VERSION ""

NS_ :

BS_:

BU_: WCM4 WCM3 WCM2 WCM VPM VLM VKM VICM VECM VDM VCU_RTOS_ETH VCU_ENTRY_ETH VCU_AGVM_ETH VCU UVM UPM TIM TEST_TOOL_1 TCP_ETH TCP TCM TCCM SRR_SRR_ETH SRR_SRR SRR_SLR_ETH SRR_SLR SRR_RR SRR_RF_ETH SRR_RF SRR_LR_CR SRR_LF_ETH SRR_LF SIB SDM SCL SBZA_R SBZA_L SBM SAM_RR SAM_RF SAM_LR SAM_LF SAM_BH SADS RadioLow_ETH RadioLow RSI_RTOS_ETH RSI RDCM PTM PLCM PFCM PDR_ETH PDR PCM PA ODS2 ODS NVM MTCM_R MTCM_L MSM_RR MSM_P MSM_LR MSM_D MSB2 MSB1 MRCM_R MRCM_L MFC LRR_RR_ETH LRR_LR_ETH LRR_CF_ETH LRR LRL_CF_ETH LIB_48V LIB1 IPC_INT IPC_GP IPC ICS_Info ICCM HVAC_FP_R HVAC_FP_F HUD_CAN HDLM FPI_RTOS_ETH FPI FOPM FCM_LC FCM EPSb EPS_1 EPSRAb EPSRAa EPS EOCM_HC_Superset EOCM_HCP2 EOCM ELM ECP_X1 ECP_S2 ECP_S ECP_MC ECP_H3 ECP_H2 ECP_H1 ECP_E ECM EBCM DMS DEFC DCM CSM_ETH CSM_AV CSM CGM_OTA_ETH CGM BSM_MH BSM_HEV BSM BCM ARS ARB APA AOS AMP ALC AHS AHL_AFL ADIMb ADIMa ACP2_MCU

BO_ 1415 PDU_2157: 8 CGM
 SG_ ACCDrSlctdSpd : 5|12@0+ (0.0625,0) [0|255.938] "km/h" CSM,CSM_AV,IPC,IPC_INT,VCU
 SG_ ACCAutoStSpStat : 7|2@0+ (1,0) [0|3] "" CSM,CSM_AV,IPC,IPC_INT,VCU
 SG_ ACCSpdLimSgnUnt : 8|1@0+ (1,0) [0|1] "" IPC,IPC_INT,VCU
 SG_ ACCDrSlctdSpdIndOn : 9|1@0+ (1,0) [0|1] "" TCP,CSM,CSM_AV,IPC,IPC_INT,VCU
 SG_ ACCSpdLimSgnVal : 23|8@0+ (1,0) [0|255] "" IPC,IPC_INT,VCU
 SG_ FrwdImpMtgnOpSlctCstCrStVal : 26|3@0+ (1,0) [0|7] "" RadioLow,TCP,CSM,CSM_AV,VCU
 SG_ FrntPCMRspTypCstCrStVal : 29|3@0+ (1,0) [0|7] "" RadioLow,CSM,CSM_AV,VCU
 SG_ ACCSysSlctdMd : 31|2@0+ (1,0) [0|2] "" TCP,IPC,IPC_INT,VCU
 SG_ FrntPCMRspTypCstAvlFlg1 : 32|1@0+ (1,0) [0|1] "" RadioLow,CSM,CSM_AV,VCU
 SG_ AutoEmrgBrkgDsbldIndOn : 33|1@0+ (1,0) [0|1] "" CSM,CSM_AV,IPC,IPC_INT,VCU
 SG_ ACCGoNtfrChmEvntSt : 34|1@0+ (1,0) [0|1] "" IPC,IPC_INT,VCU
 SG_ AnmlWrnIndReq : 36|2@0+ (1,0) [0|2] "" IPC,IPC_INT,VCU
 SG_ FrwdVehAhdIndReq : 39|3@0+ (1,0) [0|5] "" TCP,CSM,CSM_AV,IPC,IPC_INT,VCU
 SG_ FrtPedtrnClsnMtgnAudAttnReqd : 40|1@0+ (1,0) [0|1] "" RadioLow,CSM,CSM_AV,VCU
 SG_ FrntPCMRspTypCstStAvl : 41|1@0+ (1,0) [0|1] "" RadioLow,CSM,CSM_AV,VCU
 SG_ FrntPCMRspTypCstAvlFlg7 : 42|1@0+ (1,0) [0|1] "" RadioLow,CSM,CSM_AV,VCU
 SG_ FrntPCMRspTypCstAvlFlg6 : 43|1@0+ (1,0) [0|1] "" RadioLow,CSM,CSM_AV,VCU
 SG_ FrntPCMRspTypCstAvlFlg5 : 44|1@0+ (1,0) [0|1] "" RadioLow,CSM,CSM_AV,VCU
 SG_ FrntPCMRspTypCstAvlFlg4 : 45|1@0+ (1,0) [0|1] "" RadioLow,CSM,CSM_AV,VCU
 SG_ FrntPCMRspTypCstAvlFlg3 : 46|1@0+ (1,0) [0|1] "" RadioLow,CSM,CSM_AV,VCU
 SG_ FrntPCMRspTypCstAvlFlg2 : 47|1@0+ (1,0) [0|1] "" RadioLow,CSM,CSM_AV,VCU
 SG_ FrwdImpMtgnOpSlctCstAvlFlg7 : 48|1@0+ (1,0) [0|1] "" RadioLow,TCP,CSM,CSM_AV,VCU
 SG_ FrwdImpMtgnOpSlctCstAvlFlg6 : 49|1@0+ (1,0) [0|1] "" RadioLow,TCP,CSM,CSM_AV,VCU
 SG_ FrwdImpMtgnOpSlctCstAvlFlg5 : 50|1@0+ (1,0) [0|1] "" RadioLow,TCP,CSM,CSM_AV,VCU
 SG_ FrwdImpMtgnOpSlctCstAvlFlg4 : 51|1@0+ (1,0) [0|1] "" RadioLow,TCP,CSM,CSM_AV,VCU
 SG_ FrwdImpMtgnOpSlctCstAvlFlg3 : 52|1@0+ (1,0) [0|1] "" RadioLow,TCP,CSM,CSM_AV,VCU
 SG_ FrwdImpMtgnOpSlctCstAvlFlg2 : 53|1@0+ (1,0) [0|1] "" RadioLow,TCP,CSM,CSM_AV,VCU
 SG_ FrwdImpMtgnOpSlctCstAvlFlg1 : 54|1@0+ (1,0) [0|1] "" RadioLow,TCP,CSM,CSM_AV,VCU
 SG_ FrwdClsnAlrtImntAlrtAudAttnReqd : 55|1@0+ (1,0) [0|1] "" RadioLow,CSM,CSM_AV,VCU
 SG_ GoNotfrCstAvlFlg7 : 56|1@0+ (1,0) [0|1] "" RadioLow,CSM,CSM_AV,VCU
 SG_ GoNotfrCstAvlFlg6 : 57|1@0+ (1,0) [0|1] "" RadioLow,CSM,CSM_AV,VCU
 SG_ GoNotfrCstAvlFlg5 : 58|1@0+ (1,0) [0|1] "" RadioLow,CSM,CSM_AV,VCU
 SG_ GoNotfrCstAvlFlg4 : 59|1@0+ (1,0) [0|1] "" RadioLow,CSM,CSM_AV,VCU
 SG_ GoNotfrCstAvlFlg3 : 60|1@0+ (1,0) [0|1] "" RadioLow,CSM,CSM_AV,VCU
 SG_ GoNotfrCstAvlFlg2 : 61|1@0+ (1,0) [0|1] "" RadioLow,CSM,CSM_AV,VCU
 SG_ GoNotfrCstAvlFlg1 : 62|1@0+ (1,0) [0|1] "" RadioLow,CSM,CSM_AV,VCU
 SG_ FrwdImpMtgnOpSlctCstStAvl : 63|1@0+ (1,0) [0|1] "" RadioLow,TCP,CSM,CSM_AV,VCU

BO_ 73 PDU_2226: 6 CGM
 SG_ PrplSysSndEnhtAdjdEngTrqEst : 7|12@0+ (0.5,-848) [-848|1199.5] "Nm" AMP,VCU
 SG_ PrplSysSndEnhtAdjdEngTrqEst_Inv : 11|1@0+ (1,0) [0|1] "" AMP,VCU

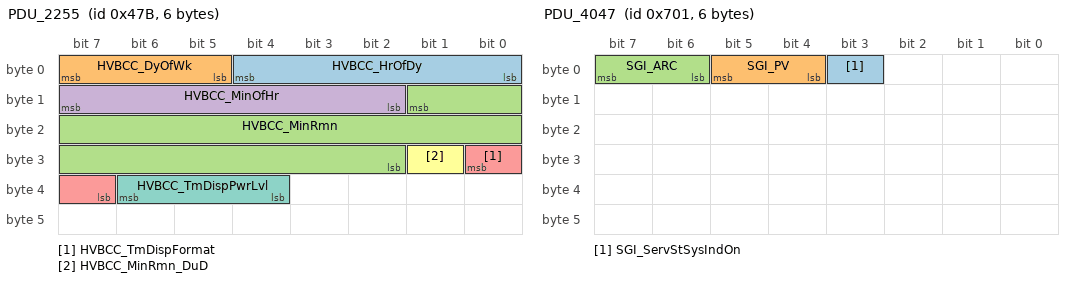
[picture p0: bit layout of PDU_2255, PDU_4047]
BO_ 1147 PDU_2255: 6 CGM
 SG_ HVBCC_HrOfDy : 4|5@0+ (1,0) [0|31] "h" TCP,CSM,CSM_AV,IPC,IPC_INT,VCU
 SG_ HVBCC_DyOfWk : 7|3@0+ (1,0) [0|7] "" TCP,CSM,CSM_AV,IPC,IPC_INT,VCU
 SG_ HVBCC_MinRmn : 9|16@0+ (1,0) [0|65535] "min" TCP,CSM,CSM_AV,IPC,IPC_INT,VCU
 SG_ HVBCC_MinOfHr : 15|6@0+ (1,0) [0|63] "min" TCP,CSM,CSM_AV,IPC,IPC_INT,VCU
 SG_ HVBCC_TmDispFormat : 24|2@0+ (1,0) [0|2] "" CSM,CSM_AV,IPC,IPC_INT,VCU
 SG_ HVBCC_MinRmn_DuD : 25|1@0+ (1,0) [0|1] "" CSM,CSM_AV,IPC,IPC_INT,VCU
 SG_ HVBCC_TmDispPwrLvl : 38|3@0+ (1,0) [0|4] "" TCP,CSM,CSM_AV,IPC,IPC_INT,VCU

BO_ 1349 PDU_2275: 8 CGM
 SG_ ACCAutoSetSpdCstCurrSetVal : 0|3@0+ (1,0) [0|2] "" VCU
 SG_ ACCAutoSetSpdCstAvlFlg7 : 1|1@0+ (1,0) [0|1] "" VCU
 SG_ ACCAutoSetSpdCstAvlFlg6 : 2|1@0+ (1,0) [0|1] "" VCU
 SG_ ACCAutoSetSpdCstAvlFlg5 : 3|1@0+ (1,0) [0|1] "" VCU
 SG_ ACCAutoSetSpdCstAvlFlg4 : 4|1@0+ (1,0) [0|1] "" VCU
 SG_ ACCAutoSetSpdCstAvlFlg3 : 5|1@0+ (1,0) [0|1] "" VCU
 SG_ ACCAutoSetSpdCstAvlFlg2 : 6|1@0+ (1,0) [0|1] "" VCU
 SG_ ACCAutoSetSpdCstAvlFlg1 : 7|1@0+ (1,0) [0|1] "" VCU
 SG_ LnKpAsstVirtCtlLngPrssDctvtnTm : 10|6@0+ (0.1,0) [0|6.3] "seconds" VCU
 SG_ LnKpAsstVirtCtlAval : 11|1@0+ (1,0) [0|1] "" VCU
 SG_ ACCAutoSetSpdUnvIndOn : 12|1@0+ (1,0) [0|1] "" IPC,IPC_INT,VCU
 SG_ ACCAutoSetSpdCstSetAval : 13|1@0+ (1,0) [0|1] "" VCU
 SG_ FCASensCstAvlFlg1 : 16|1@0+ (1,0) [0|1] "" VCU
 SG_ FCASensCstCurrSetVal : 19|3@0+ (1,0) [0|4] "" VCU
 SG_ FCASensCstSetAval : 20|1@0+ (1,0) [0|1] "" VCU
 SG_ BlndZnStrgAsstVirtCtlAval : 24|1@0+ (1,0) [0|1] "" VCU
 SG_ BlndZnStrgAsstVirtUserCtlAllwd : 25|1@0+ (1,0) [0|1] "" VCU
 SG_ FCASensCstAvlFlg7 : 26|1@0+ (1,0) [0|1] "" VCU
 SG_ FCASensCstAvlFlg6 : 27|1@0+ (1,0) [0|1] "" VCU
 SG_ FCASensCstAvlFlg5 : 28|1@0+ (1,0) [0|1] "" VCU
 SG_ FCASensCstAvlFlg4 : 29|1@0+ (1,0) [0|1] "" VCU
 SG_ FCASensCstAvlFlg3 : 30|1@0+ (1,0) [0|1] "" VCU
 SG_ FCASensCstAvlFlg2 : 31|1@0+ (1,0) [0|1] "" VCU
 SG_ TrfcJamAsstVirtCtlAllwd : 33|1@0+ (1,0) [0|1] "" VCU
 SG_ LnDtnWrnSpprssnVrtCtlCurrSltnVl : 35|2@0+ (1,0) [0|2] "" VCU
 SG_ LnDtnWrnSpprssnVirtCtlAval : 36|1@0+ (1,0) [0|1] "" VCU
 SG_ LnDtnWrnSpprssnVirtUserCtlAllwd : 37|1@0+ (1,0) [0|1] "" VCU
 SG_ BlndZnStrgAsstVrtCtlCurrSltnVl : 39|2@0+ (1,0) [0|2] "" VCU

BO_ 2010 PDU_2281: 8 CGM
 SG_ RrStrgModeVirtCtlAval : 6|1@0+ (1,0) [0|1] "" VCU
 SG_ RrStrgModeSmrtCtlIcnReqd : 7|1@0+ (1,0) [0|1] "" VCU

BO_ 1275 PDU_3043: 8 CGM
 SG_ EPBStpOnBrkToRelPrkBrkIndReq : 0|3@0+ (1,0) [0|7] "" CSM,CSM_AV,IPC,IPC_INT,VCU
 SG_ VehStbEnhcmntCustAv : 1|1@0+ (1,0) [0|1] "" TCP,IPC,IPC_INT,VCU
 SG_ VehStbEnhcmntCurStat : 2|1@0+ (1,0) [0|1] "" PDR,TCP,CSM,CSM_AV,IPC,IPC_INT,VCU
 SG_ VehStbCompMdCustAv : 3|1@0+ (1,0) [0|1] "" TCP,IPC,IPC_INT,VCU
 SG_ VehStbCompMdCurStat : 4|1@0+ (1,0) [0|1] "" TCP,IPC,IPC_INT,VCU
 SG_ TrcCntrlSysTmpDisReqIO : 5|1@0+ (1,0) [0|1] "" IPC,IPC_INT,VCU
 SG_ TCSCustAv : 6|1@0+ (1,0) [0|1] "" IPC,IPC_INT,VCU
 SG_ TCSCurStat : 7|1@0+ (1,0) [0|1] "" PDR,TCP,CSM,CSM_AV,IPC,IPC_INT,VCU
 SG_ OffRdMdActvAerodynsVisDispVal : 10|3@0+ (1,0) [0|7] "" RadioLow,CSM,CSM_AV,VCU
 SG_ ElecPrkBrkSysDisIndReq : 13|3@0+ (1,0) [0|7] "" CSM,CSM_AV,IPC,IPC_INT,VCU
 SG_ OffRdMdESCVisDispVal : 17|3@0+ (1,0) [0|7] "" RadioLow,CSM,CSM_AV,VCU
 SG_ OffRdMdDrvlnVisDispVal : 20|3@0+ (1,0) [0|7] "" RadioLow,CSM,CSM_AV,VCU
 SG_ OffRdMdBrkPedVisDispVal : 23|3@0+ (1,0) [0|7] "" RadioLow,CSM,CSM_AV,VCU
 SG_ OffRdMdSndVisDispVal : 24|3@0+ (1,0) [0|7] "" RadioLow,CSM,CSM_AV,VCU
 SG_ OffRdMdRideHghtVisDispVal : 27|3@0+ (1,0) [0|7] "" RadioLow,CSM,CSM_AV,VCU
 SG_ OffRdMdPwrtrnVisDispVal : 30|3@0+ (1,0) [0|7] "" RadioLow,CSM,CSM_AV,VCU
 SG_ OffRdMdStrgVisDispVal : 34|3@0+ (1,0) [0|7] "" RadioLow,CSM,CSM_AV,VCU
 SG_ OffRdMdSpnsnVisDispVal : 37|3@0+ (1,0) [0|7] "" RadioLow,CSM,CSM_AV,VCU
 SG_ ESCInitIO : 40|1@0+ (1,0) [0|1] "" IPC,IPC_INT,VCU
 SG_ ESCCmptMdIO : 41|1@0+ (1,0) [0|1] "" IPC,IPC_INT,VCU
 SG_ TrlrBrkgSysProfSts : 44|3@0+ (1,0) [0|5] "" CSM,CSM_AV,VCU
 SG_ PerfMdMainMenuTy : 47|3@0+ (1,0) [0|7] "" RadioLow,CSM,CSM_AV,VCU
 SG_ TrlrBrkCnctdIndOn : 48|1@0+ (1,0) [0|1] "" IPC,IPC_INT,VCU
 SG_ SrvESCMdIO : 49|1@0+ (1,0) [0|1] "" TCP,IPC,IPC_INT,VCU
 SG_ ServTracCtlIndOn : 50|1@0+ (1,0) [0|1] "" TCP,IPC,IPC_INT,VCU
 SG_ RdcBrkgToAvoidOvrhtgIndOn : 51|1@0+ (1,0) [0|1] "" IPC,IPC_INT,VCU
 SG_ HillStrtAstActIO : 52|1@0+ (1,0) [0|1] "" CSM,CSM_AV,IPC,IPC_INT,VCU
 SG_ HillRollCntrlActIO : 53|1@0+ (1,0) [0|1] "" CSM,CSM_AV,IPC,IPC_INT,VCU
 SG_ ESCPrfMdIO : 54|1@0+ (1,0) [0|1] "" IPC,IPC_INT,VCU
 SG_ ESCOffIO : 55|1@0+ (1,0) [0|1] "" CSM,CSM_AV,IPC,IPC_INT,VCU
 SG_ BrkSysDrftModeUnvWrnIndReq : 60|2@0+ (1,0) [0|2] "" IPC,IPC_INT,VCU
 SG_ BrkSysDrftModeDispSts : 62|2@0+ (1,0) [0|3] "" IPC,IPC_INT,VCU
 SG_ BrkSysDrftModeSeltnIndOn : 63|1@0+ (1,0) [0|1] "" IPC,IPC_INT,VCU

BO_ 1274 PDU_3044: 8 CGM
 SG_ BrkPadLifeFrt : 6|7@0+ (1,0) [0|127] "%" TCP,VKM,CSM,CSM_AV,IPC,IPC_INT,VCU
 SG_ BrkPadLifeFrt_Inv : 7|1@0+ (1,0) [0|1] "" TCP,VKM,CSM,CSM_AV,IPC,IPC_INT,VCU
 SG_ BrkPadLifeRr : 14|7@0+ (1,0) [0|127] "%" TCP,VKM,CSM,CSM_AV,IPC,IPC_INT,VCU
 SG_ BrkPadLifeRr_Inv : 15|1@0+ (1,0) [0|1] "" TCP,VKM,CSM,CSM_AV,IPC,IPC_INT,VCU
 SG_ TowHaulMdBrkPedVisDispVal : 17|3@0+ (1,0) [0|7] "" RadioLow,CSM,CSM_AV,VCU
 SG_ TowHaulMdActvAerodynsVisDispVal : 20|3@0+ (1,0) [0|7] "" RadioLow,CSM,CSM_AV,VCU
 SG_ BrkTempStsIndReq : 23|3@0+ (1,0) [0|4] "" IPC,IPC_INT,VCU
 SG_ TowHaulMdPwrtrnVisDispVal : 24|3@0+ (1,0) [0|7] "" RadioLow,CSM,CSM_AV,VCU
 SG_ TowHaulMdESCVisDispVal : 27|3@0+ (1,0) [0|7] "" RadioLow,CSM,CSM_AV,VCU
 SG_ TowHaulMdDrvlnVisDispVal : 30|3@0+ (1,0) [0|7] "" RadioLow,CSM,CSM_AV,VCU
 SG_ TowHaulMdSndVisDispVal : 34|3@0+ (1,0) [0|7] "" RadioLow,CSM,CSM_AV,VCU
 SG_ TowHaulMdRideHghtVisDispVal : 37|3@0+ (1,0) [0|7] "" RadioLow,CSM,CSM_AV,VCU
 SG_ AutoHldActv : 40|1@0+ (1,0) [0|1] "" IPC,IPC_INT,VCU
 SG_ ABSActvIndOn : 41|1@0+ (1,0) [0|1] "" TCP,CSM,CSM_AV,IPC,IPC_INT,VCU
 SG_ TowHaulMdStrgVisDispVal : 44|3@0+ (1,0) [0|7] "" RadioLow,CSM,CSM_AV,VCU
 SG_ TowHaulMdSpnsnVisDispVal : 47|3@0+ (1,0) [0|7] "" RadioLow,CSM,CSM_AV,VCU
 SG_ BrkPadLifeRrRstAval : 50|1@0+ (1,0) [0|1] "" IPC,IPC_INT,VCU
 SG_ BrkPadLifeFrtRstAval : 51|1@0+ (1,0) [0|1] "" IPC,IPC_INT,VCU
 SG_ AutoHldServIndOn : 52|1@0+ (1,0) [0|1] "" IPC,IPC_INT,VCU
 SG_ AutoHldDsbldStBltIndOn : 53|1@0+ (1,0) [0|1] "" IPC,IPC_INT,VCU
 SG_ AutoHldDsbldDrOpnIndOn : 54|1@0+ (1,0) [0|1] "" IPC,IPC_INT,VCU
 SG_ AutoHldAppBrkPedIndOn : 55|1@0+ (1,0) [0|1] "" IPC,IPC_INT,VCU

BO_ 1491 PDU_3045: 8 CGM
 SG_ CustMdDrvlCstmCurSetVal : 1|3@0+ (1,0) [0|7] "" RadioLow,TCP,CSM,CSM_AV,VCU
 SG_ CustMdBrkPdlCstmCurSetVal : 4|3@0+ (1,0) [0|7] "" RadioLow,CSM,CSM_AV,VCU
 SG_ CustMdActAeroCstmCurSetVal : 7|3@0+ (1,0) [0|7] "" RadioLow,CSM,CSM_AV,VCU
 SG_ CustMdRideHghtCstmCurSetVal : 8|3@0+ (1,0) [0|7] "" RadioLow,CSM,CSM_AV,VCU
 SG_ CustMdPTCstmPndSetVal : 11|3@0+ (1,0) [0|7] "" RadioLow,CSM,CSM_AV,VCU
 SG_ CustMdPTCstmCurSetVal : 14|3@0+ (1,0) [0|7] "" RadioLow,CSM,CSM_AV,VCU
 SG_ CustMdSpnCstmCurSetVal : 18|3@0+ (1,0) [0|7] "" RadioLow,TCP,CSM,CSM_AV,VCU
 SG_ CustMdSndCstmCurSetVal : 21|3@0+ (1,0) [0|7] "" RadioLow,CSM,CSM_AV,VCU
 SG_ DisPrfMdRq : 25|3@0+ (1,0) [0|7] "" IPC,IPC_INT,VCU
 SG_ CustMdTrcStbCstmCurSetVal : 28|3@0+ (1,0) [0|7] "" RadioLow,CSM,CSM_AV,VCU
 SG_ CustMdStrCstmCurSetVal : 31|3@0+ (1,0) [0|7] "" RadioLow,TCP,CSM,CSM_AV,VCU
 SG_ PrsnlMdBrkPdlCstmCurSetVal : 32|3@0+ (1,0) [0|7] "" RadioLow,CSM,CSM_AV,VCU
 SG_ PrsnlMdActAeroCstmCurSetVal : 35|3@0+ (1,0) [0|7] "" RadioLow,CSM,CSM_AV,VCU
 SG_ ExtdHillStrtAstCustCurSetVal : 38|3@0+ (1,0) [0|7] "" RadioLow,CSM,CSM_AV,VCU
 SG_ PrsnlMdRideHghtCstmCurSetVal : 42|3@0+ (1,0) [0|7] "" RadioLow,CSM,CSM_AV,VCU
 SG_ PrsnlMdDrvlCstmCurSetVal : 45|3@0+ (1,0) [0|7] "" RadioLow,TCP,CSM,CSM_AV,VCU
 SG_ CustMdStrCstmSetAv : 48|1@0+ (1,0) [0|1] "" RadioLow,TCP,CSM,CSM_AV,VCU
 SG_ CustMdSpnCstmSetAv : 49|1@0+ (1,0) [0|1] "" RadioLow,TCP,CSM,CSM_AV,VCU
 SG_ CustMdSndCstmSetAv : 50|1@0+ (1,0) [0|1] "" RadioLow,CSM,CSM_AV,VCU
 SG_ CustMdRideHghtCstmSetAv : 51|1@0+ (1,0) [0|1] "" RadioLow,CSM,CSM_AV,VCU
 SG_ CustMdPTCstmSetAv : 52|1@0+ (1,0) [0|1] "" RadioLow,CSM,CSM_AV,VCU
 SG_ CustMdDrvlCstmSetAv : 53|1@0+ (1,0) [0|1] "" RadioLow,TCP,CSM,CSM_AV,VCU
 SG_ CustMdBrkPdlCstmSetAv : 54|1@0+ (1,0) [0|1] "" RadioLow,CSM,CSM_AV,VCU
 SG_ CustMdActAeroCstmSetAv : 55|1@0+ (1,0) [0|1] "" RadioLow,CSM,CSM_AV,VCU
 SG_ PrsnlMdSpnCstmSetAv : 56|1@0+ (1,0) [0|1] "" RadioLow,TCP,CSM,CSM_AV,VCU
 SG_ PrsnlMdSndCstmSetAv : 57|1@0+ (1,0) [0|1] "" RadioLow,CSM,CSM_AV,VCU
 SG_ PrsnlMdRideHghtCstmSetAv : 58|1@0+ (1,0) [0|1] "" RadioLow,CSM,CSM_AV,VCU
 SG_ PrsnlMdDrvlCstmSetAv : 59|1@0+ (1,0) [0|1] "" RadioLow,TCP,CSM,CSM_AV,VCU
 SG_ PrsnlMdBrkPdlCstmSetAv : 60|1@0+ (1,0) [0|1] "" RadioLow,CSM,CSM_AV,VCU
 SG_ PrsnlMdActAeroCstmSetAv : 61|1@0+ (1,0) [0|1] "" RadioLow,CSM,CSM_AV,VCU
 SG_ ExtdHillStrtAstCustSetAvl : 62|1@0+ (1,0) [0|1] "" RadioLow,CSM,CSM_AV,VCU
 SG_ CustMdTrcStbCstmSetAv : 63|1@0+ (1,0) [0|1] "" RadioLow,CSM,CSM_AV,VCU

BO_ 1882 PDU_3054: 8 CGM
 SG_ CustMdBrkPdlCstmAvFlg1 : 0|1@0+ (1,0) [0|1] "" RadioLow,CSM,CSM_AV,VCU
 SG_ CustMdActAeroCstmAvFlg7 : 1|1@0+ (1,0) [0|1] "" RadioLow,CSM,CSM_AV,VCU
 SG_ CustMdActAeroCstmAvFlg6 : 2|1@0+ (1,0) [0|1] "" RadioLow,CSM,CSM_AV,VCU
 SG_ CustMdActAeroCstmAvFlg5 : 3|1@0+ (1,0) [0|1] "" RadioLow,CSM,CSM_AV,VCU
 SG_ CustMdActAeroCstmAvFlg4 : 4|1@0+ (1,0) [0|1] "" RadioLow,CSM,CSM_AV,VCU
 SG_ CustMdActAeroCstmAvFlg3 : 5|1@0+ (1,0) [0|1] "" RadioLow,CSM,CSM_AV,VCU
 SG_ CustMdActAeroCstmAvFlg2 : 6|1@0+ (1,0) [0|1] "" RadioLow,CSM,CSM_AV,VCU
 SG_ CustMdActAeroCstmAvFlg1 : 7|1@0+ (1,0) [0|1] "" RadioLow,CSM,CSM_AV,VCU
 SG_ CustMdDrvlCstmAvFlg2 : 8|1@0+ (1,0) [0|1] "" RadioLow,TCP,CSM,CSM_AV,VCU
 SG_ CustMdDrvlCstmAvFlg1 : 9|1@0+ (1,0) [0|1] "" RadioLow,TCP,CSM,CSM_AV,VCU
 SG_ CustMdBrkPdlCstmAvFlg7 : 10|1@0+ (1,0) [0|1] "" RadioLow,CSM,CSM_AV,VCU
 SG_ CustMdBrkPdlCstmAvFlg6 : 11|1@0+ (1,0) [0|1] "" RadioLow,CSM,CSM_AV,VCU
 SG_ CustMdBrkPdlCstmAvFlg5 : 12|1@0+ (1,0) [0|1] "" RadioLow,CSM,CSM_AV,VCU
 SG_ CustMdBrkPdlCstmAvFlg4 : 13|1@0+ (1,0) [0|1] "" RadioLow,CSM,CSM_AV,VCU
 SG_ CustMdBrkPdlCstmAvFlg3 : 14|1@0+ (1,0) [0|1] "" RadioLow,CSM,CSM_AV,VCU
 SG_ CustMdBrkPdlCstmAvFlg2 : 15|1@0+ (1,0) [0|1] "" RadioLow,CSM,CSM_AV,VCU
 SG_ CustMdPTCstmAvFlg3 : 16|1@0+ (1,0) [0|1] "" RadioLow,CSM,CSM_AV,VCU
 SG_ CustMdPTCstmAvFlg2 : 17|1@0+ (1,0) [0|1] "" RadioLow,CSM,CSM_AV,VCU
 SG_ CustMdPTCstmAvFlg1 : 18|1@0+ (1,0) [0|1] "" RadioLow,CSM,CSM_AV,VCU
 SG_ CustMdDrvlCstmAvFlg7 : 19|1@0+ (1,0) [0|1] "" RadioLow,TCP,CSM,CSM_AV,VCU
 SG_ CustMdDrvlCstmAvFlg6 : 20|1@0+ (1,0) [0|1] "" RadioLow,TCP,CSM,CSM_AV,VCU
 SG_ CustMdDrvlCstmAvFlg5 : 21|1@0+ (1,0) [0|1] "" RadioLow,TCP,CSM,CSM_AV,VCU
 SG_ CustMdDrvlCstmAvFlg4 : 22|1@0+ (1,0) [0|1] "" RadioLow,TCP,CSM,CSM_AV,VCU
 SG_ CustMdDrvlCstmAvFlg3 : 23|1@0+ (1,0) [0|1] "" RadioLow,TCP,CSM,CSM_AV,VCU
 SG_ CustMdRideHghtCstmAvFlg4 : 24|1@0+ (1,0) [0|1] "" RadioLow,CSM,CSM_AV,VCU
 SG_ CustMdRideHghtCstmAvFlg3 : 25|1@0+ (1,0) [0|1] "" RadioLow,CSM,CSM_AV,VCU
 SG_ CustMdRideHghtCstmAvFlg2 : 26|1@0+ (1,0) [0|1] "" RadioLow,CSM,CSM_AV,VCU
 SG_ CustMdRideHghtCstmAvFlg1 : 27|1@0+ (1,0) [0|1] "" RadioLow,CSM,CSM_AV,VCU
 SG_ CustMdPTCstmAvFlg7 : 28|1@0+ (1,0) [0|1] "" RadioLow,CSM,CSM_AV,VCU
 SG_ CustMdPTCstmAvFlg6 : 29|1@0+ (1,0) [0|1] "" RadioLow,CSM,CSM_AV,VCU
 SG_ CustMdPTCstmAvFlg5 : 30|1@0+ (1,0) [0|1] "" RadioLow,CSM,CSM_AV,VCU
 SG_ CustMdPTCstmAvFlg4 : 31|1@0+ (1,0) [0|1] "" RadioLow,CSM,CSM_AV,VCU
 SG_ CustMdSndCstmAvFlg5 : 32|1@0+ (1,0) [0|1] "" RadioLow,CSM,CSM_AV,VCU
 SG_ CustMdSndCstmAvFlg4 : 33|1@0+ (1,0) [0|1] "" RadioLow,CSM,CSM_AV,VCU
 SG_ CustMdSndCstmAvFlg3 : 34|1@0+ (1,0) [0|1] "" RadioLow,CSM,CSM_AV,VCU
 SG_ CustMdSndCstmAvFlg2 : 35|1@0+ (1,0) [0|1] "" RadioLow,CSM,CSM_AV,VCU
 SG_ CustMdSndCstmAvFlg1 : 36|1@0+ (1,0) [0|1] "" RadioLow,CSM,CSM_AV,VCU
 SG_ CustMdRideHghtCstmAvFlg7 : 37|1@0+ (1,0) [0|1] "" RadioLow,CSM,CSM_AV,VCU
 SG_ CustMdRideHghtCstmAvFlg6 : 38|1@0+ (1,0) [0|1] "" RadioLow,CSM,CSM_AV,VCU
 SG_ CustMdRideHghtCstmAvFlg5 : 39|1@0+ (1,0) [0|1] "" RadioLow,CSM,CSM_AV,VCU
 SG_ CustMdSpnCstmAvFlg6 : 40|1@0+ (1,0) [0|1] "" RadioLow,TCP,CSM,CSM_AV,VCU
 SG_ CustMdSpnCstmAvFlg5 : 41|1@0+ (1,0) [0|1] "" RadioLow,TCP,CSM,CSM_AV,VCU
 SG_ CustMdSpnCstmAvFlg4 : 42|1@0+ (1,0) [0|1] "" RadioLow,TCP,CSM,CSM_AV,VCU
 SG_ CustMdSpnCstmAvFlg3 : 43|1@0+ (1,0) [0|1] "" RadioLow,TCP,CSM,CSM_AV,VCU
 SG_ CustMdSpnCstmAvFlg2 : 44|1@0+ (1,0) [0|1] "" RadioLow,TCP,CSM,CSM_AV,VCU
 SG_ CustMdSpnCstmAvFlg1 : 45|1@0+ (1,0) [0|1] "" RadioLow,TCP,CSM,CSM_AV,VCU
 SG_ CustMdSndCstmAvFlg7 : 46|1@0+ (1,0) [0|1] "" RadioLow,CSM,CSM_AV,VCU
 SG_ CustMdSndCstmAvFlg6 : 47|1@0+ (1,0) [0|1] "" RadioLow,CSM,CSM_AV,VCU
 SG_ CustMdStrCstmAvFlg7 : 48|1@0+ (1,0) [0|1] "" RadioLow,TCP,CSM,CSM_AV,VCU
 SG_ CustMdStrCstmAvFlg6 : 49|1@0+ (1,0) [0|1] "" RadioLow,TCP,CSM,CSM_AV,VCU
 SG_ CustMdStrCstmAvFlg5 : 50|1@0+ (1,0) [0|1] "" RadioLow,TCP,CSM,CSM_AV,VCU
 SG_ CustMdStrCstmAvFlg4 : 51|1@0+ (1,0) [0|1] "" RadioLow,TCP,CSM,CSM_AV,VCU
 SG_ CustMdStrCstmAvFlg3 : 52|1@0+ (1,0) [0|1] "" RadioLow,TCP,CSM,CSM_AV,VCU
 SG_ CustMdStrCstmAvFlg2 : 53|1@0+ (1,0) [0|1] "" RadioLow,TCP,CSM,CSM_AV,VCU
 SG_ CustMdStrCstmAvFlg1 : 54|1@0+ (1,0) [0|1] "" RadioLow,TCP,CSM,CSM_AV,VCU
 SG_ CustMdSpnCstmAvFlg7 : 55|1@0+ (1,0) [0|1] "" RadioLow,TCP,CSM,CSM_AV,VCU
 SG_ EBDFld : 56|1@0+ (1,0) [0|1] "" CSM,CSM_AV,VCU
 SG_ CustMdTrcStbCstmAvFlg7 : 57|1@0+ (1,0) [0|1] "" RadioLow,CSM,CSM_AV,VCU
 SG_ CustMdTrcStbCstmAvFlg6 : 58|1@0+ (1,0) [0|1] "" RadioLow,CSM,CSM_AV,VCU
 SG_ CustMdTrcStbCstmAvFlg5 : 59|1@0+ (1,0) [0|1] "" RadioLow,CSM,CSM_AV,VCU
 SG_ CustMdTrcStbCstmAvFlg4 : 60|1@0+ (1,0) [0|1] "" RadioLow,CSM,CSM_AV,VCU
 SG_ CustMdTrcStbCstmAvFlg3 : 61|1@0+ (1,0) [0|1] "" RadioLow,CSM,CSM_AV,VCU
 SG_ CustMdTrcStbCstmAvFlg2 : 62|1@0+ (1,0) [0|1] "" RadioLow,CSM,CSM_AV,VCU
 SG_ CustMdTrcStbCstmAvFlg1 : 63|1@0+ (1,0) [0|1] "" RadioLow,CSM,CSM_AV,VCU

BO_ 1183 PDU_3055: 8 CGM
 SG_ PrsnlMdActAeroCstmAvFlg1 : 0|1@0+ (1,0) [0|1] "" RadioLow,CSM,CSM_AV,VCU
 SG_ ExtdHillStrtAstCustAvlFlg7 : 1|1@0+ (1,0) [0|1] "" RadioLow,CSM,CSM_AV,VCU
 SG_ ExtdHillStrtAstCustAvlFlg6 : 2|1@0+ (1,0) [0|1] "" RadioLow,CSM,CSM_AV,VCU
 SG_ ExtdHillStrtAstCustAvlFlg5 : 3|1@0+ (1,0) [0|1] "" RadioLow,CSM,CSM_AV,VCU
 SG_ ExtdHillStrtAstCustAvlFlg4 : 4|1@0+ (1,0) [0|1] "" RadioLow,CSM,CSM_AV,VCU
 SG_ ExtdHillStrtAstCustAvlFlg3 : 5|1@0+ (1,0) [0|1] "" RadioLow,CSM,CSM_AV,VCU
 SG_ ExtdHillStrtAstCustAvlFlg2 : 6|1@0+ (1,0) [0|1] "" RadioLow,CSM,CSM_AV,VCU
 SG_ ExtdHillStrtAstCustAvlFlg1 : 7|1@0+ (1,0) [0|1] "" RadioLow,CSM,CSM_AV,VCU
 SG_ PrsnlMdBrkPdlCstmAvFlg2 : 8|1@0+ (1,0) [0|1] "" RadioLow,CSM,CSM_AV,VCU
 SG_ PrsnlMdBrkPdlCstmAvFlg1 : 9|1@0+ (1,0) [0|1] "" RadioLow,CSM,CSM_AV,VCU
 SG_ PrsnlMdActAeroCstmAvFlg7 : 10|1@0+ (1,0) [0|1] "" RadioLow,CSM,CSM_AV,VCU
 SG_ PrsnlMdActAeroCstmAvFlg6 : 11|1@0+ (1,0) [0|1] "" RadioLow,CSM,CSM_AV,VCU
 SG_ PrsnlMdActAeroCstmAvFlg5 : 12|1@0+ (1,0) [0|1] "" RadioLow,CSM,CSM_AV,VCU
 SG_ PrsnlMdActAeroCstmAvFlg4 : 13|1@0+ (1,0) [0|1] "" RadioLow,CSM,CSM_AV,VCU
 SG_ PrsnlMdActAeroCstmAvFlg3 : 14|1@0+ (1,0) [0|1] "" RadioLow,CSM,CSM_AV,VCU
 SG_ PrsnlMdActAeroCstmAvFlg2 : 15|1@0+ (1,0) [0|1] "" RadioLow,CSM,CSM_AV,VCU
 SG_ PrsnlMdDrvlCstmAvFlg3 : 16|1@0+ (1,0) [0|1] "" RadioLow,TCP,CSM,CSM_AV,VCU
 SG_ PrsnlMdDrvlCstmAvFlg2 : 17|1@0+ (1,0) [0|1] "" RadioLow,TCP,CSM,CSM_AV,VCU
 SG_ PrsnlMdDrvlCstmAvFlg1 : 18|1@0+ (1,0) [0|1] "" RadioLow,TCP,CSM,CSM_AV,VCU
 SG_ PrsnlMdBrkPdlCstmAvFlg7 : 19|1@0+ (1,0) [0|1] "" RadioLow,CSM,CSM_AV,VCU
 SG_ PrsnlMdBrkPdlCstmAvFlg6 : 20|1@0+ (1,0) [0|1] "" RadioLow,CSM,CSM_AV,VCU
 SG_ PrsnlMdBrkPdlCstmAvFlg5 : 21|1@0+ (1,0) [0|1] "" RadioLow,CSM,CSM_AV,VCU
 SG_ PrsnlMdBrkPdlCstmAvFlg4 : 22|1@0+ (1,0) [0|1] "" RadioLow,CSM,CSM_AV,VCU
 SG_ PrsnlMdBrkPdlCstmAvFlg3 : 23|1@0+ (1,0) [0|1] "" RadioLow,CSM,CSM_AV,VCU
 SG_ PrsnlMdRideHghtCstmAvFlg4 : 24|1@0+ (1,0) [0|1] "" RadioLow,CSM,CSM_AV,VCU
 SG_ PrsnlMdRideHghtCstmAvFlg3 : 25|1@0+ (1,0) [0|1] "" RadioLow,CSM,CSM_AV,VCU
 SG_ PrsnlMdRideHghtCstmAvFlg2 : 26|1@0+ (1,0) [0|1] "" RadioLow,CSM,CSM_AV,VCU
 SG_ PrsnlMdRideHghtCstmAvFlg1 : 27|1@0+ (1,0) [0|1] "" RadioLow,CSM,CSM_AV,VCU
 SG_ PrsnlMdDrvlCstmAvFlg7 : 28|1@0+ (1,0) [0|1] "" RadioLow,TCP,CSM,CSM_AV,VCU
 SG_ PrsnlMdDrvlCstmAvFlg6 : 29|1@0+ (1,0) [0|1] "" RadioLow,TCP,CSM,CSM_AV,VCU
 SG_ PrsnlMdDrvlCstmAvFlg5 : 30|1@0+ (1,0) [0|1] "" RadioLow,TCP,CSM,CSM_AV,VCU
 SG_ PrsnlMdDrvlCstmAvFlg4 : 31|1@0+ (1,0) [0|1] "" RadioLow,TCP,CSM,CSM_AV,VCU
 SG_ PrsnlMdSndCstmAvFlg5 : 32|1@0+ (1,0) [0|1] "" RadioLow,CSM,CSM_AV,VCU
 SG_ PrsnlMdSndCstmAvFlg4 : 33|1@0+ (1,0) [0|1] "" RadioLow,CSM,CSM_AV,VCU
 SG_ PrsnlMdSndCstmAvFlg3 : 34|1@0+ (1,0) [0|1] "" RadioLow,CSM,CSM_AV,VCU
 SG_ PrsnlMdSndCstmAvFlg2 : 35|1@0+ (1,0) [0|1] "" RadioLow,CSM,CSM_AV,VCU
 SG_ PrsnlMdSndCstmAvFlg1 : 36|1@0+ (1,0) [0|1] "" RadioLow,CSM,CSM_AV,VCU
 SG_ PrsnlMdRideHghtCstmAvFlg7 : 37|1@0+ (1,0) [0|1] "" RadioLow,CSM,CSM_AV,VCU
 SG_ PrsnlMdRideHghtCstmAvFlg6 : 38|1@0+ (1,0) [0|1] "" RadioLow,CSM,CSM_AV,VCU
 SG_ PrsnlMdRideHghtCstmAvFlg5 : 39|1@0+ (1,0) [0|1] "" RadioLow,CSM,CSM_AV,VCU
 SG_ PrsnlMdSpnCstmAvFlg6 : 40|1@0+ (1,0) [0|1] "" RadioLow,TCP,CSM,CSM_AV,VCU
 SG_ PrsnlMdSpnCstmAvFlg5 : 41|1@0+ (1,0) [0|1] "" RadioLow,TCP,CSM,CSM_AV,VCU
 SG_ PrsnlMdSpnCstmAvFlg4 : 42|1@0+ (1,0) [0|1] "" RadioLow,TCP,CSM,CSM_AV,VCU
 SG_ PrsnlMdSpnCstmAvFlg3 : 43|1@0+ (1,0) [0|1] "" RadioLow,TCP,CSM,CSM_AV,VCU
 SG_ PrsnlMdSpnCstmAvFlg2 : 44|1@0+ (1,0) [0|1] "" RadioLow,TCP,CSM,CSM_AV,VCU
 SG_ PrsnlMdSpnCstmAvFlg1 : 45|1@0+ (1,0) [0|1] "" RadioLow,TCP,CSM,CSM_AV,VCU
 SG_ PrsnlMdSndCstmAvFlg7 : 46|1@0+ (1,0) [0|1] "" RadioLow,CSM,CSM_AV,VCU
 SG_ PrsnlMdSndCstmAvFlg6 : 47|1@0+ (1,0) [0|1] "" RadioLow,CSM,CSM_AV,VCU
 SG_ PrsnlMdStrCstmAvFlg7 : 48|1@0+ (1,0) [0|1] "" RadioLow,TCP,CSM,CSM_AV,VCU
 SG_ PrsnlMdStrCstmAvFlg6 : 49|1@0+ (1,0) [0|1] "" RadioLow,TCP,CSM,CSM_AV,VCU
 SG_ PrsnlMdStrCstmAvFlg5 : 50|1@0+ (1,0) [0|1] "" RadioLow,TCP,CSM,CSM_AV,VCU
 SG_ PrsnlMdStrCstmAvFlg4 : 51|1@0+ (1,0) [0|1] "" RadioLow,TCP,CSM,CSM_AV,VCU
 SG_ PrsnlMdStrCstmAvFlg3 : 52|1@0+ (1,0) [0|1] "" RadioLow,TCP,CSM,CSM_AV,VCU
 SG_ PrsnlMdStrCstmAvFlg2 : 53|1@0+ (1,0) [0|1] "" RadioLow,TCP,CSM,CSM_AV,VCU
 SG_ PrsnlMdStrCstmAvFlg1 : 54|1@0+ (1,0) [0|1] "" RadioLow,TCP,CSM,CSM_AV,VCU
 SG_ PrsnlMdSpnCstmAvFlg7 : 55|1@0+ (1,0) [0|1] "" RadioLow,TCP,CSM,CSM_AV,VCU

BO_ 1075 PDU_3089: 8 CGM
 SG_ DslExhFldTmToIndcmt : 7|12@0+ (1,0) [0|4095] "min" IPC,IPC_INT,VCU

BO_ 1932 PDU_3091: 8 CGM
 SG_ RdHgtWrn3IndReq : 7|4@0+ (1,0) [0|4] "" VCU

BO_ 1793 PDU_4047: 6 CGM
 SG_ SGI_ServStSysIndOn : 3|1@0+ (1,0) [0|1] "" TCP,IPC,IPC_INT,VCU
 SG_ SGI_PV : 5|2@0+ (1,0) [0|3] "" IPC,IPC_INT,VCU
 SG_ SGI_ARC : 7|2@0+ (1,0) [0|3] "" IPC,IPC_INT,VCU

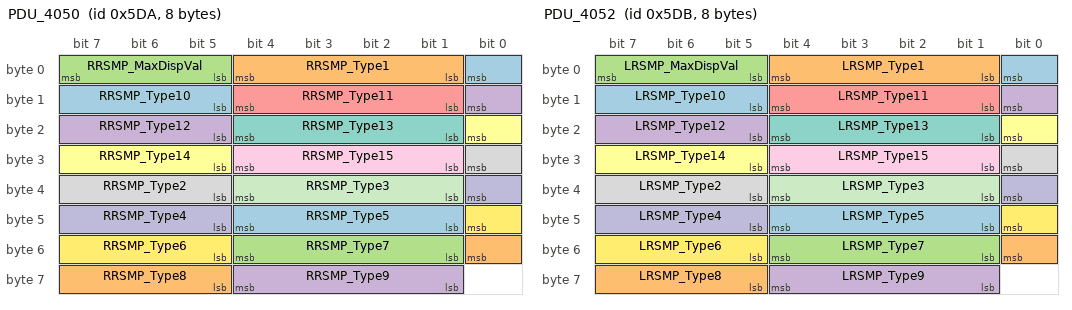
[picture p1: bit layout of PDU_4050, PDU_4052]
BO_ 1498 PDU_4050: 8 CGM
 SG_ RRSMP_Type10 : 0|4@0+ (1,0) [0|15] "" RadioLow,CSM,CSM_AV,VCU
 SG_ RRSMP_Type1 : 4|4@0+ (1,0) [0|15] "" RadioLow,CSM,CSM_AV,VCU
 SG_ RRSMP_MaxDispVal : 7|3@0+ (1,0) [0|7] "" RadioLow,CSM,CSM_AV,VCU
 SG_ RRSMP_Type12 : 8|4@0+ (1,0) [0|15] "" RadioLow,CSM,CSM_AV,VCU
 SG_ RRSMP_Type11 : 12|4@0+ (1,0) [0|15] "" RadioLow,CSM,CSM_AV,VCU
 SG_ RRSMP_Type14 : 16|4@0+ (1,0) [0|15] "" RadioLow,CSM,CSM_AV,VCU
 SG_ RRSMP_Type13 : 20|4@0+ (1,0) [0|15] "" RadioLow,CSM,CSM_AV,VCU
 SG_ RRSMP_Type2 : 24|4@0+ (1,0) [0|15] "" RadioLow,CSM,CSM_AV,VCU
 SG_ RRSMP_Type15 : 28|4@0+ (1,0) [0|15] "" RadioLow,CSM,CSM_AV,VCU
 SG_ RRSMP_Type4 : 32|4@0+ (1,0) [0|15] "" RadioLow,CSM,CSM_AV,VCU
 SG_ RRSMP_Type3 : 36|4@0+ (1,0) [0|15] "" RadioLow,CSM,CSM_AV,VCU
 SG_ RRSMP_Type6 : 40|4@0+ (1,0) [0|15] "" RadioLow,CSM,CSM_AV,VCU
 SG_ RRSMP_Type5 : 44|4@0+ (1,0) [0|15] "" RadioLow,CSM,CSM_AV,VCU
 SG_ RRSMP_Type8 : 48|4@0+ (1,0) [0|15] "" RadioLow,CSM,CSM_AV,VCU
 SG_ RRSMP_Type7 : 52|4@0+ (1,0) [0|15] "" RadioLow,CSM,CSM_AV,VCU
 SG_ RRSMP_Type9 : 60|4@0+ (1,0) [0|15] "" RadioLow,CSM,CSM_AV,VCU

BO_ 1809 PDU_4051: 8 CGM
 SG_ RRSAP_BkCshBlstrInOut : 3|4@0+ (1,0) [0|15] "" RadioLow,CSM,CSM_AV,VCU
 SG_ RRSAP_BkBlstrInOut : 7|4@0+ (1,0) [0|15] "" RadioLow,CSM,CSM_AV,VCU
 SG_ RRSAP_CshLgthAdjFdRr : 11|4@0+ (1,0) [0|15] "" RadioLow,CSM,CSM_AV,VCU
 SG_ RRSAP_CshBlstrInOut : 15|4@0+ (1,0) [0|15] "" RadioLow,CSM,CSM_AV,VCU
 SG_ RRSAP_HdrstTltFwdRr : 19|4@0+ (1,0) [0|15] "" RadioLow,CSM,CSM_AV,VCU
 SG_ RRSAP_HdrstFwdRrwd : 23|4@0+ (1,0) [0|15] "" RadioLow,CSM,CSM_AV,VCU
 SG_ RRSAP_HdrstUpDnFdRr : 27|4@0+ (1,0) [0|15] "" RadioLow,CSM,CSM_AV,VCU
 SG_ RRSAP_HdrstUpDn : 31|4@0+ (1,0) [0|15] "" RadioLow,CSM,CSM_AV,VCU
 SG_ RRSAP_LmbrFwdRr : 35|4@0+ (1,0) [0|15] "" RadioLow,CSM,CSM_AV,VCU
 SG_ RRSAP_HdrstWngsInOut : 39|4@0+ (1,0) [0|15] "" RadioLow,CSM,CSM_AV,VCU
 SG_ RRSAP_LmbrUpDwn : 43|4@0+ (1,0) [0|15] "" RadioLow,CSM,CSM_AV,VCU
 SG_ RRSAP_LmbrUpDnFdRr : 47|4@0+ (1,0) [0|15] "" RadioLow,CSM,CSM_AV,VCU
 SG_ RRSAP_UprShldrFwdRr : 51|4@0+ (1,0) [0|15] "" RadioLow,CSM,CSM_AV,VCU
 SG_ RRSAP_Massg : 55|4@0+ (1,0) [0|15] "" RadioLow,CSM,CSM_AV,VCU
 SG_ StLckoutRRCtlCurrSet : 60|2@0+ (1,0) [0|2] "" VCU
 SG_ StLckoutRRVirtCtlAval : 61|1@0+ (1,0) [0|1] "" VCU
 SG_ StMemRRVirtCtlStorAllwd : 62|1@0+ (1,0) [0|1] "" VCU
 SG_ StMemRRVirtCtlRclAllwd : 63|1@0+ (1,0) [0|1] "" VCU

BO_ 1499 PDU_4052: 8 CGM
 SG_ LRSMP_Type10 : 0|4@0+ (1,0) [0|15] "" RadioLow,CSM,CSM_AV,VCU
 SG_ LRSMP_Type1 : 4|4@0+ (1,0) [0|15] "" RadioLow,CSM,CSM_AV,VCU
 SG_ LRSMP_MaxDispVal : 7|3@0+ (1,0) [0|7] "" RadioLow,CSM,CSM_AV,VCU
 SG_ LRSMP_Type12 : 8|4@0+ (1,0) [0|15] "" RadioLow,CSM,CSM_AV,VCU
 SG_ LRSMP_Type11 : 12|4@0+ (1,0) [0|15] "" RadioLow,CSM,CSM_AV,VCU
 SG_ LRSMP_Type14 : 16|4@0+ (1,0) [0|15] "" RadioLow,CSM,CSM_AV,VCU
 SG_ LRSMP_Type13 : 20|4@0+ (1,0) [0|15] "" RadioLow,CSM,CSM_AV,VCU
 SG_ LRSMP_Type2 : 24|4@0+ (1,0) [0|15] "" RadioLow,CSM,CSM_AV,VCU
 SG_ LRSMP_Type15 : 28|4@0+ (1,0) [0|15] "" RadioLow,CSM,CSM_AV,VCU
 SG_ LRSMP_Type4 : 32|4@0+ (1,0) [0|15] "" RadioLow,CSM,CSM_AV,VCU
 SG_ LRSMP_Type3 : 36|4@0+ (1,0) [0|15] "" RadioLow,CSM,CSM_AV,VCU
 SG_ LRSMP_Type6 : 40|4@0+ (1,0) [0|15] "" RadioLow,CSM,CSM_AV,VCU
 SG_ LRSMP_Type5 : 44|4@0+ (1,0) [0|15] "" RadioLow,CSM,CSM_AV,VCU
 SG_ LRSMP_Type8 : 48|4@0+ (1,0) [0|15] "" RadioLow,CSM,CSM_AV,VCU
 SG_ LRSMP_Type7 : 52|4@0+ (1,0) [0|15] "" RadioLow,CSM,CSM_AV,VCU
 SG_ LRSMP_Type9 : 60|4@0+ (1,0) [0|15] "" RadioLow,CSM,CSM_AV,VCU

BO_ 1256 PDU_4053: 8 CGM
 SG_ LRSAP_BkCshBlstrInOut : 3|4@0+ (1,0) [0|15] "" RadioLow,CSM,CSM_AV,VCU
 SG_ LRSAP_BkBlstrInOut : 7|4@0+ (1,0) [0|15] "" RadioLow,CSM,CSM_AV,VCU
 SG_ LRSAP_CshLgthAdjFdRr : 11|4@0+ (1,0) [0|15] "" RadioLow,CSM,CSM_AV,VCU
 SG_ LRSAP_CshBlstrInOut : 15|4@0+ (1,0) [0|15] "" RadioLow,CSM,CSM_AV,VCU
 SG_ LRSAP_HdrstTltFwdRr : 19|4@0+ (1,0) [0|15] "" RadioLow,CSM,CSM_AV,VCU
 SG_ LRSAP_HdrstFwdRrwd : 23|4@0+ (1,0) [0|15] "" RadioLow,CSM,CSM_AV,VCU
 SG_ LRSAP_HdrstUpDnFdRr : 27|4@0+ (1,0) [0|15] "" RadioLow,CSM,CSM_AV,VCU
 SG_ LRSAP_HdrstUpDn : 31|4@0+ (1,0) [0|15] "" RadioLow,CSM,CSM_AV,VCU
 SG_ LRSAP_LmbrFwdRr : 35|4@0+ (1,0) [0|15] "" RadioLow,CSM,CSM_AV,VCU
 SG_ LRSAP_HdrstWngsInOut : 39|4@0+ (1,0) [0|15] "" RadioLow,CSM,CSM_AV,VCU
 SG_ LRSAP_LmbrUpDwn : 43|4@0+ (1,0) [0|15] "" RadioLow,CSM,CSM_AV,VCU
 SG_ LRSAP_LmbrUpDnFdRr : 47|4@0+ (1,0) [0|15] "" RadioLow,CSM,CSM_AV,VCU
 SG_ LRSAP_UprShldrFwdRr : 51|4@0+ (1,0) [0|15] "" RadioLow,CSM,CSM_AV,VCU
 SG_ LRSAP_Massg : 55|4@0+ (1,0) [0|15] "" RadioLow,CSM,CSM_AV,VCU
 SG_ StLckoutLRCtlCurrSet : 60|2@0+ (1,0) [0|2] "" VCU
 SG_ StLckoutLRVirtCtlAval : 61|1@0+ (1,0) [0|1] "" VCU
 SG_ StMemLRVirtCtlStorAllwd : 62|1@0+ (1,0) [0|1] "" VCU
 SG_ StMemLRVirtCtlRclAllwd : 63|1@0+ (1,0) [0|1] "" VCU

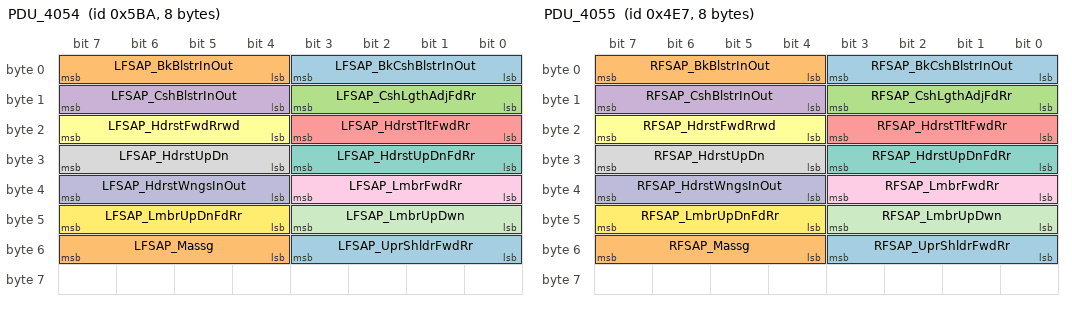
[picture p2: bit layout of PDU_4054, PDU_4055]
BO_ 1466 PDU_4054: 8 CGM
 SG_ LFSAP_BkCshBlstrInOut : 3|4@0+ (1,0) [0|15] "" RadioLow,CSM,CSM_AV,VCU
 SG_ LFSAP_BkBlstrInOut : 7|4@0+ (1,0) [0|15] "" RadioLow,CSM,CSM_AV,VCU
 SG_ LFSAP_CshLgthAdjFdRr : 11|4@0+ (1,0) [0|15] "" RadioLow,CSM,CSM_AV,VCU
 SG_ LFSAP_CshBlstrInOut : 15|4@0+ (1,0) [0|15] "" RadioLow,CSM,CSM_AV,VCU
 SG_ LFSAP_HdrstTltFwdRr : 19|4@0+ (1,0) [0|15] "" RadioLow,CSM,CSM_AV,VCU
 SG_ LFSAP_HdrstFwdRrwd : 23|4@0+ (1,0) [0|15] "" RadioLow,CSM,CSM_AV,VCU
 SG_ LFSAP_HdrstUpDnFdRr : 27|4@0+ (1,0) [0|15] "" RadioLow,CSM,CSM_AV,VCU
 SG_ LFSAP_HdrstUpDn : 31|4@0+ (1,0) [0|15] "" RadioLow,CSM,CSM_AV,VCU
 SG_ LFSAP_LmbrFwdRr : 35|4@0+ (1,0) [0|15] "" RadioLow,CSM,CSM_AV,VCU
 SG_ LFSAP_HdrstWngsInOut : 39|4@0+ (1,0) [0|15] "" RadioLow,CSM,CSM_AV,VCU
 SG_ LFSAP_LmbrUpDwn : 43|4@0+ (1,0) [0|15] "" RadioLow,CSM,CSM_AV,VCU
 SG_ LFSAP_LmbrUpDnFdRr : 47|4@0+ (1,0) [0|15] "" RadioLow,CSM,CSM_AV,VCU
 SG_ LFSAP_UprShldrFwdRr : 51|4@0+ (1,0) [0|15] "" RadioLow,CSM,CSM_AV,VCU
 SG_ LFSAP_Massg : 55|4@0+ (1,0) [0|15] "" RadioLow,CSM,CSM_AV,VCU

BO_ 1255 PDU_4055: 8 CGM
 SG_ RFSAP_BkCshBlstrInOut : 3|4@0+ (1,0) [0|15] "" RadioLow,CSM,CSM_AV,VCU
 SG_ RFSAP_BkBlstrInOut : 7|4@0+ (1,0) [0|15] "" RadioLow,CSM,CSM_AV,VCU
 SG_ RFSAP_CshLgthAdjFdRr : 11|4@0+ (1,0) [0|15] "" RadioLow,CSM,CSM_AV,VCU
 SG_ RFSAP_CshBlstrInOut : 15|4@0+ (1,0) [0|15] "" RadioLow,CSM,CSM_AV,VCU
 SG_ RFSAP_HdrstTltFwdRr : 19|4@0+ (1,0) [0|15] "" RadioLow,CSM,CSM_AV,VCU
 SG_ RFSAP_HdrstFwdRrwd : 23|4@0+ (1,0) [0|15] "" RadioLow,CSM,CSM_AV,VCU
 SG_ RFSAP_HdrstUpDnFdRr : 27|4@0+ (1,0) [0|15] "" RadioLow,CSM,CSM_AV,VCU
 SG_ RFSAP_HdrstUpDn : 31|4@0+ (1,0) [0|15] "" RadioLow,CSM,CSM_AV,VCU
 SG_ RFSAP_LmbrFwdRr : 35|4@0+ (1,0) [0|15] "" RadioLow,CSM,CSM_AV,VCU
 SG_ RFSAP_HdrstWngsInOut : 39|4@0+ (1,0) [0|15] "" RadioLow,CSM,CSM_AV,VCU
 SG_ RFSAP_LmbrUpDwn : 43|4@0+ (1,0) [0|15] "" RadioLow,CSM,CSM_AV,VCU
 SG_ RFSAP_LmbrUpDnFdRr : 47|4@0+ (1,0) [0|15] "" RadioLow,CSM,CSM_AV,VCU
 SG_ RFSAP_UprShldrFwdRr : 51|4@0+ (1,0) [0|15] "" RadioLow,CSM,CSM_AV,VCU
 SG_ RFSAP_Massg : 55|4@0+ (1,0) [0|15] "" RadioLow,CSM,CSM_AV,VCU

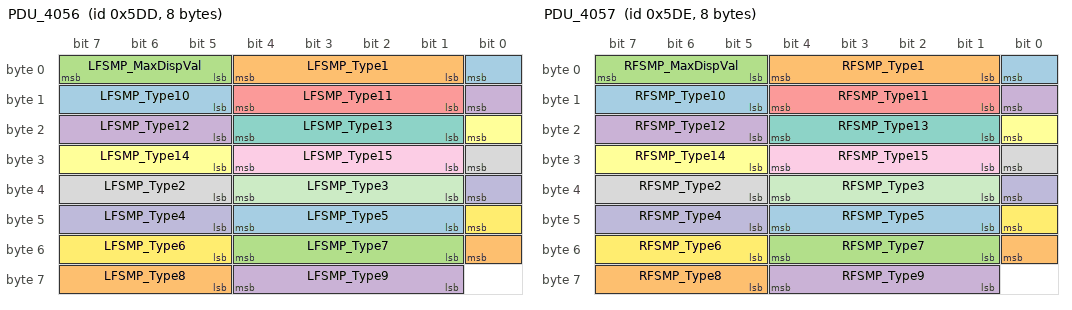
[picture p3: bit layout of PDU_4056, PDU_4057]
BO_ 1501 PDU_4056: 8 CGM
 SG_ LFSMP_Type10 : 0|4@0+ (1,0) [0|15] "" RadioLow,CSM,CSM_AV,VCU
 SG_ LFSMP_Type1 : 4|4@0+ (1,0) [0|15] "" RadioLow,CSM,CSM_AV,VCU
 SG_ LFSMP_MaxDispVal : 7|3@0+ (1,0) [0|7] "" RadioLow,CSM,CSM_AV,VCU
 SG_ LFSMP_Type12 : 8|4@0+ (1,0) [0|15] "" RadioLow,CSM,CSM_AV,VCU
 SG_ LFSMP_Type11 : 12|4@0+ (1,0) [0|15] "" RadioLow,CSM,CSM_AV,VCU
 SG_ LFSMP_Type14 : 16|4@0+ (1,0) [0|15] "" RadioLow,CSM,CSM_AV,VCU
 SG_ LFSMP_Type13 : 20|4@0+ (1,0) [0|15] "" RadioLow,CSM,CSM_AV,VCU
 SG_ LFSMP_Type2 : 24|4@0+ (1,0) [0|15] "" RadioLow,CSM,CSM_AV,VCU
 SG_ LFSMP_Type15 : 28|4@0+ (1,0) [0|15] "" RadioLow,CSM,CSM_AV,VCU
 SG_ LFSMP_Type4 : 32|4@0+ (1,0) [0|15] "" RadioLow,CSM,CSM_AV,VCU
 SG_ LFSMP_Type3 : 36|4@0+ (1,0) [0|15] "" RadioLow,CSM,CSM_AV,VCU
 SG_ LFSMP_Type6 : 40|4@0+ (1,0) [0|15] "" RadioLow,CSM,CSM_AV,VCU
 SG_ LFSMP_Type5 : 44|4@0+ (1,0) [0|15] "" RadioLow,CSM,CSM_AV,VCU
 SG_ LFSMP_Type8 : 48|4@0+ (1,0) [0|15] "" RadioLow,CSM,CSM_AV,VCU
 SG_ LFSMP_Type7 : 52|4@0+ (1,0) [0|15] "" RadioLow,CSM,CSM_AV,VCU
 SG_ LFSMP_Type9 : 60|4@0+ (1,0) [0|15] "" RadioLow,CSM,CSM_AV,VCU

BO_ 1502 PDU_4057: 8 CGM
 SG_ RFSMP_Type10 : 0|4@0+ (1,0) [0|15] "" RadioLow,CSM,CSM_AV,VCU
 SG_ RFSMP_Type1 : 4|4@0+ (1,0) [0|15] "" RadioLow,CSM,CSM_AV,VCU
 SG_ RFSMP_MaxDispVal : 7|3@0+ (1,0) [0|7] "" RadioLow,CSM,CSM_AV,VCU
 SG_ RFSMP_Type12 : 8|4@0+ (1,0) [0|15] "" RadioLow,CSM,CSM_AV,VCU
 SG_ RFSMP_Type11 : 12|4@0+ (1,0) [0|15] "" RadioLow,CSM,CSM_AV,VCU
 SG_ RFSMP_Type14 : 16|4@0+ (1,0) [0|15] "" RadioLow,CSM,CSM_AV,VCU
 SG_ RFSMP_Type13 : 20|4@0+ (1,0) [0|15] "" RadioLow,CSM,CSM_AV,VCU
 SG_ RFSMP_Type2 : 24|4@0+ (1,0) [0|15] "" RadioLow,CSM,CSM_AV,VCU
 SG_ RFSMP_Type15 : 28|4@0+ (1,0) [0|15] "" RadioLow,CSM,CSM_AV,VCU
 SG_ RFSMP_Type4 : 32|4@0+ (1,0) [0|15] "" RadioLow,CSM,CSM_AV,VCU
 SG_ RFSMP_Type3 : 36|4@0+ (1,0) [0|15] "" RadioLow,CSM,CSM_AV,VCU
 SG_ RFSMP_Type6 : 40|4@0+ (1,0) [0|15] "" RadioLow,CSM,CSM_AV,VCU
 SG_ RFSMP_Type5 : 44|4@0+ (1,0) [0|15] "" RadioLow,CSM,CSM_AV,VCU
 SG_ RFSMP_Type8 : 48|4@0+ (1,0) [0|15] "" RadioLow,CSM,CSM_AV,VCU
 SG_ RFSMP_Type7 : 52|4@0+ (1,0) [0|15] "" RadioLow,CSM,CSM_AV,VCU
 SG_ RFSMP_Type9 : 60|4@0+ (1,0) [0|15] "" RadioLow,CSM,CSM_AV,VCU

BO_ 1513 PDU_4058: 6 CGM
 SG_ RrClsrAjrStat : 6|1@0+ (1,0) [0|1] "" AMP,RadioLow,TCP,VKM,CSM,CSM_AV,IPC,IPC_INT,VCU
 SG_ RrClsrAjrStat_Inv : 7|1@0+ (1,0) [0|1] "" TCP,VKM,CSM,CSM_AV,IPC,IPC_INT,VCU

BO_ 2000 PDU_4077: 8 CGM
 SG_ StBkSdBolsLFVirtCtlAval : 0|1@0+ (1,0) [0|1] "" VCU
 SG_ StBkLumbVertLFVirtCtlAval : 1|1@0+ (1,0) [0|1] "" VCU
 SG_ StBkLumbHrztlLFVirtCtlAval : 2|1@0+ (1,0) [0|1] "" VCU
 SG_ StBkHrztlLFCtlFrmRrVirtCtlAval : 3|1@0+ (1,0) [0|1] "" VCU
 SG_ StBkHrztlLFCtlFrmFrtVirtCtlAval : 4|1@0+ (1,0) [0|1] "" VCU
 SG_ StMasgIntstyLFVirtCtlMaxLvl : 7|3@0+ (1,0) [0|7] "" VCU
 SG_ StHdrstVertLFVirtCtlAval : 8|1@0+ (1,0) [0|1] "" VCU
 SG_ StHdrstHrztlLFVirtCtlAval : 9|1@0+ (1,0) [0|1] "" VCU
 SG_ StCushSdBolsLFVirtCtlAval : 10|1@0+ (1,0) [0|1] "" VCU
 SG_ StCushRrVertLFVirtCtlAval : 11|1@0+ (1,0) [0|1] "" VCU
 SG_ StCushLgthHrztlLFVirtCtlAval : 12|1@0+ (1,0) [0|1] "" VCU
 SG_ StCushHrztlLFCtlFrmRrVirtCtlAvl : 13|1@0+ (1,0) [0|1] "" VCU
 SG_ StCushHrztlLFCtlFrmFrVirtCtlAvl : 14|1@0+ (1,0) [0|1] "" VCU
 SG_ StCushFrtVertLFVirtCtlAval : 15|1@0+ (1,0) [0|1] "" VCU
 SG_ StMasgTyp2LFVirtCtlAval : 16|1@0+ (1,0) [0|1] "" VCU
 SG_ StMasgTyp1LFVirtCtlAval : 17|1@0+ (1,0) [0|1] "" VCU
 SG_ StMasgTyp15LFVirtCtlAval : 18|1@0+ (1,0) [0|1] "" VCU
 SG_ StMasgTyp14LFVirtCtlAval : 19|1@0+ (1,0) [0|1] "" VCU
 SG_ StMasgTyp13LFVirtCtlAval : 20|1@0+ (1,0) [0|1] "" VCU
 SG_ StMasgTyp12LFVirtCtlAval : 21|1@0+ (1,0) [0|1] "" VCU
 SG_ StMasgTyp11LFVirtCtlAval : 22|1@0+ (1,0) [0|1] "" VCU
 SG_ StMasgTyp10LFVirtCtlAval : 23|1@0+ (1,0) [0|1] "" VCU
 SG_ StUpprShldrHrztlLFVirtCtlAval : 24|1@0+ (1,0) [0|1] "" VCU
 SG_ StMasgTyp9LFVirtCtlAval : 25|1@0+ (1,0) [0|1] "" VCU
 SG_ StMasgTyp8LFVirtCtlAval : 26|1@0+ (1,0) [0|1] "" VCU
 SG_ StMasgTyp7LFVirtCtlAval : 27|1@0+ (1,0) [0|1] "" VCU
 SG_ StMasgTyp6LFVirtCtlAval : 28|1@0+ (1,0) [0|1] "" VCU
 SG_ StMasgTyp5LFVirtCtlAval : 29|1@0+ (1,0) [0|1] "" VCU
 SG_ StMasgTyp4LFVirtCtlAval : 30|1@0+ (1,0) [0|1] "" VCU
 SG_ StMasgTyp3LFVirtCtlAval : 31|1@0+ (1,0) [0|1] "" VCU
 SG_ StMemLFVirtCtlNumofMemPstnsAval : 35|4@0+ (1,0) [0|8] "" VCU
 SG_ StMemLFVirtCtlNumofExtPstnsAval : 39|4@0+ (1,0) [0|8] "" VCU
 SG_ StBkHrztlLFCtlFrmFrtVirtCtlAlwd : 40|1@0+ (1,0) [0|1] "" VCU
 SG_ StMasgIntstyLFLstKnwnSet : 43|3@0+ (1,0) [0|7] "" VCU
 SG_ StMasgTypLFLstKnwnSet : 47|4@0+ (1,0) [0|15] "" VCU
 SG_ StCushLgthHrztlLFVirtCtlAllwd : 48|1@0+ (1,0) [0|1] "" VCU
 SG_ StCushHrztlLFCtlFrmRrVirCtlAlwd : 49|1@0+ (1,0) [0|1] "" VCU
 SG_ StCushHrztlLFCtlFrmFrVirCtlAlwd : 50|1@0+ (1,0) [0|1] "" VCU
 SG_ StCushFrtVertLFVirtCtlAllwd : 51|1@0+ (1,0) [0|1] "" VCU
 SG_ StBkSdBolsLFVirtCtlAllwd : 52|1@0+ (1,0) [0|1] "" VCU
 SG_ StBkLumbVertLFVirtCtlAllwd : 53|1@0+ (1,0) [0|1] "" VCU
 SG_ StBkLumbHrztlLFVirtCtlAllwd : 54|1@0+ (1,0) [0|1] "" VCU
 SG_ StBkHrztlLFCtlFrmRrVirtCtlAllwd : 55|1@0+ (1,0) [0|1] "" VCU
 SG_ StMemLFVirtCtlStorAllwd : 56|1@0+ (1,0) [0|1] "" VCU
 SG_ StMemLFVirtCtlRclAllwd : 57|1@0+ (1,0) [0|1] "" VCU
 SG_ StUpprShldrHrztlLFVirtCtlAllwd : 58|1@0+ (1,0) [0|1] "" VCU
 SG_ StMasgLFVirtCtlAllwd : 59|1@0+ (1,0) [0|1] "" VCU
 SG_ StHdrstVertLFVirtCtlAllwd : 60|1@0+ (1,0) [0|1] "" VCU
 SG_ StHdrstHrztlLFVirtCtlAllwd : 61|1@0+ (1,0) [0|1] "" VCU
 SG_ StCushSdBolsLFVirtCtlAllwd : 62|1@0+ (1,0) [0|1] "" VCU
 SG_ StCushRrVertLFVirtCtlAllwd : 63|1@0+ (1,0) [0|1] "" VCU

BO_ 1985 PDU_4084: 8 CGM
 SG_ DMBlkhdDrAutoClsTmCstSetAval : 0|1@0+ (1,0) [0|1] "" VCU
 SG_ DMBlkhdDrAutoClsTmCstAvlFlg7 : 1|1@0+ (1,0) [0|1] "" VCU
 SG_ DMBlkhdDrAutoClsTmCstAvlFlg6 : 2|1@0+ (1,0) [0|1] "" VCU
 SG_ DMBlkhdDrAutoClsTmCstAvlFlg5 : 3|1@0+ (1,0) [0|1] "" VCU
 SG_ DMBlkhdDrAutoClsTmCstAvlFlg4 : 4|1@0+ (1,0) [0|1] "" VCU
 SG_ DMBlkhdDrAutoClsTmCstAvlFlg3 : 5|1@0+ (1,0) [0|1] "" VCU
 SG_ DMBlkhdDrAutoClsTmCstAvlFlg2 : 6|1@0+ (1,0) [0|1] "" VCU
 SG_ DMBlkhdDrAutoClsTmCstAvlFlg1 : 7|1@0+ (1,0) [0|1] "" VCU
 SG_ DMBlkhdDrOpnVehOffCstSetAval : 8|1@0+ (1,0) [0|1] "" VCU
 SG_ DMBlkhdDrOpnVehOffCstAvlFlg7 : 9|1@0+ (1,0) [0|1] "" VCU
 SG_ DMBlkhdDrOpnVehOffCstAvlFlg6 : 10|1@0+ (1,0) [0|1] "" VCU
 SG_ DMBlkhdDrOpnVehOffCstAvlFlg5 : 11|1@0+ (1,0) [0|1] "" VCU
 SG_ DMBlkhdDrOpnVehOffCstAvlFlg4 : 12|1@0+ (1,0) [0|1] "" VCU
 SG_ DMBlkhdDrOpnVehOffCstAvlFlg3 : 13|1@0+ (1,0) [0|1] "" VCU
 SG_ DMBlkhdDrOpnVehOffCstAvlFlg2 : 14|1@0+ (1,0) [0|1] "" VCU
 SG_ DMBlkhdDrOpnVehOffCstAvlFlg1 : 15|1@0+ (1,0) [0|1] "" VCU
 SG_ BlkhdDrRmtActvnChmEvntStat : 16|2@0+ (1,0) [0|2] "" VCU
 SG_ BlkhdDrLoclActvnChmEvntStat : 18|2@0+ (1,0) [0|2] "" VCU
 SG_ BlkhdDrObstclChmEvntStat : 20|2@0+ (1,0) [0|2] "" VCU
 SG_ DMBlkhdDrAutoClsTmCstCurrSetVal : 23|3@0+ (1,0) [0|3] "" VCU
 SG_ BlkhdDrServIndOn : 30|1@0+ (1,0) [0|1] "" VCU

BO_ 1927 PDU_4085: 8 CGM
 SG_ DMPDAutoClsTmRFCstSetAval : 0|1@0+ (1,0) [0|1] "" VCU
 SG_ DMPDAutoClsTmRFCstAvlFlg7 : 1|1@0+ (1,0) [0|1] "" VCU
 SG_ DMPDAutoClsTmRFCstAvlFlg6 : 2|1@0+ (1,0) [0|1] "" VCU
 SG_ DMPDAutoClsTmRFCstAvlFlg5 : 3|1@0+ (1,0) [0|1] "" VCU
 SG_ DMPDAutoClsTmRFCstAvlFlg4 : 4|1@0+ (1,0) [0|1] "" VCU
 SG_ DMPDAutoClsTmRFCstAvlFlg3 : 5|1@0+ (1,0) [0|1] "" VCU
 SG_ DMPDAutoClsTmRFCstAvlFlg2 : 6|1@0+ (1,0) [0|1] "" VCU
 SG_ DMPDAutoClsTmRFCstAvlFlg1 : 7|1@0+ (1,0) [0|1] "" VCU
 SG_ DMPDClsOutofPrkRFCstSetAval : 8|1@0+ (1,0) [0|1] "" VCU
 SG_ DMPDClsOutofPrkRFCstAvlFlg7 : 9|1@0+ (1,0) [0|1] "" VCU
 SG_ DMPDClsOutofPrkRFCstAvlFlg6 : 10|1@0+ (1,0) [0|1] "" VCU
 SG_ DMPDClsOutofPrkRFCstAvlFlg5 : 11|1@0+ (1,0) [0|1] "" VCU
 SG_ DMPDClsOutofPrkRFCstAvlFlg4 : 12|1@0+ (1,0) [0|1] "" VCU
 SG_ DMPDClsOutofPrkRFCstAvlFlg3 : 13|1@0+ (1,0) [0|1] "" VCU
 SG_ DMPDClsOutofPrkRFCstAvlFlg2 : 14|1@0+ (1,0) [0|1] "" VCU
 SG_ DMPDClsOutofPrkRFCstAvlFlg1 : 15|1@0+ (1,0) [0|1] "" VCU
 SG_ DMPDDOBlkhdDrOpnRFCstSetAval : 16|1@0+ (1,0) [0|1] "" VCU
 SG_ DMPDDOBlkhdDrOpnRFCstAvlFlg7 : 17|1@0+ (1,0) [0|1] "" VCU
 SG_ DMPDDOBlkhdDrOpnRFCstAvlFlg6 : 18|1@0+ (1,0) [0|1] "" VCU
 SG_ DMPDDOBlkhdDrOpnRFCstAvlFlg5 : 19|1@0+ (1,0) [0|1] "" VCU
 SG_ DMPDDOBlkhdDrOpnRFCstAvlFlg4 : 20|1@0+ (1,0) [0|1] "" VCU
 SG_ DMPDDOBlkhdDrOpnRFCstAvlFlg3 : 21|1@0+ (1,0) [0|1] "" VCU
 SG_ DMPDDOBlkhdDrOpnRFCstAvlFlg2 : 22|1@0+ (1,0) [0|1] "" VCU
 SG_ DMPDDOBlkhdDrOpnRFCstAvlFlg1 : 23|1@0+ (1,0) [0|1] "" VCU
 SG_ SCAOOAByKeyFobRFCstSetAval : 24|1@0+ (1,0) [0|1] "" VCU
 SG_ SCAOOAByKeyFobRFCstAvlFlg7 : 25|1@0+ (1,0) [0|1] "" VCU
 SG_ SCAOOAByKeyFobRFCstAvlFlg6 : 26|1@0+ (1,0) [0|1] "" VCU
 SG_ SCAOOAByKeyFobRFCstAvlFlg5 : 27|1@0+ (1,0) [0|1] "" VCU
 SG_ SCAOOAByKeyFobRFCstAvlFlg4 : 28|1@0+ (1,0) [0|1] "" VCU
 SG_ SCAOOAByKeyFobRFCstAvlFlg3 : 29|1@0+ (1,0) [0|1] "" VCU
 SG_ SCAOOAByKeyFobRFCstAvlFlg2 : 30|1@0+ (1,0) [0|1] "" VCU
 SG_ SCAOOAByKeyFobRFCstAvlFlg1 : 31|1@0+ (1,0) [0|1] "" VCU
 SG_ SCAOOAByVirtKeyRFCstSetAval : 32|1@0+ (1,0) [0|1] "" VCU
 SG_ SCAOOAByVirtKeyRFCstAvlFlg7 : 33|1@0+ (1,0) [0|1] "" VCU
 SG_ SCAOOAByVirtKeyRFCstAvlFlg6 : 34|1@0+ (1,0) [0|1] "" VCU
 SG_ SCAOOAByVirtKeyRFCstAvlFlg5 : 35|1@0+ (1,0) [0|1] "" VCU
 SG_ SCAOOAByVirtKeyRFCstAvlFlg4 : 36|1@0+ (1,0) [0|1] "" VCU
 SG_ SCAOOAByVirtKeyRFCstAvlFlg3 : 37|1@0+ (1,0) [0|1] "" VCU
 SG_ SCAOOAByVirtKeyRFCstAvlFlg2 : 38|1@0+ (1,0) [0|1] "" VCU
 SG_ SCAOOAByVirtKeyRFCstAvlFlg1 : 39|1@0+ (1,0) [0|1] "" VCU
 SG_ SCAPDBrktoClsRFCstSetAval : 40|1@0+ (1,0) [0|1] "" VCU
 SG_ SCAPDBrktoClsRFCstAvlFlg7 : 41|1@0+ (1,0) [0|1] "" VCU
 SG_ SCAPDBrktoClsRFCstAvlFlg6 : 42|1@0+ (1,0) [0|1] "" VCU
 SG_ SCAPDBrktoClsRFCstAvlFlg5 : 43|1@0+ (1,0) [0|1] "" VCU
 SG_ SCAPDBrktoClsRFCstAvlFlg4 : 44|1@0+ (1,0) [0|1] "" VCU
 SG_ SCAPDBrktoClsRFCstAvlFlg3 : 45|1@0+ (1,0) [0|1] "" VCU
 SG_ SCAPDBrktoClsRFCstAvlFlg2 : 46|1@0+ (1,0) [0|1] "" VCU
 SG_ SCAPDBrktoClsRFCstAvlFlg1 : 47|1@0+ (1,0) [0|1] "" VCU
 SG_ SCAPDBrktoClsRFCstCurrSetVal : 48|3@0+ (1,0) [0|2] "" VCU
 SG_ DMPDClsOutofPrkRFCstCurrSetVal : 51|3@0+ (1,0) [0|2] "" VCU
 SG_ DMPDAutoClsTmRFCstCurrSetVal : 54|3@0+ (1,0) [0|3] "" VCU
 SG_ SCAPwrDrMtnRFVirtCtlAval : 55|1@0+ (1,0) [0|1] "" VCU
 SG_ PwrSdClsrRFServIndOn : 59|1@0+ (1,0) [0|1] "" VCU
 SG_ PwrSdClsrRFBlckdIndOn : 60|1@0+ (1,0) [0|1] "" VCU
 SG_ SCAPwrDrMtnRFVirtCtlAllwd : 61|1@0+ (1,0) [0|1] "" VCU

BO_ 1930 PDU_4086: 8 CGM
 SG_ StMasgTyp11RFVirtCtlAval : 0|1@0+ (1,0) [0|1] "" VCU
 SG_ StMasgTyp10RFVirtCtlAval : 1|1@0+ (1,0) [0|1] "" VCU
 SG_ StHdrstVertRFVirtCtlAval : 2|1@0+ (1,0) [0|1] "" VCU
 SG_ StHdrstHrztlRFVirtCtlAval : 3|1@0+ (1,0) [0|1] "" VCU
 SG_ StCushSdBolsRFVirtCtlAval : 4|1@0+ (1,0) [0|1] "" VCU
 SG_ StCushRrVertRFVirtCtlAval : 5|1@0+ (1,0) [0|1] "" VCU
 SG_ StCushLgthHrztlRFVirtCtlAval : 6|1@0+ (1,0) [0|1] "" VCU
 SG_ StCushHrztlRFCtlFrmRrVirtCtlAvl : 7|1@0+ (1,0) [0|1] "" VCU
 SG_ StMasgTyp4RFVirtCtlAval : 8|1@0+ (1,0) [0|1] "" VCU
 SG_ StMasgTyp3RFVirtCtlAval : 9|1@0+ (1,0) [0|1] "" VCU
 SG_ StMasgTyp2RFVirtCtlAval : 10|1@0+ (1,0) [0|1] "" VCU
 SG_ StMasgTyp1RFVirtCtlAval : 11|1@0+ (1,0) [0|1] "" VCU
 SG_ StMasgTyp15RFVirtCtlAval : 12|1@0+ (1,0) [0|1] "" VCU
 SG_ StMasgTyp14RFVirtCtlAval : 13|1@0+ (1,0) [0|1] "" VCU
 SG_ StMasgTyp13RFVirtCtlAval : 14|1@0+ (1,0) [0|1] "" VCU
 SG_ StMasgTyp12RFVirtCtlAval : 15|1@0+ (1,0) [0|1] "" VCU
 SG_ StCushLgthHrztlRFVirtCtlAllwd : 16|1@0+ (1,0) [0|1] "" VCU
 SG_ StCushHrztlRFCtlFrmRrVirCtlAlwd : 17|1@0+ (1,0) [0|1] "" VCU
 SG_ StCushHrztlRFCtlFrmFrVirCtlAlwd : 18|1@0+ (1,0) [0|1] "" VCU
 SG_ StCushFrtVertRFVirtCtlAllwd : 19|1@0+ (1,0) [0|1] "" VCU
 SG_ StBkSdBolsRFVirtCtlAllwd : 20|1@0+ (1,0) [0|1] "" VCU
 SG_ StBkLumbVertRFVirtCtlAllwd : 21|1@0+ (1,0) [0|1] "" VCU
 SG_ StBkLumbHrztlRFVirtCtlAllwd : 22|1@0+ (1,0) [0|1] "" VCU
 SG_ StBkHrztlRFCtlFrmRrVirtCtlAllwd : 23|1@0+ (1,0) [0|1] "" VCU
 SG_ StMasgTypRFLstKnwnSet : 24|4@0+ (1,0) [0|15] "" VCU
 SG_ StBkHrztlRFCtlFrmFrtVirtCtlAlwd : 25|1@0+ (1,0) [0|1] "" VCU
 SG_ StUpprShldrHrztlRFVirtCtlAllwd : 26|1@0+ (1,0) [0|1] "" VCU
 SG_ StMasgRFVirtCtlAllwd : 27|1@0+ (1,0) [0|1] "" VCU
 SG_ StHdrstVertRFVirtCtlAllwd : 28|1@0+ (1,0) [0|1] "" VCU
 SG_ StHdrstHrztlRFVirtCtlAllwd : 29|1@0+ (1,0) [0|1] "" VCU
 SG_ StCushSdBolsRFVirtCtlAllwd : 30|1@0+ (1,0) [0|1] "" VCU
 SG_ StCushRrVertRFVirtCtlAllwd : 31|1@0+ (1,0) [0|1] "" VCU
 SG_ StMemRFVirtCtlNumofExtPstnsAval : 33|4@0+ (1,0) [0|8] "" VCU
 SG_ StMasgIntstyRFLstKnwnSet : 36|3@0+ (1,0) [0|7] "" VCU
 SG_ StMasgIntstyRFVirtCtlMaxLvl : 41|3@0+ (1,0) [0|7] "" VCU
 SG_ StMemRFVirtCtlNumofMemPstnsAval : 45|4@0+ (1,0) [0|8] "" VCU
 SG_ StCushHrztlRFCtlFrmFrtVirCtlAvl : 48|1@0+ (1,0) [0|1] "" VCU
 SG_ StCushFrtVertRFVirtCtlAval : 49|1@0+ (1,0) [0|1] "" VCU
 SG_ StBkSdBolsRFVirtCtlAval : 50|1@0+ (1,0) [0|1] "" VCU
 SG_ StBkLumbVertRFVirtCtlAval : 51|1@0+ (1,0) [0|1] "" VCU
 SG_ StBkLumbHrztlRFVirtCtlAval : 52|1@0+ (1,0) [0|1] "" VCU
 SG_ StBkHrztlRFCtlFrmRrVirtCtlAval : 53|1@0+ (1,0) [0|1] "" VCU
 SG_ StBkHrztlRFCtlFrmFrtVirtCtlAval : 54|1@0+ (1,0) [0|1] "" VCU
 SG_ StMemRFVirtCtlStorAllwd : 56|1@0+ (1,0) [0|1] "" VCU
 SG_ StMemRFVirtCtlRclAllwd : 57|1@0+ (1,0) [0|1] "" VCU
 SG_ StUpprShldrHrztlRFVirtCtlAval : 58|1@0+ (1,0) [0|1] "" VCU
 SG_ StMasgTyp9RFVirtCtlAval : 59|1@0+ (1,0) [0|1] "" VCU
 SG_ StMasgTyp8RFVirtCtlAval : 60|1@0+ (1,0) [0|1] "" VCU
 SG_ StMasgTyp7RFVirtCtlAval : 61|1@0+ (1,0) [0|1] "" VCU
 SG_ StMasgTyp6RFVirtCtlAval : 62|1@0+ (1,0) [0|1] "" VCU
 SG_ StMasgTyp5RFVirtCtlAval : 63|1@0+ (1,0) [0|1] "" VCU

BA_DEF_ SG_  "SignalType" STRING ;
BA_DEF_ SG_  "SignalLongName" STRING ;
BA_DEF_ BO_  "GenMsgCycleTime" INT 0 10000;
BA_DEF_ BO_  "GenMsgSendType" ENUM "cyclicX","spontanX","cyclicIfActiveX","spontanWithDelay","cyclicAndSpontanX","cyclicAndSpontanWithDelay","spontanWithRepetition","cyclicIfActiveAndSpontanWD";
BA_DEF_DEF_  "SignalType" "";
BA_DEF_DEF_  "SignalLongName" "";
BA_DEF_DEF_  "GenMsgCycleTime" 0;
BA_DEF_DEF_  "GenMsgSendType" "cyclicX";
BA_ "GenMsgCycleTime" BO_ 1415 1000;
BA_ "GenMsgCycleTime" BO_ 73 12.5;
BA_ "GenMsgCycleTime" BO_ 1147 1000;
BA_ "GenMsgCycleTime" BO_ 1349 1000;
BA_ "GenMsgCycleTime" BO_ 2010 1000;
BA_ "GenMsgCycleTime" BO_ 1275 1000;
BA_ "GenMsgCycleTime" BO_ 1274 1000;
BA_ "GenMsgCycleTime" BO_ 1491 1000;
BA_ "GenMsgCycleTime" BO_ 1882 1000;
BA_ "GenMsgCycleTime" BO_ 1183 1000;
BA_ "GenMsgCycleTime" BO_ 1075 1000;
BA_ "GenMsgCycleTime" BO_ 1932 1000;
BA_ "GenMsgCycleTime" BO_ 1793 1000;
BA_ "GenMsgCycleTime" BO_ 1498 1000;
BA_ "GenMsgCycleTime" BO_ 1809 1000;
BA_ "GenMsgCycleTime" BO_ 1499 1000;
BA_ "GenMsgCycleTime" BO_ 1256 1000;
BA_ "GenMsgCycleTime" BO_ 1466 1000;
BA_ "GenMsgCycleTime" BO_ 1255 1000;
BA_ "GenMsgCycleTime" BO_ 1501 1000;
BA_ "GenMsgCycleTime" BO_ 1502 1000;
BA_ "GenMsgCycleTime" BO_ 1513 1000;
BA_ "GenMsgCycleTime" BO_ 2000 1000;
BA_ "GenMsgCycleTime" BO_ 1985 1000;
BA_ "GenMsgCycleTime" BO_ 1927 1000;
BA_ "GenMsgCycleTime" BO_ 1930 1000;
BA_ "SignalLongName" SG_ 1415 ACCDrSlctdSpd "Adaptive Cruise Control Information 1 : Adaptive Cruise Control Driver Selected Speed";
BA_ "SignalType" SG_ 1415 ACCAutoStSpStat "ENM";
BA_ "SignalLongName" SG_ 1415 ACCAutoStSpStat "Adaptive Cruise Control Information 1 : Adaptive Cruise Control Auto Set Speed Status";
BA_ "SignalType" SG_ 1415 ACCSpdLimSgnUnt "ENM";
BA_ "SignalLongName" SG_ 1415 ACCSpdLimSgnUnt "Adaptive Cruise Control Information 1 : Adaptive Cruise Control Speed Limit Sign Unit";
BA_ "SignalType" SG_ 1415 ACCDrSlctdSpdIndOn "ENM";
BA_ "SignalLongName" SG_ 1415 ACCDrSlctdSpdIndOn "Adaptive Cruise Control Information 1 : Adaptive Cruise Control Driver Selected Speed Indication On";
BA_ "SignalLongName" SG_ 1415 ACCSpdLimSgnVal "Adaptive Cruise Control Information 1 : Adaptive Cruise Control Speed Limit Sign Value";
BA_ "SignalType" SG_ 1415 FrwdImpMtgnOpSlctCstCrStVal "ENM";
BA_ "SignalLongName" SG_ 1415 FrwdImpMtgnOpSlctCstCrStVal "Forward Impact Mitigation Operation Select Customization Current Setting Value";
BA_ "SignalType" SG_ 1415 FrntPCMRspTypCstCrStVal "ENM";
BA_ "SignalLongName" SG_ 1415 FrntPCMRspTypCstCrStVal "Front Pedestrian Collision Mitigation Response Type Customization Current Setting Value";
BA_ "SignalType" SG_ 1415 ACCSysSlctdMd "ENM";
BA_ "SignalLongName" SG_ 1415 ACCSysSlctdMd "Adaptive Cruise Control Information 1 : Adaptive Cruise Control System Selected Mode";
BA_ "SignalType" SG_ 1415 FrntPCMRspTypCstAvlFlg1 "ENM";
BA_ "SignalLongName" SG_ 1415 FrntPCMRspTypCstAvlFlg1 "Front Pedestrian Collision Mitigation Response Type Customization Availability Flag 1";
BA_ "SignalType" SG_ 1415 AutoEmrgBrkgDsbldIndOn "ENM";
BA_ "SignalLongName" SG_ 1415 AutoEmrgBrkgDsbldIndOn "Automatic Emergency Braking Disabled Indication On";
BA_ "SignalType" SG_ 1415 ACCGoNtfrChmEvntSt "ENM";
BA_ "SignalLongName" SG_ 1415 ACCGoNtfrChmEvntSt "Adaptive Cruise Control Go Notifier Chime Event State";
BA_ "SignalType" SG_ 1415 AnmlWrnIndReq "ENM";
BA_ "SignalLongName" SG_ 1415 AnmlWrnIndReq "Animal Warning Indication Request";
BA_ "SignalType" SG_ 1415 FrwdVehAhdIndReq "ENM";
BA_ "SignalLongName" SG_ 1415 FrwdVehAhdIndReq "Forward Vehicle Ahead Indication Request";
BA_ "SignalType" SG_ 1415 FrtPedtrnClsnMtgnAudAttnReqd "ENM";
BA_ "SignalLongName" SG_ 1415 FrtPedtrnClsnMtgnAudAttnReqd "Front Pedestrian Collision Mitigation Audio Attenuation Requested";
BA_ "SignalType" SG_ 1415 FrntPCMRspTypCstStAvl "ENM";
BA_ "SignalLongName" SG_ 1415 FrntPCMRspTypCstStAvl "Front Pedestrian Collision Mitigation Response Type Customization Setting Available";
BA_ "SignalType" SG_ 1415 FrntPCMRspTypCstAvlFlg7 "ENM";
BA_ "SignalLongName" SG_ 1415 FrntPCMRspTypCstAvlFlg7 "Front Pedestrian Collision Mitigation Response Type Customization Availability Flag 7";
BA_ "SignalType" SG_ 1415 FrntPCMRspTypCstAvlFlg6 "ENM";
BA_ "SignalLongName" SG_ 1415 FrntPCMRspTypCstAvlFlg6 "Front Pedestrian Collision Mitigation Response Type Customization Availability Flag 6";
BA_ "SignalType" SG_ 1415 FrntPCMRspTypCstAvlFlg5 "ENM";
BA_ "SignalLongName" SG_ 1415 FrntPCMRspTypCstAvlFlg5 "Front Pedestrian Collision Mitigation Response Type Customization Availability Flag 5";
BA_ "SignalType" SG_ 1415 FrntPCMRspTypCstAvlFlg4 "ENM";
BA_ "SignalLongName" SG_ 1415 FrntPCMRspTypCstAvlFlg4 "Front Pedestrian Collision Mitigation Response Type Customization Availability Flag 4";
BA_ "SignalType" SG_ 1415 FrntPCMRspTypCstAvlFlg3 "ENM";
BA_ "SignalLongName" SG_ 1415 FrntPCMRspTypCstAvlFlg3 "Front Pedestrian Collision Mitigation Response Type Customization Availability Flag 3";
BA_ "SignalType" SG_ 1415 FrntPCMRspTypCstAvlFlg2 "ENM";
BA_ "SignalLongName" SG_ 1415 FrntPCMRspTypCstAvlFlg2 "Front Pedestrian Collision Mitigation Response Type Customization Availability Flag 2";
BA_ "SignalType" SG_ 1415 FrwdImpMtgnOpSlctCstAvlFlg7 "ENM";
BA_ "SignalLongName" SG_ 1415 FrwdImpMtgnOpSlctCstAvlFlg7 "Forward Impact Mitigation Operation Select Customization Availability Flag 7";
BA_ "SignalType" SG_ 1415 FrwdImpMtgnOpSlctCstAvlFlg6 "ENM";
BA_ "SignalLongName" SG_ 1415 FrwdImpMtgnOpSlctCstAvlFlg6 "Forward Impact Mitigation Operation Select Customization Availability Flag 6";
BA_ "SignalType" SG_ 1415 FrwdImpMtgnOpSlctCstAvlFlg5 "ENM";
BA_ "SignalLongName" SG_ 1415 FrwdImpMtgnOpSlctCstAvlFlg5 "Forward Impact Mitigation Operation Select Customization Availability Flag 5";
BA_ "SignalType" SG_ 1415 FrwdImpMtgnOpSlctCstAvlFlg4 "ENM";
BA_ "SignalLongName" SG_ 1415 FrwdImpMtgnOpSlctCstAvlFlg4 "Forward Impact Mitigation Operation Select Customization Availability Flag 4";
BA_ "SignalType" SG_ 1415 FrwdImpMtgnOpSlctCstAvlFlg3 "ENM";
BA_ "SignalLongName" SG_ 1415 FrwdImpMtgnOpSlctCstAvlFlg3 "Forward Impact Mitigation Operation Select Customization Availability Flag 3";
BA_ "SignalType" SG_ 1415 FrwdImpMtgnOpSlctCstAvlFlg2 "ENM";
BA_ "SignalLongName" SG_ 1415 FrwdImpMtgnOpSlctCstAvlFlg2 "Forward Impact Mitigation Operation Select Customization Availability Flag 2";
BA_ "SignalType" SG_ 1415 FrwdImpMtgnOpSlctCstAvlFlg1 "ENM";
BA_ "SignalLongName" SG_ 1415 FrwdImpMtgnOpSlctCstAvlFlg1 "Forward Impact Mitigation Operation Select Customization Availability Flag 1";
BA_ "SignalType" SG_ 1415 FrwdClsnAlrtImntAlrtAudAttnReqd "ENM";
BA_ "SignalLongName" SG_ 1415 FrwdClsnAlrtImntAlrtAudAttnReqd "Forward Collision Alert Imminent Alert Audio Attenuation Requested";
BA_ "SignalType" SG_ 1415 GoNotfrCstAvlFlg7 "ENM";
BA_ "SignalLongName" SG_ 1415 GoNotfrCstAvlFlg7 "Go Notifier Customization Availability Flag 7";
BA_ "SignalType" SG_ 1415 GoNotfrCstAvlFlg6 "ENM";
BA_ "SignalLongName" SG_ 1415 GoNotfrCstAvlFlg6 "Go Notifier Customization Availability Flag 6";
BA_ "SignalType" SG_ 1415 GoNotfrCstAvlFlg5 "ENM";
BA_ "SignalLongName" SG_ 1415 GoNotfrCstAvlFlg5 "Go Notifier Customization Availability Flag 5";
BA_ "SignalType" SG_ 1415 GoNotfrCstAvlFlg4 "ENM";
BA_ "SignalLongName" SG_ 1415 GoNotfrCstAvlFlg4 "Go Notifier Customization Availability Flag 4";
BA_ "SignalType" SG_ 1415 GoNotfrCstAvlFlg3 "ENM";
BA_ "SignalLongName" SG_ 1415 GoNotfrCstAvlFlg3 "Go Notifier Customization Availability Flag 3";
BA_ "SignalType" SG_ 1415 GoNotfrCstAvlFlg2 "ENM";
BA_ "SignalLongName" SG_ 1415 GoNotfrCstAvlFlg2 "Go Notifier Customization Availability Flag 2";
BA_ "SignalType" SG_ 1415 GoNotfrCstAvlFlg1 "ENM";
BA_ "SignalLongName" SG_ 1415 GoNotfrCstAvlFlg1 "Go Notifier Customization Availability Flag 1";
BA_ "SignalType" SG_ 1415 FrwdImpMtgnOpSlctCstStAvl "ENM";
BA_ "SignalLongName" SG_ 1415 FrwdImpMtgnOpSlctCstStAvl "Forward Impact Mitigation Operation Select Customization Setting Available";
BA_ "SignalLongName" SG_ 73 PrplSysSndEnhtAdjdEngTrqEst "Propulsion System Sound Enhancement Information : Propulsion System Sound Enhancement Adjusted Engine Torque Estimate";
BA_ "SignalType" SG_ 73 PrplSysSndEnhtAdjdEngTrqEst_Inv "ENM";
BA_ "SignalLongName" SG_ 73 PrplSysSndEnhtAdjdEngTrqEst_Inv "Propulsion System Sound Enhancement Information : Propulsion System Sound Enhancement Adjusted Engine Torque Estimate Invalid";
BA_ "SignalLongName" SG_ 1147 HVBCC_HrOfDy "High Voltage Battery Charge Complete : Hour of Day";
BA_ "SignalType" SG_ 1147 HVBCC_DyOfWk "ENM";
BA_ "SignalLongName" SG_ 1147 HVBCC_DyOfWk "High Voltage Battery Charge Complete : Day of Week";
BA_ "SignalLongName" SG_ 1147 HVBCC_MinRmn "High Voltage Battery Charge Complete : Minutes Remaining";
BA_ "SignalLongName" SG_ 1147 HVBCC_MinOfHr "High Voltage Battery Charge Complete : Minute of Hour";
BA_ "SignalType" SG_ 1147 HVBCC_TmDispFormat "ENM";
BA_ "SignalLongName" SG_ 1147 HVBCC_TmDispFormat "High Voltage Battery Charge Complete : Time Display Format";
BA_ "SignalType" SG_ 1147 HVBCC_MinRmn_DuD "ENM";
BA_ "SignalLongName" SG_ 1147 HVBCC_MinRmn_DuD "High Voltage Battery Charge Complete : Minutes Remaining Don't Use Data";
BA_ "SignalType" SG_ 1147 HVBCC_TmDispPwrLvl "ENM";
BA_ "SignalLongName" SG_ 1147 HVBCC_TmDispPwrLvl "High Voltage Battery Charge Complete : Time Display Power Level";
BA_ "SignalType" SG_ 1349 ACCAutoSetSpdCstCurrSetVal "ENM";
BA_ "SignalLongName" SG_ 1349 ACCAutoSetSpdCstCurrSetVal "Adaptive Cruise Control Auto Set Speed Customization Current Setting Value";
BA_ "SignalType" SG_ 1349 ACCAutoSetSpdCstAvlFlg7 "ENM";
BA_ "SignalLongName" SG_ 1349 ACCAutoSetSpdCstAvlFlg7 "Adaptive Cruise Control Auto Set Speed Customization Availability Flag 7";
BA_ "SignalType" SG_ 1349 ACCAutoSetSpdCstAvlFlg6 "ENM";
BA_ "SignalLongName" SG_ 1349 ACCAutoSetSpdCstAvlFlg6 "Adaptive Cruise Control Auto Set Speed Customization Availability Flag 6";
BA_ "SignalType" SG_ 1349 ACCAutoSetSpdCstAvlFlg5 "ENM";
BA_ "SignalLongName" SG_ 1349 ACCAutoSetSpdCstAvlFlg5 "Adaptive Cruise Control Auto Set Speed Customization Availability Flag 5";
BA_ "SignalType" SG_ 1349 ACCAutoSetSpdCstAvlFlg4 "ENM";
BA_ "SignalLongName" SG_ 1349 ACCAutoSetSpdCstAvlFlg4 "Adaptive Cruise Control Auto Set Speed Customization Availability Flag 4";
BA_ "SignalType" SG_ 1349 ACCAutoSetSpdCstAvlFlg3 "ENM";
BA_ "SignalLongName" SG_ 1349 ACCAutoSetSpdCstAvlFlg3 "Adaptive Cruise Control Auto Set Speed Customization Availability Flag 3";
BA_ "SignalType" SG_ 1349 ACCAutoSetSpdCstAvlFlg2 "ENM";
BA_ "SignalLongName" SG_ 1349 ACCAutoSetSpdCstAvlFlg2 "Adaptive Cruise Control Auto Set Speed Customization Availability Flag 2";
BA_ "SignalType" SG_ 1349 ACCAutoSetSpdCstAvlFlg1 "ENM";
BA_ "SignalLongName" SG_ 1349 ACCAutoSetSpdCstAvlFlg1 "Adaptive Cruise Control Auto Set Speed Customization Availability Flag 1";
BA_ "SignalLongName" SG_ 1349 LnKpAsstVirtCtlLngPrssDctvtnTm "Lane Keep Assist Virtual Control Long Press Deactivation Time";
BA_ "SignalType" SG_ 1349 LnKpAsstVirtCtlAval "ENM";
BA_ "SignalLongName" SG_ 1349 LnKpAsstVirtCtlAval "Lane Keep Assist Virtual Control Available";
BA_ "SignalType" SG_ 1349 ACCAutoSetSpdUnvIndOn "ENM";
BA_ "SignalLongName" SG_ 1349 ACCAutoSetSpdUnvIndOn "Adaptive Cruise Control Auto Set Speed Unavailable Indication On";
BA_ "SignalType" SG_ 1349 ACCAutoSetSpdCstSetAval "ENM";
BA_ "SignalLongName" SG_ 1349 ACCAutoSetSpdCstSetAval "Adaptive Cruise Control Auto Set Speed Customization Setting Available";
BA_ "SignalType" SG_ 1349 FCASensCstAvlFlg1 "ENM";
BA_ "SignalLongName" SG_ 1349 FCASensCstAvlFlg1 "Forward Collision Alert Sensitivity Customization Availability Flag 1";
BA_ "SignalType" SG_ 1349 FCASensCstCurrSetVal "ENM";
BA_ "SignalLongName" SG_ 1349 FCASensCstCurrSetVal "Forward Collision Alert Sensitivity Customization Current Setting Value";
BA_ "SignalType" SG_ 1349 FCASensCstSetAval "ENM";
BA_ "SignalLongName" SG_ 1349 FCASensCstSetAval "Forward Collision Alert Sensitivity Customization Setting Available";
BA_ "SignalType" SG_ 1349 BlndZnStrgAsstVirtCtlAval "ENM";
BA_ "SignalLongName" SG_ 1349 BlndZnStrgAsstVirtCtlAval "Blind Zone Steering Assist Information : Blind Zone Steering Assist Virtual Control Available";
BA_ "SignalType" SG_ 1349 BlndZnStrgAsstVirtUserCtlAllwd "ENM";
BA_ "SignalLongName" SG_ 1349 BlndZnStrgAsstVirtUserCtlAllwd "Blind Zone Steering Assist Information : Blind Zone Steering Assist Virtual User Control Allowed";
BA_ "SignalType" SG_ 1349 FCASensCstAvlFlg7 "ENM";
BA_ "SignalLongName" SG_ 1349 FCASensCstAvlFlg7 "Forward Collision Alert Sensitivity Customization Availability Flag 7";
BA_ "SignalType" SG_ 1349 FCASensCstAvlFlg6 "ENM";
BA_ "SignalLongName" SG_ 1349 FCASensCstAvlFlg6 "Forward Collision Alert Sensitivity Customization Availability Flag 6";
BA_ "SignalType" SG_ 1349 FCASensCstAvlFlg5 "ENM";
BA_ "SignalLongName" SG_ 1349 FCASensCstAvlFlg5 "Forward Collision Alert Sensitivity Customization Availability Flag 5";
BA_ "SignalType" SG_ 1349 FCASensCstAvlFlg4 "ENM";
BA_ "SignalLongName" SG_ 1349 FCASensCstAvlFlg4 "Forward Collision Alert Sensitivity Customization Availability Flag 4";
BA_ "SignalType" SG_ 1349 FCASensCstAvlFlg3 "ENM";
BA_ "SignalLongName" SG_ 1349 FCASensCstAvlFlg3 "Forward Collision Alert Sensitivity Customization Availability Flag 3";
BA_ "SignalType" SG_ 1349 FCASensCstAvlFlg2 "ENM";
BA_ "SignalLongName" SG_ 1349 FCASensCstAvlFlg2 "Forward Collision Alert Sensitivity Customization Availability Flag 2";
BA_ "SignalType" SG_ 1349 TrfcJamAsstVirtCtlAllwd "ENM";
BA_ "SignalLongName" SG_ 1349 TrfcJamAsstVirtCtlAllwd "Traffic Jam Assist Virtual Control Allowed";
BA_ "SignalType" SG_ 1349 LnDtnWrnSpprssnVrtCtlCurrSltnVl "ENM";
BA_ "SignalLongName" SG_ 1349 LnDtnWrnSpprssnVrtCtlCurrSltnVl "Lane Detection Warning Suppression Information : Lane Detection Warning Suppression Virtual Control Current Selection Value";
BA_ "SignalType" SG_ 1349 LnDtnWrnSpprssnVirtCtlAval "ENM";
BA_ "SignalLongName" SG_ 1349 LnDtnWrnSpprssnVirtCtlAval "Lane Detection Warning Suppression Information : Lane Detection Warning Suppression Virtual Control Available";
BA_ "SignalType" SG_ 1349 LnDtnWrnSpprssnVirtUserCtlAllwd "ENM";
BA_ "SignalLongName" SG_ 1349 LnDtnWrnSpprssnVirtUserCtlAllwd "Lane Detection Warning Suppression Information : Lane Detection Warning Suppression Virtual User Control Allowed";
BA_ "SignalType" SG_ 1349 BlndZnStrgAsstVrtCtlCurrSltnVl "ENM";
BA_ "SignalLongName" SG_ 1349 BlndZnStrgAsstVrtCtlCurrSltnVl "Blind Zone Steering Assist Information : Blind Zone Steering Assist Virtual Control Current Selection Value";
BA_ "SignalType" SG_ 2010 RrStrgModeVirtCtlAval "ENM";
BA_ "SignalLongName" SG_ 2010 RrStrgModeVirtCtlAval "Rear Steering Mode Virtual Control Available";
BA_ "SignalType" SG_ 2010 RrStrgModeSmrtCtlIcnReqd "ENM";
BA_ "SignalLongName" SG_ 2010 RrStrgModeSmrtCtlIcnReqd "Rear Steering Mode Smart Control Icon Requested";
BA_ "SignalType" SG_ 1275 EPBStpOnBrkToRelPrkBrkIndReq "ENM";
BA_ "SignalLongName" SG_ 1275 EPBStpOnBrkToRelPrkBrkIndReq "Electric Park Brake Step On Brake To Release Park Brake Indication Request";
BA_ "SignalType" SG_ 1275 VehStbEnhcmntCustAv "ENM";
BA_ "SignalLongName" SG_ 1275 VehStbEnhcmntCustAv "Vehicle Stability And Traction Control Information : Vehicle Stability Enhancement Customization Available";
BA_ "SignalType" SG_ 1275 VehStbEnhcmntCurStat "ENM";
BA_ "SignalLongName" SG_ 1275 VehStbEnhcmntCurStat "Vehicle Stability And Traction Control Information : Vehicle Stability Enhancement Current State";
BA_ "SignalType" SG_ 1275 VehStbCompMdCustAv "ENM";
BA_ "SignalLongName" SG_ 1275 VehStbCompMdCustAv "Vehicle Stability And Traction Control Information : Vehicle Stability Competitive Mode Customization Available";
BA_ "SignalType" SG_ 1275 VehStbCompMdCurStat "ENM";
BA_ "SignalLongName" SG_ 1275 VehStbCompMdCurStat "Vehicle Stability And Traction Control Information : Vehicle Stability Competitive Mode Current State";
BA_ "SignalType" SG_ 1275 TrcCntrlSysTmpDisReqIO "ENM";
BA_ "SignalLongName" SG_ 1275 TrcCntrlSysTmpDisReqIO "Vehicle Stability And Traction Control Information : Traction Control System Temporary Disable Request Indication On";
BA_ "SignalType" SG_ 1275 TCSCustAv "ENM";
BA_ "SignalLongName" SG_ 1275 TCSCustAv "Vehicle Stability And Traction Control Information : Traction Control System Customization Available";
BA_ "SignalType" SG_ 1275 TCSCurStat "ENM";
BA_ "SignalLongName" SG_ 1275 TCSCurStat "Vehicle Stability And Traction Control Information : Traction Control System Current State";
BA_ "SignalType" SG_ 1275 OffRdMdActvAerodynsVisDispVal "ENM";
BA_ "SignalLongName" SG_ 1275 OffRdMdActvAerodynsVisDispVal "Off Road Mode Active Aerodynamics Visualization Display Value";
BA_ "SignalType" SG_ 1275 ElecPrkBrkSysDisIndReq "ENM";
BA_ "SignalLongName" SG_ 1275 ElecPrkBrkSysDisIndReq "Electric Park Brake System Display Indication Request";
BA_ "SignalType" SG_ 1275 OffRdMdESCVisDispVal "ENM";
BA_ "SignalLongName" SG_ 1275 OffRdMdESCVisDispVal "Off Road Mode ESC Visualization Display Value";
BA_ "SignalType" SG_ 1275 OffRdMdDrvlnVisDispVal "ENM";
BA_ "SignalLongName" SG_ 1275 OffRdMdDrvlnVisDispVal "Off Road Mode Driveline Visualization Display Value";
BA_ "SignalType" SG_ 1275 OffRdMdBrkPedVisDispVal "ENM";
BA_ "SignalLongName" SG_ 1275 OffRdMdBrkPedVisDispVal "Off Road Mode Brake Pedal Visualization Display Value";
BA_ "SignalType" SG_ 1275 OffRdMdSndVisDispVal "ENM";
BA_ "SignalLongName" SG_ 1275 OffRdMdSndVisDispVal "Off Road Mode Sound Visualization Display Value";
BA_ "SignalType" SG_ 1275 OffRdMdRideHghtVisDispVal "ENM";
BA_ "SignalLongName" SG_ 1275 OffRdMdRideHghtVisDispVal "Off Road Mode Ride Height Visualization Display Value";
BA_ "SignalType" SG_ 1275 OffRdMdPwrtrnVisDispVal "ENM";
BA_ "SignalLongName" SG_ 1275 OffRdMdPwrtrnVisDispVal "Off Road Mode Powertrain Visualization Display Value";
BA_ "SignalType" SG_ 1275 OffRdMdStrgVisDispVal "ENM";
BA_ "SignalLongName" SG_ 1275 OffRdMdStrgVisDispVal "Off Road Mode Steering Visualization Display Value";
BA_ "SignalType" SG_ 1275 OffRdMdSpnsnVisDispVal "ENM";
BA_ "SignalLongName" SG_ 1275 OffRdMdSpnsnVisDispVal "Off Road Mode Suspension Visualization Display Value";
BA_ "SignalType" SG_ 1275 ESCInitIO "ENM";
BA_ "SignalLongName" SG_ 1275 ESCInitIO "Electronic Stability Control Initializing Indication On";
BA_ "SignalType" SG_ 1275 ESCCmptMdIO "ENM";
BA_ "SignalLongName" SG_ 1275 ESCCmptMdIO "ElectronicStabilityControlCompetitiveModeIndicationOn";
BA_ "SignalType" SG_ 1275 TrlrBrkgSysProfSts "ENM";
BA_ "SignalLongName" SG_ 1275 TrlrBrkgSysProfSts "Trailer Braking System Profile Status";
BA_ "SignalType" SG_ 1275 PerfMdMainMenuTy "ENM";
BA_ "SignalLongName" SG_ 1275 PerfMdMainMenuTy "Performance Mode Main Menu Type";
BA_ "SignalType" SG_ 1275 TrlrBrkCnctdIndOn "ENM";
BA_ "SignalLongName" SG_ 1275 TrlrBrkCnctdIndOn "Trailer Brakes Connected Indication On";
BA_ "SignalType" SG_ 1275 SrvESCMdIO "ENM";
BA_ "SignalLongName" SG_ 1275 SrvESCMdIO "Service Electronic Stability Control Indication On";
BA_ "SignalType" SG_ 1275 ServTracCtlIndOn "ENM";
BA_ "SignalLongName" SG_ 1275 ServTracCtlIndOn "Service Traction Control Indication On";
BA_ "SignalType" SG_ 1275 RdcBrkgToAvoidOvrhtgIndOn "ENM";
BA_ "SignalLongName" SG_ 1275 RdcBrkgToAvoidOvrhtgIndOn "Reduce Braking To Avoid Overheating Indication On";
BA_ "SignalType" SG_ 1275 HillStrtAstActIO "ENM";
BA_ "SignalLongName" SG_ 1275 HillStrtAstActIO "Hill Start Assist Active Indication On";
BA_ "SignalType" SG_ 1275 HillRollCntrlActIO "ENM";
BA_ "SignalLongName" SG_ 1275 HillRollCntrlActIO "Hill Rollback Control Active Indication On";
BA_ "SignalType" SG_ 1275 ESCPrfMdIO "ENM";
BA_ "SignalLongName" SG_ 1275 ESCPrfMdIO "Electronic Stability Control Performance Mode Indication On";
BA_ "SignalType" SG_ 1275 ESCOffIO "ENM";
BA_ "SignalLongName" SG_ 1275 ESCOffIO "Electronic Stability Control Off Indication On";
BA_ "SignalType" SG_ 1275 BrkSysDrftModeUnvWrnIndReq "ENM";
BA_ "SignalLongName" SG_ 1275 BrkSysDrftModeUnvWrnIndReq "Brake System Drift Mode Information : Brake System Drift Mode Unavailable Warning Indication Request";
BA_ "SignalType" SG_ 1275 BrkSysDrftModeDispSts "ENM";
BA_ "SignalLongName" SG_ 1275 BrkSysDrftModeDispSts "Brake System Drift Mode Information : Brake System Drift Mode Display Status";
BA_ "SignalType" SG_ 1275 BrkSysDrftModeSeltnIndOn "ENM";
BA_ "SignalLongName" SG_ 1275 BrkSysDrftModeSeltnIndOn "Brake System Drift Mode Information : Brake System Drift Mode Selection Indication On";
BA_ "SignalLongName" SG_ 1274 BrkPadLifeFrt "Brake Pad Life Front";
BA_ "SignalType" SG_ 1274 BrkPadLifeFrt_Inv "ENM";
BA_ "SignalLongName" SG_ 1274 BrkPadLifeFrt_Inv "Brake Pad Life Front Invalid";
BA_ "SignalLongName" SG_ 1274 BrkPadLifeRr "Brake Pad Life Rear";
BA_ "SignalType" SG_ 1274 BrkPadLifeRr_Inv "ENM";
BA_ "SignalLongName" SG_ 1274 BrkPadLifeRr_Inv "Brake Pad Life Rear Invalid";
BA_ "SignalType" SG_ 1274 TowHaulMdBrkPedVisDispVal "ENM";
BA_ "SignalLongName" SG_ 1274 TowHaulMdBrkPedVisDispVal "Tow Haul Mode Brake Pedal Visualization Display Value";
BA_ "SignalType" SG_ 1274 TowHaulMdActvAerodynsVisDispVal "ENM";
BA_ "SignalLongName" SG_ 1274 TowHaulMdActvAerodynsVisDispVal "Tow Haul Mode Active Aerodynamics Visualization Display Value";
BA_ "SignalType" SG_ 1274 BrkTempStsIndReq "ENM";
BA_ "SignalLongName" SG_ 1274 BrkTempStsIndReq "Brakes Temperature Status Indication Request";
BA_ "SignalType" SG_ 1274 TowHaulMdPwrtrnVisDispVal "ENM";
BA_ "SignalLongName" SG_ 1274 TowHaulMdPwrtrnVisDispVal "Tow Haul Mode Powertrain Visualization Display Value";
BA_ "SignalType" SG_ 1274 TowHaulMdESCVisDispVal "ENM";
BA_ "SignalLongName" SG_ 1274 TowHaulMdESCVisDispVal "Tow Haul Mode ESC Visualization Display Value";
BA_ "SignalType" SG_ 1274 TowHaulMdDrvlnVisDispVal "ENM";
BA_ "SignalLongName" SG_ 1274 TowHaulMdDrvlnVisDispVal "Tow Haul Mode Driveline Visualization Display Value";
BA_ "SignalType" SG_ 1274 TowHaulMdSndVisDispVal "ENM";
BA_ "SignalLongName" SG_ 1274 TowHaulMdSndVisDispVal "Tow Haul Mode Sound Visualization Display Value";
BA_ "SignalType" SG_ 1274 TowHaulMdRideHghtVisDispVal "ENM";
BA_ "SignalLongName" SG_ 1274 TowHaulMdRideHghtVisDispVal "Tow Haul Mode Ride Height Visualization Display Value";
BA_ "SignalType" SG_ 1274 AutoHldActv "ENM";
BA_ "SignalLongName" SG_ 1274 AutoHldActv "Auto Hold Active";
BA_ "SignalType" SG_ 1274 ABSActvIndOn "ENM";
BA_ "SignalLongName" SG_ 1274 ABSActvIndOn "Antilock Braking System Active Indication On";
BA_ "SignalType" SG_ 1274 TowHaulMdStrgVisDispVal "ENM";
BA_ "SignalLongName" SG_ 1274 TowHaulMdStrgVisDispVal "Tow Haul Mode Steering Visualization Display Value";
BA_ "SignalType" SG_ 1274 TowHaulMdSpnsnVisDispVal "ENM";
BA_ "SignalLongName" SG_ 1274 TowHaulMdSpnsnVisDispVal "Tow Haul Mode Suspension Visualization Display Value";
BA_ "SignalType" SG_ 1274 BrkPadLifeRrRstAval "ENM";
BA_ "SignalLongName" SG_ 1274 BrkPadLifeRrRstAval "Brake Pad Life Rear Reset Available";
BA_ "SignalType" SG_ 1274 BrkPadLifeFrtRstAval "ENM";
BA_ "SignalLongName" SG_ 1274 BrkPadLifeFrtRstAval "Brake Pad Life Front Reset Available";
BA_ "SignalType" SG_ 1274 AutoHldServIndOn "ENM";
BA_ "SignalLongName" SG_ 1274 AutoHldServIndOn "Auto Hold Service Indication On";
BA_ "SignalType" SG_ 1274 AutoHldDsbldStBltIndOn "ENM";
BA_ "SignalLongName" SG_ 1274 AutoHldDsbldStBltIndOn "Auto Hold Disabled Seatbelt Indication On";
BA_ "SignalType" SG_ 1274 AutoHldDsbldDrOpnIndOn "ENM";
BA_ "SignalLongName" SG_ 1274 AutoHldDsbldDrOpnIndOn "Auto Hold Disabled Door Open Indication On";
BA_ "SignalType" SG_ 1274 AutoHldAppBrkPedIndOn "ENM";
BA_ "SignalLongName" SG_ 1274 AutoHldAppBrkPedIndOn "Auto Hold Apply Brake Pedal Indication On";
BA_ "SignalType" SG_ 1491 CustMdDrvlCstmCurSetVal "ENM";
BA_ "SignalLongName" SG_ 1491 CustMdDrvlCstmCurSetVal "Custom Mode Driveline Customization Current Setting Value";
BA_ "SignalType" SG_ 1491 CustMdBrkPdlCstmCurSetVal "ENM";
BA_ "SignalLongName" SG_ 1491 CustMdBrkPdlCstmCurSetVal "Custom Mode Brake Pedal Customization Current Setting Value";
BA_ "SignalType" SG_ 1491 CustMdActAeroCstmCurSetVal "ENM";
BA_ "SignalLongName" SG_ 1491 CustMdActAeroCstmCurSetVal "Custom Mode Active Aero Customization Current Setting Value";
BA_ "SignalType" SG_ 1491 CustMdRideHghtCstmCurSetVal "ENM";
BA_ "SignalLongName" SG_ 1491 CustMdRideHghtCstmCurSetVal "Custom Mode Ride Height Customization Current Setting Value";
BA_ "SignalType" SG_ 1491 CustMdPTCstmPndSetVal "ENM";
BA_ "SignalLongName" SG_ 1491 CustMdPTCstmPndSetVal "Custom Mode Powertrain Customization Pending Setting Value";
BA_ "SignalType" SG_ 1491 CustMdPTCstmCurSetVal "ENM";
BA_ "SignalLongName" SG_ 1491 CustMdPTCstmCurSetVal "Custom Mode Powertrain Customization Current Setting Value";
BA_ "SignalType" SG_ 1491 CustMdSpnCstmCurSetVal "ENM";
BA_ "SignalLongName" SG_ 1491 CustMdSpnCstmCurSetVal "Custom Mode Suspension Customization Current Setting Value";
BA_ "SignalType" SG_ 1491 CustMdSndCstmCurSetVal "ENM";
BA_ "SignalLongName" SG_ 1491 CustMdSndCstmCurSetVal "Custom Mode Sound Customization Current Setting Value";
BA_ "SignalType" SG_ 1491 DisPrfMdRq "ENM";
BA_ "SignalLongName" SG_ 1491 DisPrfMdRq "Display Performance Mode Request";
BA_ "SignalType" SG_ 1491 CustMdTrcStbCstmCurSetVal "ENM";
BA_ "SignalLongName" SG_ 1491 CustMdTrcStbCstmCurSetVal "Custom Mode Traction Stability Customization Current Setting Value";
BA_ "SignalType" SG_ 1491 CustMdStrCstmCurSetVal "ENM";
BA_ "SignalLongName" SG_ 1491 CustMdStrCstmCurSetVal "Custom Mode Steering Customization Current Setting Value";
BA_ "SignalType" SG_ 1491 PrsnlMdBrkPdlCstmCurSetVal "ENM";
BA_ "SignalLongName" SG_ 1491 PrsnlMdBrkPdlCstmCurSetVal "Personal Mode Brake Pedal Customization Current Setting Value";
BA_ "SignalType" SG_ 1491 PrsnlMdActAeroCstmCurSetVal "ENM";
BA_ "SignalLongName" SG_ 1491 PrsnlMdActAeroCstmCurSetVal "Personal Mode Active Aero Customization Current Setting Value";
BA_ "SignalType" SG_ 1491 ExtdHillStrtAstCustCurSetVal "ENM";
BA_ "SignalLongName" SG_ 1491 ExtdHillStrtAstCustCurSetVal "Extended Hill Start Assist Customization Current Setting Value";
BA_ "SignalType" SG_ 1491 PrsnlMdRideHghtCstmCurSetVal "ENM";
BA_ "SignalLongName" SG_ 1491 PrsnlMdRideHghtCstmCurSetVal "Personal Mode Ride Height Customization Current Setting Value";
BA_ "SignalType" SG_ 1491 PrsnlMdDrvlCstmCurSetVal "ENM";
BA_ "SignalLongName" SG_ 1491 PrsnlMdDrvlCstmCurSetVal "Personal Mode Driveline Customization Current Setting Value";
BA_ "SignalType" SG_ 1491 CustMdStrCstmSetAv "ENM";
BA_ "SignalLongName" SG_ 1491 CustMdStrCstmSetAv "Custom Mode Steering Customization Setting Available";
BA_ "SignalType" SG_ 1491 CustMdSpnCstmSetAv "ENM";
BA_ "SignalLongName" SG_ 1491 CustMdSpnCstmSetAv "Custom Mode Suspension Customization Setting Available";
BA_ "SignalType" SG_ 1491 CustMdSndCstmSetAv "ENM";
BA_ "SignalLongName" SG_ 1491 CustMdSndCstmSetAv "Custom Mode Sound Customization Setting Available";
BA_ "SignalType" SG_ 1491 CustMdRideHghtCstmSetAv "ENM";
BA_ "SignalLongName" SG_ 1491 CustMdRideHghtCstmSetAv "Custom Mode Ride Height Customization Setting Available";
BA_ "SignalType" SG_ 1491 CustMdPTCstmSetAv "ENM";
BA_ "SignalLongName" SG_ 1491 CustMdPTCstmSetAv "Custom Mode Powertrain Customization Setting Available";
BA_ "SignalType" SG_ 1491 CustMdDrvlCstmSetAv "ENM";
BA_ "SignalLongName" SG_ 1491 CustMdDrvlCstmSetAv "Custom Mode Driveline Customization Setting Available";
BA_ "SignalType" SG_ 1491 CustMdBrkPdlCstmSetAv "ENM";
BA_ "SignalLongName" SG_ 1491 CustMdBrkPdlCstmSetAv "Custom Mode Brake Pedal Customization Setting Available";
BA_ "SignalType" SG_ 1491 CustMdActAeroCstmSetAv "ENM";
BA_ "SignalLongName" SG_ 1491 CustMdActAeroCstmSetAv "Custom Mode Active Aero Customization Setting Available";
BA_ "SignalType" SG_ 1491 PrsnlMdSpnCstmSetAv "ENM";
BA_ "SignalLongName" SG_ 1491 PrsnlMdSpnCstmSetAv "Personal Mode Suspension Customization Setting Available";
BA_ "SignalType" SG_ 1491 PrsnlMdSndCstmSetAv "ENM";
BA_ "SignalLongName" SG_ 1491 PrsnlMdSndCstmSetAv "Personal Mode Sound Customization Setting Available";
BA_ "SignalType" SG_ 1491 PrsnlMdRideHghtCstmSetAv "ENM";
BA_ "SignalLongName" SG_ 1491 PrsnlMdRideHghtCstmSetAv "Personal Mode Ride Height Customization Setting Available";
BA_ "SignalType" SG_ 1491 PrsnlMdDrvlCstmSetAv "ENM";
BA_ "SignalLongName" SG_ 1491 PrsnlMdDrvlCstmSetAv "Personal Mode Driveline Customization Setting Available";
BA_ "SignalType" SG_ 1491 PrsnlMdBrkPdlCstmSetAv "ENM";
BA_ "SignalLongName" SG_ 1491 PrsnlMdBrkPdlCstmSetAv "Personal Mode Brake Pedal Customization Setting Available";
BA_ "SignalType" SG_ 1491 PrsnlMdActAeroCstmSetAv "ENM";
BA_ "SignalLongName" SG_ 1491 PrsnlMdActAeroCstmSetAv "Personal Mode Active Aero Customization Setting Available";
BA_ "SignalType" SG_ 1491 ExtdHillStrtAstCustSetAvl "ENM";
BA_ "SignalLongName" SG_ 1491 ExtdHillStrtAstCustSetAvl "Extended Hill Start Assist Customization Setting Available";
BA_ "SignalType" SG_ 1491 CustMdTrcStbCstmSetAv "ENM";
BA_ "SignalLongName" SG_ 1491 CustMdTrcStbCstmSetAv "Custom Mode Traction Stability Customization Setting Available";
BA_ "SignalType" SG_ 1882 CustMdBrkPdlCstmAvFlg1 "ENM";
BA_ "SignalLongName" SG_ 1882 CustMdBrkPdlCstmAvFlg1 "Custom Mode Brake Pedal Customization Availability Flag 1";
BA_ "SignalType" SG_ 1882 CustMdActAeroCstmAvFlg7 "ENM";
BA_ "SignalLongName" SG_ 1882 CustMdActAeroCstmAvFlg7 "Custom Mode Active Aero Customization Availability Flag 7";
BA_ "SignalType" SG_ 1882 CustMdActAeroCstmAvFlg6 "ENM";
BA_ "SignalLongName" SG_ 1882 CustMdActAeroCstmAvFlg6 "Custom Mode Active Aero Customization Availability Flag 6";
BA_ "SignalType" SG_ 1882 CustMdActAeroCstmAvFlg5 "ENM";
BA_ "SignalLongName" SG_ 1882 CustMdActAeroCstmAvFlg5 "Custom Mode Active Aero Customization Availability Flag 5";
BA_ "SignalType" SG_ 1882 CustMdActAeroCstmAvFlg4 "ENM";
BA_ "SignalLongName" SG_ 1882 CustMdActAeroCstmAvFlg4 "Custom Mode Active Aero Customization Availability Flag 4";
BA_ "SignalType" SG_ 1882 CustMdActAeroCstmAvFlg3 "ENM";
BA_ "SignalLongName" SG_ 1882 CustMdActAeroCstmAvFlg3 "Custom Mode Active Aero Customization Availability Flag 3";
BA_ "SignalType" SG_ 1882 CustMdActAeroCstmAvFlg2 "ENM";
BA_ "SignalLongName" SG_ 1882 CustMdActAeroCstmAvFlg2 "Custom Mode Active Aero Customization Availability Flag 2";
BA_ "SignalType" SG_ 1882 CustMdActAeroCstmAvFlg1 "ENM";
BA_ "SignalLongName" SG_ 1882 CustMdActAeroCstmAvFlg1 "Custom Mode Active Aero Customization Availability Flag 1";
BA_ "SignalType" SG_ 1882 CustMdDrvlCstmAvFlg2 "ENM";
BA_ "SignalLongName" SG_ 1882 CustMdDrvlCstmAvFlg2 "Custom Mode Driveline Customization Availability Flag 2";
BA_ "SignalType" SG_ 1882 CustMdDrvlCstmAvFlg1 "ENM";
BA_ "SignalLongName" SG_ 1882 CustMdDrvlCstmAvFlg1 "Custom Mode Driveline Customization Availability Flag 1";
BA_ "SignalType" SG_ 1882 CustMdBrkPdlCstmAvFlg7 "ENM";
BA_ "SignalLongName" SG_ 1882 CustMdBrkPdlCstmAvFlg7 "Custom Mode Brake Pedal Customization Availability Flag 7";
BA_ "SignalType" SG_ 1882 CustMdBrkPdlCstmAvFlg6 "ENM";
BA_ "SignalLongName" SG_ 1882 CustMdBrkPdlCstmAvFlg6 "Custom Mode Brake Pedal Customization Availability Flag 6";
BA_ "SignalType" SG_ 1882 CustMdBrkPdlCstmAvFlg5 "ENM";
BA_ "SignalLongName" SG_ 1882 CustMdBrkPdlCstmAvFlg5 "Custom Mode Brake Pedal Customization Availability Flag 5";
BA_ "SignalType" SG_ 1882 CustMdBrkPdlCstmAvFlg4 "ENM";
BA_ "SignalLongName" SG_ 1882 CustMdBrkPdlCstmAvFlg4 "Custom Mode Brake Pedal Customization Availability Flag 4";
BA_ "SignalType" SG_ 1882 CustMdBrkPdlCstmAvFlg3 "ENM";
BA_ "SignalLongName" SG_ 1882 CustMdBrkPdlCstmAvFlg3 "Custom Mode Brake Pedal Customization Availability Flag 3";
BA_ "SignalType" SG_ 1882 CustMdBrkPdlCstmAvFlg2 "ENM";
BA_ "SignalLongName" SG_ 1882 CustMdBrkPdlCstmAvFlg2 "Custom Mode Brake Pedal Customization Availability Flag 2";
BA_ "SignalType" SG_ 1882 CustMdPTCstmAvFlg3 "ENM";
BA_ "SignalLongName" SG_ 1882 CustMdPTCstmAvFlg3 "Custom Mode Powertrain Customization Availability Flag 3";
BA_ "SignalType" SG_ 1882 CustMdPTCstmAvFlg2 "ENM";
BA_ "SignalLongName" SG_ 1882 CustMdPTCstmAvFlg2 "Custom Mode Powertrain Customization Availability Flag 2";
BA_ "SignalType" SG_ 1882 CustMdPTCstmAvFlg1 "ENM";
BA_ "SignalLongName" SG_ 1882 CustMdPTCstmAvFlg1 "Custom Mode Powertrain Customization Availability Flag 1";
BA_ "SignalType" SG_ 1882 CustMdDrvlCstmAvFlg7 "ENM";
BA_ "SignalLongName" SG_ 1882 CustMdDrvlCstmAvFlg7 "Custom Mode Driveline Customization Availability Flag 7";
BA_ "SignalType" SG_ 1882 CustMdDrvlCstmAvFlg6 "ENM";
BA_ "SignalLongName" SG_ 1882 CustMdDrvlCstmAvFlg6 "Custom Mode Driveline Customization Availability Flag 6";
BA_ "SignalType" SG_ 1882 CustMdDrvlCstmAvFlg5 "ENM";
BA_ "SignalLongName" SG_ 1882 CustMdDrvlCstmAvFlg5 "Custom Mode Driveline Customization Availability Flag 5";
BA_ "SignalType" SG_ 1882 CustMdDrvlCstmAvFlg4 "ENM";
BA_ "SignalLongName" SG_ 1882 CustMdDrvlCstmAvFlg4 "Custom Mode Driveline Customization Availability Flag 4";
BA_ "SignalType" SG_ 1882 CustMdDrvlCstmAvFlg3 "ENM";
BA_ "SignalLongName" SG_ 1882 CustMdDrvlCstmAvFlg3 "Custom Mode Driveline Customization Availability Flag 3";
BA_ "SignalType" SG_ 1882 CustMdRideHghtCstmAvFlg4 "ENM";
BA_ "SignalLongName" SG_ 1882 CustMdRideHghtCstmAvFlg4 "Custom Mode Ride Height Customization Availability Flag 4";
BA_ "SignalType" SG_ 1882 CustMdRideHghtCstmAvFlg3 "ENM";
BA_ "SignalLongName" SG_ 1882 CustMdRideHghtCstmAvFlg3 "Custom Mode Ride Height Customization Availability Flag 3";
BA_ "SignalType" SG_ 1882 CustMdRideHghtCstmAvFlg2 "ENM";
BA_ "SignalLongName" SG_ 1882 CustMdRideHghtCstmAvFlg2 "Custom Mode Ride Height Customization Availability Flag 2";
BA_ "SignalType" SG_ 1882 CustMdRideHghtCstmAvFlg1 "ENM";
BA_ "SignalLongName" SG_ 1882 CustMdRideHghtCstmAvFlg1 "Custom Mode Ride Height Customization Availability Flag 1";
BA_ "SignalType" SG_ 1882 CustMdPTCstmAvFlg7 "ENM";
BA_ "SignalLongName" SG_ 1882 CustMdPTCstmAvFlg7 "Custom Mode Powertrain Customization Availability Flag 7";
BA_ "SignalType" SG_ 1882 CustMdPTCstmAvFlg6 "ENM";
BA_ "SignalLongName" SG_ 1882 CustMdPTCstmAvFlg6 "Custom Mode Powertrain Customization Availability Flag 6";
BA_ "SignalType" SG_ 1882 CustMdPTCstmAvFlg5 "ENM";
BA_ "SignalLongName" SG_ 1882 CustMdPTCstmAvFlg5 "Custom Mode Powertrain Customization Availability Flag 5";
BA_ "SignalType" SG_ 1882 CustMdPTCstmAvFlg4 "ENM";
BA_ "SignalLongName" SG_ 1882 CustMdPTCstmAvFlg4 "Custom Mode Powertrain Customization Availability Flag 4";
BA_ "SignalType" SG_ 1882 CustMdSndCstmAvFlg5 "ENM";
BA_ "SignalLongName" SG_ 1882 CustMdSndCstmAvFlg5 "Custom Mode Sound Customization Availability Flag 5";
BA_ "SignalType" SG_ 1882 CustMdSndCstmAvFlg4 "ENM";
BA_ "SignalLongName" SG_ 1882 CustMdSndCstmAvFlg4 "Custom Mode Sound Customization Availability Flag 4";
BA_ "SignalType" SG_ 1882 CustMdSndCstmAvFlg3 "ENM";
BA_ "SignalLongName" SG_ 1882 CustMdSndCstmAvFlg3 "Custom Mode Sound Customization Availability Flag 3";
BA_ "SignalType" SG_ 1882 CustMdSndCstmAvFlg2 "ENM";
BA_ "SignalLongName" SG_ 1882 CustMdSndCstmAvFlg2 "Custom Mode Sound Customization Availability Flag 2";
BA_ "SignalType" SG_ 1882 CustMdSndCstmAvFlg1 "ENM";
BA_ "SignalLongName" SG_ 1882 CustMdSndCstmAvFlg1 "Custom Mode Sound Customization Availability Flag 1";
BA_ "SignalType" SG_ 1882 CustMdRideHghtCstmAvFlg7 "ENM";
BA_ "SignalLongName" SG_ 1882 CustMdRideHghtCstmAvFlg7 "Custom Mode Ride Height Customization Availability Flag 7";
BA_ "SignalType" SG_ 1882 CustMdRideHghtCstmAvFlg6 "ENM";
BA_ "SignalLongName" SG_ 1882 CustMdRideHghtCstmAvFlg6 "Custom Mode Ride Height Customization Availability Flag 6";
BA_ "SignalType" SG_ 1882 CustMdRideHghtCstmAvFlg5 "ENM";
BA_ "SignalLongName" SG_ 1882 CustMdRideHghtCstmAvFlg5 "Custom Mode Ride Height Customization Availability Flag 5";
BA_ "SignalType" SG_ 1882 CustMdSpnCstmAvFlg6 "ENM";
BA_ "SignalLongName" SG_ 1882 CustMdSpnCstmAvFlg6 "Custom Mode Suspension Customization Availability Flag 6";
BA_ "SignalType" SG_ 1882 CustMdSpnCstmAvFlg5 "ENM";
BA_ "SignalLongName" SG_ 1882 CustMdSpnCstmAvFlg5 "Custom Mode Suspension Customization Availability Flag 5";
BA_ "SignalType" SG_ 1882 CustMdSpnCstmAvFlg4 "ENM";
BA_ "SignalLongName" SG_ 1882 CustMdSpnCstmAvFlg4 "Custom Mode Suspension Customization Availability Flag 4";
BA_ "SignalType" SG_ 1882 CustMdSpnCstmAvFlg3 "ENM";
BA_ "SignalLongName" SG_ 1882 CustMdSpnCstmAvFlg3 "Custom Mode Suspension Customization Availability Flag 3";
BA_ "SignalType" SG_ 1882 CustMdSpnCstmAvFlg2 "ENM";
BA_ "SignalLongName" SG_ 1882 CustMdSpnCstmAvFlg2 "Custom Mode Suspension Customization Availability Flag 2";
BA_ "SignalType" SG_ 1882 CustMdSpnCstmAvFlg1 "ENM";
BA_ "SignalLongName" SG_ 1882 CustMdSpnCstmAvFlg1 "Custom Mode Suspension Customization Availability Flag 1";
BA_ "SignalType" SG_ 1882 CustMdSndCstmAvFlg7 "ENM";
BA_ "SignalLongName" SG_ 1882 CustMdSndCstmAvFlg7 "Custom Mode Sound Customization Availability Flag 7";
BA_ "SignalType" SG_ 1882 CustMdSndCstmAvFlg6 "ENM";
BA_ "SignalLongName" SG_ 1882 CustMdSndCstmAvFlg6 "Custom Mode Sound Customization Availability Flag 6";
BA_ "SignalType" SG_ 1882 CustMdStrCstmAvFlg7 "ENM";
BA_ "SignalLongName" SG_ 1882 CustMdStrCstmAvFlg7 "Custom Mode Steering Customization Availability Flag 7";
BA_ "SignalType" SG_ 1882 CustMdStrCstmAvFlg6 "ENM";
BA_ "SignalLongName" SG_ 1882 CustMdStrCstmAvFlg6 "Custom Mode Steering Customization Availability Flag 6";
BA_ "SignalType" SG_ 1882 CustMdStrCstmAvFlg5 "ENM";
BA_ "SignalLongName" SG_ 1882 CustMdStrCstmAvFlg5 "Custom Mode Steering Customization Availability Flag 5";
BA_ "SignalType" SG_ 1882 CustMdStrCstmAvFlg4 "ENM";
BA_ "SignalLongName" SG_ 1882 CustMdStrCstmAvFlg4 "Custom Mode Steering Customization Availability Flag 4";
BA_ "SignalType" SG_ 1882 CustMdStrCstmAvFlg3 "ENM";
BA_ "SignalLongName" SG_ 1882 CustMdStrCstmAvFlg3 "Custom Mode Steering Customization Availability Flag 3";
BA_ "SignalType" SG_ 1882 CustMdStrCstmAvFlg2 "ENM";
BA_ "SignalLongName" SG_ 1882 CustMdStrCstmAvFlg2 "Custom Mode Steering Customization Availability Flag 2";
BA_ "SignalType" SG_ 1882 CustMdStrCstmAvFlg1 "ENM";
BA_ "SignalLongName" SG_ 1882 CustMdStrCstmAvFlg1 "Custom Mode Steering Customization Availability Flag 1";
BA_ "SignalType" SG_ 1882 CustMdSpnCstmAvFlg7 "ENM";
BA_ "SignalLongName" SG_ 1882 CustMdSpnCstmAvFlg7 "Custom Mode Suspension Customization Availability Flag 7";
BA_ "SignalType" SG_ 1882 EBDFld "ENM";
BA_ "SignalLongName" SG_ 1882 EBDFld "Electronic Brake Distribution Failed";
BA_ "SignalType" SG_ 1882 CustMdTrcStbCstmAvFlg7 "ENM";
BA_ "SignalLongName" SG_ 1882 CustMdTrcStbCstmAvFlg7 "Custom Mode Traction Stability Customization Availability Flag 7";
BA_ "SignalType" SG_ 1882 CustMdTrcStbCstmAvFlg6 "ENM";
BA_ "SignalLongName" SG_ 1882 CustMdTrcStbCstmAvFlg6 "Custom Mode Traction Stability Customization Availability Flag 6";
BA_ "SignalType" SG_ 1882 CustMdTrcStbCstmAvFlg5 "ENM";
BA_ "SignalLongName" SG_ 1882 CustMdTrcStbCstmAvFlg5 "Custom Mode Traction Stability Customization Availability Flag 5";
BA_ "SignalType" SG_ 1882 CustMdTrcStbCstmAvFlg4 "ENM";
BA_ "SignalLongName" SG_ 1882 CustMdTrcStbCstmAvFlg4 "Custom Mode Traction Stability Customization Availability Flag 4";
BA_ "SignalType" SG_ 1882 CustMdTrcStbCstmAvFlg3 "ENM";
BA_ "SignalLongName" SG_ 1882 CustMdTrcStbCstmAvFlg3 "Custom Mode Traction Stability Customization Availability Flag 3";
BA_ "SignalType" SG_ 1882 CustMdTrcStbCstmAvFlg2 "ENM";
BA_ "SignalLongName" SG_ 1882 CustMdTrcStbCstmAvFlg2 "Custom Mode Traction Stability Customization Availability Flag 2";
BA_ "SignalType" SG_ 1882 CustMdTrcStbCstmAvFlg1 "ENM";
BA_ "SignalLongName" SG_ 1882 CustMdTrcStbCstmAvFlg1 "Custom Mode Traction Stability Customization Availability Flag 1";
BA_ "SignalType" SG_ 1183 PrsnlMdActAeroCstmAvFlg1 "ENM";
BA_ "SignalLongName" SG_ 1183 PrsnlMdActAeroCstmAvFlg1 "Personal Mode Active Aero Customization Availability Flag 1";
BA_ "SignalType" SG_ 1183 ExtdHillStrtAstCustAvlFlg7 "ENM";
BA_ "SignalLongName" SG_ 1183 ExtdHillStrtAstCustAvlFlg7 "Extended Hill Start Assist Customization Availability Flag 7";
BA_ "SignalType" SG_ 1183 ExtdHillStrtAstCustAvlFlg6 "ENM";
BA_ "SignalLongName" SG_ 1183 ExtdHillStrtAstCustAvlFlg6 "Extended Hill Start Assist Customization Availability Flag 6";
BA_ "SignalType" SG_ 1183 ExtdHillStrtAstCustAvlFlg5 "ENM";
BA_ "SignalLongName" SG_ 1183 ExtdHillStrtAstCustAvlFlg5 "Extended Hill Start Assist Customization Availability Flag 5";
BA_ "SignalType" SG_ 1183 ExtdHillStrtAstCustAvlFlg4 "ENM";
BA_ "SignalLongName" SG_ 1183 ExtdHillStrtAstCustAvlFlg4 "Extended Hill Start Assist Customization Availability Flag 4";
BA_ "SignalType" SG_ 1183 ExtdHillStrtAstCustAvlFlg3 "ENM";
BA_ "SignalLongName" SG_ 1183 ExtdHillStrtAstCustAvlFlg3 "Extended Hill Start Assist Customization Availability Flag 3";
BA_ "SignalType" SG_ 1183 ExtdHillStrtAstCustAvlFlg2 "ENM";
BA_ "SignalLongName" SG_ 1183 ExtdHillStrtAstCustAvlFlg2 "Extended Hill Start Assist Customization Availability Flag 2";
BA_ "SignalType" SG_ 1183 ExtdHillStrtAstCustAvlFlg1 "ENM";
BA_ "SignalLongName" SG_ 1183 ExtdHillStrtAstCustAvlFlg1 "Extended Hill Start Assist Customization Availability Flag 1";
BA_ "SignalType" SG_ 1183 PrsnlMdBrkPdlCstmAvFlg2 "ENM";
BA_ "SignalLongName" SG_ 1183 PrsnlMdBrkPdlCstmAvFlg2 "Personal Mode Brake Pedal Customization Availability Flag 2";
BA_ "SignalType" SG_ 1183 PrsnlMdBrkPdlCstmAvFlg1 "ENM";
BA_ "SignalLongName" SG_ 1183 PrsnlMdBrkPdlCstmAvFlg1 "Personal Mode Brake Pedal Customization Availability Flag 1";
BA_ "SignalType" SG_ 1183 PrsnlMdActAeroCstmAvFlg7 "ENM";
BA_ "SignalLongName" SG_ 1183 PrsnlMdActAeroCstmAvFlg7 "Personal Mode Active Aero Customization Availability Flag 7";
BA_ "SignalType" SG_ 1183 PrsnlMdActAeroCstmAvFlg6 "ENM";
BA_ "SignalLongName" SG_ 1183 PrsnlMdActAeroCstmAvFlg6 "Personal Mode Active Aero Customization Availability Flag 6";
BA_ "SignalType" SG_ 1183 PrsnlMdActAeroCstmAvFlg5 "ENM";
BA_ "SignalLongName" SG_ 1183 PrsnlMdActAeroCstmAvFlg5 "Personal Mode Active Aero Customization Availability Flag 5";
BA_ "SignalType" SG_ 1183 PrsnlMdActAeroCstmAvFlg4 "ENM";
BA_ "SignalLongName" SG_ 1183 PrsnlMdActAeroCstmAvFlg4 "Personal Mode Active Aero Customization Availability Flag 4";
BA_ "SignalType" SG_ 1183 PrsnlMdActAeroCstmAvFlg3 "ENM";
BA_ "SignalLongName" SG_ 1183 PrsnlMdActAeroCstmAvFlg3 "Personal Mode Active Aero Customization Availability Flag 3";
BA_ "SignalType" SG_ 1183 PrsnlMdActAeroCstmAvFlg2 "ENM";
BA_ "SignalLongName" SG_ 1183 PrsnlMdActAeroCstmAvFlg2 "Personal Mode Active Aero Customization Availability Flag 2";
BA_ "SignalType" SG_ 1183 PrsnlMdDrvlCstmAvFlg3 "ENM";
BA_ "SignalLongName" SG_ 1183 PrsnlMdDrvlCstmAvFlg3 "Personal Mode Driveline Customization Availability Flag 3";
BA_ "SignalType" SG_ 1183 PrsnlMdDrvlCstmAvFlg2 "ENM";
BA_ "SignalLongName" SG_ 1183 PrsnlMdDrvlCstmAvFlg2 "Personal Mode Driveline Customization Availability Flag 2";
BA_ "SignalType" SG_ 1183 PrsnlMdDrvlCstmAvFlg1 "ENM";
BA_ "SignalLongName" SG_ 1183 PrsnlMdDrvlCstmAvFlg1 "Personal Mode Driveline Customization Availability Flag 1";
BA_ "SignalType" SG_ 1183 PrsnlMdBrkPdlCstmAvFlg7 "ENM";
BA_ "SignalLongName" SG_ 1183 PrsnlMdBrkPdlCstmAvFlg7 "Personal Mode Brake Pedal Customization Availability Flag 7";
BA_ "SignalType" SG_ 1183 PrsnlMdBrkPdlCstmAvFlg6 "ENM";
BA_ "SignalLongName" SG_ 1183 PrsnlMdBrkPdlCstmAvFlg6 "Personal Mode Brake Pedal Customization Availability Flag 6";
BA_ "SignalType" SG_ 1183 PrsnlMdBrkPdlCstmAvFlg5 "ENM";
BA_ "SignalLongName" SG_ 1183 PrsnlMdBrkPdlCstmAvFlg5 "Personal Mode Brake Pedal Customization Availability Flag 5";
BA_ "SignalType" SG_ 1183 PrsnlMdBrkPdlCstmAvFlg4 "ENM";
BA_ "SignalLongName" SG_ 1183 PrsnlMdBrkPdlCstmAvFlg4 "Personal Mode Brake Pedal Customization Availability Flag 4";
BA_ "SignalType" SG_ 1183 PrsnlMdBrkPdlCstmAvFlg3 "ENM";
BA_ "SignalLongName" SG_ 1183 PrsnlMdBrkPdlCstmAvFlg3 "Personal Mode Brake Pedal Customization Availability Flag 3";
BA_ "SignalType" SG_ 1183 PrsnlMdRideHghtCstmAvFlg4 "ENM";
BA_ "SignalLongName" SG_ 1183 PrsnlMdRideHghtCstmAvFlg4 "Personal Mode Ride Height Customization Availability Flag 4";
BA_ "SignalType" SG_ 1183 PrsnlMdRideHghtCstmAvFlg3 "ENM";
BA_ "SignalLongName" SG_ 1183 PrsnlMdRideHghtCstmAvFlg3 "Personal Mode Ride Height Customization Availability Flag 3";
BA_ "SignalType" SG_ 1183 PrsnlMdRideHghtCstmAvFlg2 "ENM";
BA_ "SignalLongName" SG_ 1183 PrsnlMdRideHghtCstmAvFlg2 "Personal Mode Ride Height Customization Availability Flag 2";
BA_ "SignalType" SG_ 1183 PrsnlMdRideHghtCstmAvFlg1 "ENM";
BA_ "SignalLongName" SG_ 1183 PrsnlMdRideHghtCstmAvFlg1 "Personal Mode Ride Height Customization Availability Flag 1";
BA_ "SignalType" SG_ 1183 PrsnlMdDrvlCstmAvFlg7 "ENM";
BA_ "SignalLongName" SG_ 1183 PrsnlMdDrvlCstmAvFlg7 "Personal Mode Driveline Customization Availability Flag 7";
BA_ "SignalType" SG_ 1183 PrsnlMdDrvlCstmAvFlg6 "ENM";
BA_ "SignalLongName" SG_ 1183 PrsnlMdDrvlCstmAvFlg6 "Personal Mode Driveline Customization Availability Flag 6";
BA_ "SignalType" SG_ 1183 PrsnlMdDrvlCstmAvFlg5 "ENM";
BA_ "SignalLongName" SG_ 1183 PrsnlMdDrvlCstmAvFlg5 "Personal Mode Driveline Customization Availability Flag 5";
BA_ "SignalType" SG_ 1183 PrsnlMdDrvlCstmAvFlg4 "ENM";
BA_ "SignalLongName" SG_ 1183 PrsnlMdDrvlCstmAvFlg4 "Personal Mode Driveline Customization Availability Flag 4";
BA_ "SignalType" SG_ 1183 PrsnlMdSndCstmAvFlg5 "ENM";
BA_ "SignalLongName" SG_ 1183 PrsnlMdSndCstmAvFlg5 "Personal Mode Sound Customization Availability Flag 5";
BA_ "SignalType" SG_ 1183 PrsnlMdSndCstmAvFlg4 "ENM";
BA_ "SignalLongName" SG_ 1183 PrsnlMdSndCstmAvFlg4 "Personal Mode Sound Customization Availability Flag 4";
BA_ "SignalType" SG_ 1183 PrsnlMdSndCstmAvFlg3 "ENM";
BA_ "SignalLongName" SG_ 1183 PrsnlMdSndCstmAvFlg3 "Personal Mode Sound Customization Availability Flag 3";
BA_ "SignalType" SG_ 1183 PrsnlMdSndCstmAvFlg2 "ENM";
BA_ "SignalLongName" SG_ 1183 PrsnlMdSndCstmAvFlg2 "Personal Mode Sound Customization Availability Flag 2";
BA_ "SignalType" SG_ 1183 PrsnlMdSndCstmAvFlg1 "ENM";
BA_ "SignalLongName" SG_ 1183 PrsnlMdSndCstmAvFlg1 "Personal Mode Sound Customization Availability Flag 1";
BA_ "SignalType" SG_ 1183 PrsnlMdRideHghtCstmAvFlg7 "ENM";
BA_ "SignalLongName" SG_ 1183 PrsnlMdRideHghtCstmAvFlg7 "Personal Mode Ride Height Customization Availability Flag 7";
BA_ "SignalType" SG_ 1183 PrsnlMdRideHghtCstmAvFlg6 "ENM";
BA_ "SignalLongName" SG_ 1183 PrsnlMdRideHghtCstmAvFlg6 "Personal Mode Ride Height Customization Availability Flag 6";
BA_ "SignalType" SG_ 1183 PrsnlMdRideHghtCstmAvFlg5 "ENM";
BA_ "SignalLongName" SG_ 1183 PrsnlMdRideHghtCstmAvFlg5 "Personal Mode Ride Height Customization Availability Flag 5";
BA_ "SignalType" SG_ 1183 PrsnlMdSpnCstmAvFlg6 "ENM";
BA_ "SignalLongName" SG_ 1183 PrsnlMdSpnCstmAvFlg6 "Personal Mode Suspension Customization Availability Flag 6";
BA_ "SignalType" SG_ 1183 PrsnlMdSpnCstmAvFlg5 "ENM";
BA_ "SignalLongName" SG_ 1183 PrsnlMdSpnCstmAvFlg5 "Personal Mode Suspension Customization Availability Flag 5";
BA_ "SignalType" SG_ 1183 PrsnlMdSpnCstmAvFlg4 "ENM";
BA_ "SignalLongName" SG_ 1183 PrsnlMdSpnCstmAvFlg4 "Personal Mode Suspension Customization Availability Flag 4";
BA_ "SignalType" SG_ 1183 PrsnlMdSpnCstmAvFlg3 "ENM";
BA_ "SignalLongName" SG_ 1183 PrsnlMdSpnCstmAvFlg3 "Personal Mode Suspension Customization Availability Flag 3";
BA_ "SignalType" SG_ 1183 PrsnlMdSpnCstmAvFlg2 "ENM";
BA_ "SignalLongName" SG_ 1183 PrsnlMdSpnCstmAvFlg2 "Personal Mode Suspension Customization Availability Flag 2";
BA_ "SignalType" SG_ 1183 PrsnlMdSpnCstmAvFlg1 "ENM";
BA_ "SignalLongName" SG_ 1183 PrsnlMdSpnCstmAvFlg1 "Personal Mode Suspension Customization Availability Flag 1";
BA_ "SignalType" SG_ 1183 PrsnlMdSndCstmAvFlg7 "ENM";
BA_ "SignalLongName" SG_ 1183 PrsnlMdSndCstmAvFlg7 "Personal Mode Sound Customization Availability Flag 7";
BA_ "SignalType" SG_ 1183 PrsnlMdSndCstmAvFlg6 "ENM";
BA_ "SignalLongName" SG_ 1183 PrsnlMdSndCstmAvFlg6 "Personal Mode Sound Customization Availability Flag 6";
BA_ "SignalType" SG_ 1183 PrsnlMdStrCstmAvFlg7 "ENM";
BA_ "SignalLongName" SG_ 1183 PrsnlMdStrCstmAvFlg7 "Personal Mode Steering Customization Availability Flag 7";
BA_ "SignalType" SG_ 1183 PrsnlMdStrCstmAvFlg6 "ENM";
BA_ "SignalLongName" SG_ 1183 PrsnlMdStrCstmAvFlg6 "Personal Mode Steering Customization Availability Flag 6";
BA_ "SignalType" SG_ 1183 PrsnlMdStrCstmAvFlg5 "ENM";
BA_ "SignalLongName" SG_ 1183 PrsnlMdStrCstmAvFlg5 "Personal Mode Steering Customization Availability Flag 5";
BA_ "SignalType" SG_ 1183 PrsnlMdStrCstmAvFlg4 "ENM";
BA_ "SignalLongName" SG_ 1183 PrsnlMdStrCstmAvFlg4 "Personal Mode Steering Customization Availability Flag 4";
BA_ "SignalType" SG_ 1183 PrsnlMdStrCstmAvFlg3 "ENM";
BA_ "SignalLongName" SG_ 1183 PrsnlMdStrCstmAvFlg3 "Personal Mode Steering Customization Availability Flag 3";
BA_ "SignalType" SG_ 1183 PrsnlMdStrCstmAvFlg2 "ENM";
BA_ "SignalLongName" SG_ 1183 PrsnlMdStrCstmAvFlg2 "Personal Mode Steering Customization Availability Flag 2";
BA_ "SignalType" SG_ 1183 PrsnlMdStrCstmAvFlg1 "ENM";
BA_ "SignalLongName" SG_ 1183 PrsnlMdStrCstmAvFlg1 "Personal Mode Steering Customization Availability Flag 1";
BA_ "SignalType" SG_ 1183 PrsnlMdSpnCstmAvFlg7 "ENM";
BA_ "SignalLongName" SG_ 1183 PrsnlMdSpnCstmAvFlg7 "Personal Mode Suspension Customization Availability Flag 7";
BA_ "SignalLongName" SG_ 1075 DslExhFldTmToIndcmt "Diesel Exhaust Fluid Time To Inducement";
BA_ "SignalType" SG_ 1932 RdHgtWrn3IndReq "ENM";
BA_ "SignalLongName" SG_ 1932 RdHgtWrn3IndReq "Ride Height Warning 3 Indication Request";
BA_ "SignalType" SG_ 1793 SGI_ServStSysIndOn "ENM";
BA_ "SignalLongName" SG_ 1793 SGI_ServStSysIndOn "Seat General Information : Service Seat System Indication On";
BA_ "SignalLongName" SG_ 1793 SGI_PV "Seat General Information : Protection Value";
BA_ "SignalLongName" SG_ 1793 SGI_ARC "Seat General Information : Alive Rolling Count";
BA_ "SignalLongName" SG_ 1498 RRSMP_Type10 "Right Rear Seat Massage Priority : Type 10";
BA_ "SignalLongName" SG_ 1498 RRSMP_Type1 "Right Rear Seat Massage Priority : Type 1";
BA_ "SignalLongName" SG_ 1498 RRSMP_MaxDispVal "Right Rear Seat Massage Priority : Maximum Display Value";
BA_ "SignalLongName" SG_ 1498 RRSMP_Type12 "Right Rear Seat Massage Priority : Type 12";
BA_ "SignalLongName" SG_ 1498 RRSMP_Type11 "Right Rear Seat Massage Priority : Type 11";
BA_ "SignalLongName" SG_ 1498 RRSMP_Type14 "Right Rear Seat Massage Priority : Type 14";
BA_ "SignalLongName" SG_ 1498 RRSMP_Type13 "Right Rear Seat Massage Priority : Type 13";
BA_ "SignalLongName" SG_ 1498 RRSMP_Type2 "Right Rear Seat Massage Priority : Type 2";
BA_ "SignalLongName" SG_ 1498 RRSMP_Type15 "Right Rear Seat Massage Priority : Type 15";
BA_ "SignalLongName" SG_ 1498 RRSMP_Type4 "Right Rear Seat Massage Priority : Type 4";
BA_ "SignalLongName" SG_ 1498 RRSMP_Type3 "Right Rear Seat Massage Priority : Type 3";
BA_ "SignalLongName" SG_ 1498 RRSMP_Type6 "Right Rear Seat Massage Priority : Type 6";
BA_ "SignalLongName" SG_ 1498 RRSMP_Type5 "Right Rear Seat Massage Priority : Type 5";
BA_ "SignalLongName" SG_ 1498 RRSMP_Type8 "Right Rear Seat Massage Priority : Type 8";
BA_ "SignalLongName" SG_ 1498 RRSMP_Type7 "Right Rear Seat Massage Priority : Type 7";
BA_ "SignalLongName" SG_ 1498 RRSMP_Type9 "Right Rear Seat Massage Priority : Type 9";
BA_ "SignalLongName" SG_ 1809 RRSAP_BkCshBlstrInOut "Right Rear Seat Actuator Priority : Back and Cushion Bolster In/Out";
BA_ "SignalLongName" SG_ 1809 RRSAP_BkBlstrInOut "Right Rear Seat Actuator Priority : Back Bolster In/Out";
BA_ "SignalLongName" SG_ 1809 RRSAP_CshLgthAdjFdRr "Right Rear Seat Actuator Priority : Cushion Length Adjustment Forward/Rearward";
BA_ "SignalLongName" SG_ 1809 RRSAP_CshBlstrInOut "Right Rear Seat Actuator Priority : Cushion Bolster In/Out";
BA_ "SignalLongName" SG_ 1809 RRSAP_HdrstTltFwdRr "Right Rear Seat Actuator Priority : Headrest Tilt Forward/Rearward";
BA_ "SignalLongName" SG_ 1809 RRSAP_HdrstFwdRrwd "Right Rear Seat Actuator Priority : Headrest Forward/Rearward";
BA_ "SignalLongName" SG_ 1809 RRSAP_HdrstUpDnFdRr "Right Rear Seat Actuator Priority : Headrest Up/Down and Forward/Rearward";
BA_ "SignalLongName" SG_ 1809 RRSAP_HdrstUpDn "Right Rear Seat Actuator Priority : Headrest Up/Down";
BA_ "SignalLongName" SG_ 1809 RRSAP_LmbrFwdRr "Right Rear Seat Actuator Priority : Lumbar Forward/Rearward";
BA_ "SignalLongName" SG_ 1809 RRSAP_HdrstWngsInOut "Right Rear Seat Actuator Priority : Headrest Wings Inward/Outward";
BA_ "SignalLongName" SG_ 1809 RRSAP_LmbrUpDwn "Right Rear Seat Actuator Priority : Lumbar Up/Down";
BA_ "SignalLongName" SG_ 1809 RRSAP_LmbrUpDnFdRr "Right Rear Seat Actuator Priority : Lumbar Up/Down and Forward/Rearward";
BA_ "SignalLongName" SG_ 1809 RRSAP_UprShldrFwdRr "Right Rear Seat Actuator Priority : Upper Shoulder Forward/Rearward";
BA_ "SignalLongName" SG_ 1809 RRSAP_Massg "Right Rear Seat Actuator Priority : Massage";
BA_ "SignalType" SG_ 1809 StLckoutRRCtlCurrSet "ENM";
BA_ "SignalLongName" SG_ 1809 StLckoutRRCtlCurrSet "Seat Lockout Right Rear\??Control Current Setting";
BA_ "SignalType" SG_ 1809 StLckoutRRVirtCtlAval "ENM";
BA_ "SignalLongName" SG_ 1809 StLckoutRRVirtCtlAval "Seat Lockout Right Rear Virtual Control Available";
BA_ "SignalType" SG_ 1809 StMemRRVirtCtlStorAllwd "ENM";
BA_ "SignalLongName" SG_ 1809 StMemRRVirtCtlStorAllwd "Seat Memory Right Rear Virtual Control Store Allowed";
BA_ "SignalType" SG_ 1809 StMemRRVirtCtlRclAllwd "ENM";
BA_ "SignalLongName" SG_ 1809 StMemRRVirtCtlRclAllwd "Seat Memory Right Rear Virtual Control Recall Allowed";
BA_ "SignalLongName" SG_ 1499 LRSMP_Type10 "Left Rear Seat Massage Priority : Type 10";
BA_ "SignalLongName" SG_ 1499 LRSMP_Type1 "Left Rear Seat Massage Priority : Type 1";
BA_ "SignalLongName" SG_ 1499 LRSMP_MaxDispVal "Left Rear Seat Massage Priority : Maximum Display Value";
BA_ "SignalLongName" SG_ 1499 LRSMP_Type12 "Left Rear Seat Massage Priority : Type 12";
BA_ "SignalLongName" SG_ 1499 LRSMP_Type11 "Left Rear Seat Massage Priority : Type 11";
BA_ "SignalLongName" SG_ 1499 LRSMP_Type14 "Left Rear Seat Massage Priority : Type 14";
BA_ "SignalLongName" SG_ 1499 LRSMP_Type13 "Left Rear Seat Massage Priority : Type 13";
BA_ "SignalLongName" SG_ 1499 LRSMP_Type2 "Left Rear Seat Massage Priority : Type 2";
BA_ "SignalLongName" SG_ 1499 LRSMP_Type15 "Left Rear Seat Massage Priority : Type 15";
BA_ "SignalLongName" SG_ 1499 LRSMP_Type4 "Left Rear Seat Massage Priority : Type 4";
BA_ "SignalLongName" SG_ 1499 LRSMP_Type3 "Left Rear Seat Massage Priority : Type 3";
BA_ "SignalLongName" SG_ 1499 LRSMP_Type6 "Left Rear Seat Massage Priority : Type 6";
BA_ "SignalLongName" SG_ 1499 LRSMP_Type5 "Left Rear Seat Massage Priority : Type 5";
BA_ "SignalLongName" SG_ 1499 LRSMP_Type8 "Left Rear Seat Massage Priority : Type 8";
BA_ "SignalLongName" SG_ 1499 LRSMP_Type7 "Left Rear Seat Massage Priority : Type 7";
BA_ "SignalLongName" SG_ 1499 LRSMP_Type9 "Left Rear Seat Massage Priority : Type 9";
BA_ "SignalLongName" SG_ 1256 LRSAP_BkCshBlstrInOut "Left Rear Seat Actuator Priority : Back and Cushion Bolster In/Out";
BA_ "SignalLongName" SG_ 1256 LRSAP_BkBlstrInOut "Left Rear Seat Actuator Priority : Back Bolster In/Out";
BA_ "SignalLongName" SG_ 1256 LRSAP_CshLgthAdjFdRr "Left Rear Seat Actuator Priority : Cushion Length Adjustment Forward/Rearward";
BA_ "SignalLongName" SG_ 1256 LRSAP_CshBlstrInOut "Left Rear Seat Actuator Priority : Cushion Bolster In/Out";
BA_ "SignalLongName" SG_ 1256 LRSAP_HdrstTltFwdRr "Left Rear Seat Actuator Priority : Headrest Tilt Forward/Rearward";
BA_ "SignalLongName" SG_ 1256 LRSAP_HdrstFwdRrwd "Left Rear Seat Actuator Priority : Headrest Forward/Rearward";
BA_ "SignalLongName" SG_ 1256 LRSAP_HdrstUpDnFdRr "Left Rear Seat Actuator Priority : Headrest Up/Down and Forward/Rearward";
BA_ "SignalLongName" SG_ 1256 LRSAP_HdrstUpDn "Left Rear Seat Actuator Priority : Headrest Up/Down";
BA_ "SignalLongName" SG_ 1256 LRSAP_LmbrFwdRr "Left Rear Seat Actuator Priority : Lumbar Forward/Rearward";
BA_ "SignalLongName" SG_ 1256 LRSAP_HdrstWngsInOut "Left Rear Seat Actuator Priority : Headrest Wings Inward/Outward";
BA_ "SignalLongName" SG_ 1256 LRSAP_LmbrUpDwn "Left Rear Seat Actuator Priority : Lumbar Up/Down";
BA_ "SignalLongName" SG_ 1256 LRSAP_LmbrUpDnFdRr "Left Rear Seat Actuator Priority : Lumbar Up/Down and Forward/Rearward";
BA_ "SignalLongName" SG_ 1256 LRSAP_UprShldrFwdRr "Left Rear Seat Actuator Priority : Upper Shoulder Forward/Rearward";
BA_ "SignalLongName" SG_ 1256 LRSAP_Massg "Left Rear Seat Actuator Priority : Massage";
BA_ "SignalType" SG_ 1256 StLckoutLRCtlCurrSet "ENM";
BA_ "SignalLongName" SG_ 1256 StLckoutLRCtlCurrSet "Seat Lockout Left Rear\??Control Current Setting";
BA_ "SignalType" SG_ 1256 StLckoutLRVirtCtlAval "ENM";
BA_ "SignalLongName" SG_ 1256 StLckoutLRVirtCtlAval "Seat Lockout Left Rear Virtual Control Available";
BA_ "SignalType" SG_ 1256 StMemLRVirtCtlStorAllwd "ENM";
BA_ "SignalLongName" SG_ 1256 StMemLRVirtCtlStorAllwd "Seat Memory Left Rear Virtual Control Store Allowed";
BA_ "SignalType" SG_ 1256 StMemLRVirtCtlRclAllwd "ENM";
BA_ "SignalLongName" SG_ 1256 StMemLRVirtCtlRclAllwd "Seat Memory Left Rear Virtual Control Recall Allowed";
BA_ "SignalLongName" SG_ 1466 LFSAP_BkCshBlstrInOut "Left Front Seat Actuator Priority : Back and Cushion Bolster In/Out";
BA_ "SignalLongName" SG_ 1466 LFSAP_BkBlstrInOut "Left Front Seat Actuator Priority : Back Bolster In/Out";
BA_ "SignalLongName" SG_ 1466 LFSAP_CshLgthAdjFdRr "Left Front Seat Actuator Priority : Cushion Length Adjustment Forward/Rearward";
BA_ "SignalLongName" SG_ 1466 LFSAP_CshBlstrInOut "Left Front Seat Actuator Priority : Cushion Bolster In/Out";
BA_ "SignalLongName" SG_ 1466 LFSAP_HdrstTltFwdRr "Left Front Seat Actuator Priority : Headrest Tilt Forward/Rearward";
BA_ "SignalLongName" SG_ 1466 LFSAP_HdrstFwdRrwd "Left Front Seat Actuator Priority : Headrest Forward/Rearward";
BA_ "SignalLongName" SG_ 1466 LFSAP_HdrstUpDnFdRr "Left Front Seat Actuator Priority : Headrest Up/Down and Forward/Rearward";
BA_ "SignalLongName" SG_ 1466 LFSAP_HdrstUpDn "Left Front Seat Actuator Priority : Headrest Up/Down";
BA_ "SignalLongName" SG_ 1466 LFSAP_LmbrFwdRr "Left Front Seat Actuator Priority : Lumbar Forward/Rearward";
BA_ "SignalLongName" SG_ 1466 LFSAP_HdrstWngsInOut "Left Front Seat Actuator Priority : Headrest Wings Inward/Outward";
BA_ "SignalLongName" SG_ 1466 LFSAP_LmbrUpDwn "Left Front Seat Actuator Priority : Lumbar Up/Down";
BA_ "SignalLongName" SG_ 1466 LFSAP_LmbrUpDnFdRr "Left Front Seat Actuator Priority : Lumbar Up/Down and Forward/Rearward";
BA_ "SignalLongName" SG_ 1466 LFSAP_UprShldrFwdRr "Left Front Seat Actuator Priority : Upper Shoulder Forward/Rearward";
BA_ "SignalLongName" SG_ 1466 LFSAP_Massg "Left Front Seat Actuator Priority : Massage";
BA_ "SignalLongName" SG_ 1255 RFSAP_BkCshBlstrInOut "Right Front Seat Actuator Priority : Back and Cushion Bolster In/Out";
BA_ "SignalLongName" SG_ 1255 RFSAP_BkBlstrInOut "Right Front Seat Actuator Priority : Back Bolster In/Out";
BA_ "SignalLongName" SG_ 1255 RFSAP_CshLgthAdjFdRr "Right Front Seat Actuator Priority : Cushion Length Adjustment Forward/Rearward";
BA_ "SignalLongName" SG_ 1255 RFSAP_CshBlstrInOut "Right Front Seat Actuator Priority : Cushion Bolster In/Out";
BA_ "SignalLongName" SG_ 1255 RFSAP_HdrstTltFwdRr "Right Front Seat Actuator Priority : Headrest Tilt Forward/Rearward";
BA_ "SignalLongName" SG_ 1255 RFSAP_HdrstFwdRrwd "Right Front Seat Actuator Priority : Headrest Forward/Rearward";
BA_ "SignalLongName" SG_ 1255 RFSAP_HdrstUpDnFdRr "Right Front Seat Actuator Priority : Headrest Up/Down and Forward/Rearward";
BA_ "SignalLongName" SG_ 1255 RFSAP_HdrstUpDn "Right Front Seat Actuator Priority : Headrest Up/Down";
BA_ "SignalLongName" SG_ 1255 RFSAP_LmbrFwdRr "Right Front Seat Actuator Priority : Lumbar Forward/Rearward";
BA_ "SignalLongName" SG_ 1255 RFSAP_HdrstWngsInOut "Right Front Seat Actuator Priority : Headrest Wings Inward/Outward";
BA_ "SignalLongName" SG_ 1255 RFSAP_LmbrUpDwn "Right Front Seat Actuator Priority : Lumbar Up/Down";
BA_ "SignalLongName" SG_ 1255 RFSAP_LmbrUpDnFdRr "Right Front Seat Actuator Priority : Lumbar Up/Down and Forward/Rearward";
BA_ "SignalLongName" SG_ 1255 RFSAP_UprShldrFwdRr "Right Front Seat Actuator Priority : Upper Shoulder Forward/Rearward";
BA_ "SignalLongName" SG_ 1255 RFSAP_Massg "Right Front Seat Actuator Priority : Massage";
BA_ "SignalLongName" SG_ 1501 LFSMP_Type10 "Left Front Seat Massage Priority : Type 10";
BA_ "SignalLongName" SG_ 1501 LFSMP_Type1 "Left Front Seat Massage Priority : Type 1";
BA_ "SignalLongName" SG_ 1501 LFSMP_MaxDispVal "Left Front Seat Massage Priority : Maximum Display Value";
BA_ "SignalLongName" SG_ 1501 LFSMP_Type12 "Left Front Seat Massage Priority : Type 12";
BA_ "SignalLongName" SG_ 1501 LFSMP_Type11 "Left Front Seat Massage Priority : Type 11";
BA_ "SignalLongName" SG_ 1501 LFSMP_Type14 "Left Front Seat Massage Priority : Type 14";
BA_ "SignalLongName" SG_ 1501 LFSMP_Type13 "Left Front Seat Massage Priority : Type 13";
BA_ "SignalLongName" SG_ 1501 LFSMP_Type2 "Left Front Seat Massage Priority : Type 2";
BA_ "SignalLongName" SG_ 1501 LFSMP_Type15 "Left Front Seat Massage Priority : Type 15";
BA_ "SignalLongName" SG_ 1501 LFSMP_Type4 "Left Front Seat Massage Priority : Type 4";
BA_ "SignalLongName" SG_ 1501 LFSMP_Type3 "Left Front Seat Massage Priority : Type 3";
BA_ "SignalLongName" SG_ 1501 LFSMP_Type6 "Left Front Seat Massage Priority : Type 6";
BA_ "SignalLongName" SG_ 1501 LFSMP_Type5 "Left Front Seat Massage Priority : Type 5";
BA_ "SignalLongName" SG_ 1501 LFSMP_Type8 "Left Front Seat Massage Priority : Type 8";
BA_ "SignalLongName" SG_ 1501 LFSMP_Type7 "Left Front Seat Massage Priority : Type 7";
BA_ "SignalLongName" SG_ 1501 LFSMP_Type9 "Left Front Seat Massage Priority : Type 9";
BA_ "SignalLongName" SG_ 1502 RFSMP_Type10 "Right Front Seat Massage Priority : Type 10";
BA_ "SignalLongName" SG_ 1502 RFSMP_Type1 "Right Front Seat Massage Priority : Type 1";
BA_ "SignalLongName" SG_ 1502 RFSMP_MaxDispVal "Right Front Seat Massage Priority : Maximum Display Value";
BA_ "SignalLongName" SG_ 1502 RFSMP_Type12 "Right Front Seat Massage Priority : Type 12";
BA_ "SignalLongName" SG_ 1502 RFSMP_Type11 "Right Front Seat Massage Priority : Type 11";
BA_ "SignalLongName" SG_ 1502 RFSMP_Type14 "Right Front Seat Massage Priority : Type 14";
BA_ "SignalLongName" SG_ 1502 RFSMP_Type13 "Right Front Seat Massage Priority : Type 13";
BA_ "SignalLongName" SG_ 1502 RFSMP_Type2 "Right Front Seat Massage Priority : Type 2";
BA_ "SignalLongName" SG_ 1502 RFSMP_Type15 "Right Front Seat Massage Priority : Type 15";
BA_ "SignalLongName" SG_ 1502 RFSMP_Type4 "Right Front Seat Massage Priority : Type 4";
BA_ "SignalLongName" SG_ 1502 RFSMP_Type3 "Right Front Seat Massage Priority : Type 3";
BA_ "SignalLongName" SG_ 1502 RFSMP_Type6 "Right Front Seat Massage Priority : Type 6";
BA_ "SignalLongName" SG_ 1502 RFSMP_Type5 "Right Front Seat Massage Priority : Type 5";
BA_ "SignalLongName" SG_ 1502 RFSMP_Type8 "Right Front Seat Massage Priority : Type 8";
BA_ "SignalLongName" SG_ 1502 RFSMP_Type7 "Right Front Seat Massage Priority : Type 7";
BA_ "SignalLongName" SG_ 1502 RFSMP_Type9 "Right Front Seat Massage Priority : Type 9";
BA_ "SignalType" SG_ 1513 RrClsrAjrStat "ENM";
BA_ "SignalLongName" SG_ 1513 RrClsrAjrStat "Rear Closure Ajar Status";
BA_ "SignalType" SG_ 1513 RrClsrAjrStat_Inv "ENM";
BA_ "SignalLongName" SG_ 1513 RrClsrAjrStat_Inv "Rear Closure Ajar Status Invalid";
BA_ "SignalType" SG_ 2000 StBkSdBolsLFVirtCtlAval "ENM";
BA_ "SignalLongName" SG_ 2000 StBkSdBolsLFVirtCtlAval "Seat Left Front Virtual Control Available Information : Seat Back Side Bolster Left Front Virtual Control Available";
BA_ "SignalType" SG_ 2000 StBkLumbVertLFVirtCtlAval "ENM";
BA_ "SignalLongName" SG_ 2000 StBkLumbVertLFVirtCtlAval "Seat Left Front Virtual Control Available Information : Seat Back Lumbar Vertical Left Front Virtual Control Available";
BA_ "SignalType" SG_ 2000 StBkLumbHrztlLFVirtCtlAval "ENM";
BA_ "SignalLongName" SG_ 2000 StBkLumbHrztlLFVirtCtlAval "Seat Left Front Virtual Control Available Information : Seat Back Lumbar Horizontal Left Front Virtual Control Available";
BA_ "SignalType" SG_ 2000 StBkHrztlLFCtlFrmRrVirtCtlAval "ENM";
BA_ "SignalLongName" SG_ 2000 StBkHrztlLFCtlFrmRrVirtCtlAval "Seat Left Front Virtual Control Available Information : Seat Back Horizontal Left Front Control From Rear Virtual Control Available";
BA_ "SignalType" SG_ 2000 StBkHrztlLFCtlFrmFrtVirtCtlAval "ENM";
BA_ "SignalLongName" SG_ 2000 StBkHrztlLFCtlFrmFrtVirtCtlAval "Seat Left Front Virtual Control Available Information : Seat Back Horizontal Left Front Control From Front Virtual Control Available";
BA_ "SignalLongName" SG_ 2000 StMasgIntstyLFVirtCtlMaxLvl "Seat Left Front Virtual Control Available Information : Seat Massage Intensity Left Front Virtual Control Maximum Level";
BA_ "SignalType" SG_ 2000 StHdrstVertLFVirtCtlAval "ENM";
BA_ "SignalLongName" SG_ 2000 StHdrstVertLFVirtCtlAval "Seat Left Front Virtual Control Available Information : Seat Headrest Vertical Left Front Virtual Control Available";
BA_ "SignalType" SG_ 2000 StHdrstHrztlLFVirtCtlAval "ENM";
BA_ "SignalLongName" SG_ 2000 StHdrstHrztlLFVirtCtlAval "Seat Left Front Virtual Control Available Information : Seat Headrest Horizontal Left Front Virtual Control Available";
BA_ "SignalType" SG_ 2000 StCushSdBolsLFVirtCtlAval "ENM";
BA_ "SignalLongName" SG_ 2000 StCushSdBolsLFVirtCtlAval "Seat Left Front Virtual Control Available Information : Seat Cushion Side Bolster Left Front Virtual Control Available";
BA_ "SignalType" SG_ 2000 StCushRrVertLFVirtCtlAval "ENM";
BA_ "SignalLongName" SG_ 2000 StCushRrVertLFVirtCtlAval "Seat Left Front Virtual Control Available Information : Seat Cushion Rear Vertical Left Front Virtual Control Available";
BA_ "SignalType" SG_ 2000 StCushLgthHrztlLFVirtCtlAval "ENM";
BA_ "SignalLongName" SG_ 2000 StCushLgthHrztlLFVirtCtlAval "Seat Left Front Virtual Control Available Information : Seat Cushion Length Horizontal Left Front Virtual Control Available";
BA_ "SignalType" SG_ 2000 StCushHrztlLFCtlFrmRrVirtCtlAvl "ENM";
BA_ "SignalLongName" SG_ 2000 StCushHrztlLFCtlFrmRrVirtCtlAvl "Seat Left Front Virtual Control Available Information : Seat Cushion Horizontal Left Front Control From Rear Virtual Control Available";
BA_ "SignalType" SG_ 2000 StCushHrztlLFCtlFrmFrVirtCtlAvl "ENM";
BA_ "SignalLongName" SG_ 2000 StCushHrztlLFCtlFrmFrVirtCtlAvl "Seat Left Front Virtual Control Available Information : Seat Cushion Horizontal Left Front Control From Front Virtual Control Available";
BA_ "SignalType" SG_ 2000 StCushFrtVertLFVirtCtlAval "ENM";
BA_ "SignalLongName" SG_ 2000 StCushFrtVertLFVirtCtlAval "Seat Left Front Virtual Control Available Information : Seat Cushion Front Vertical Left Front Virtual Control Available";
BA_ "SignalType" SG_ 2000 StMasgTyp2LFVirtCtlAval "ENM";
BA_ "SignalLongName" SG_ 2000 StMasgTyp2LFVirtCtlAval "Seat Left Front Virtual Control Available Information : Seat Massage Type 2 Left Front Virtual Control Available";
BA_ "SignalType" SG_ 2000 StMasgTyp1LFVirtCtlAval "ENM";
BA_ "SignalLongName" SG_ 2000 StMasgTyp1LFVirtCtlAval "Seat Left Front Virtual Control Available Information : Seat Massage Type 1 Left Front Virtual Control Available";
BA_ "SignalType" SG_ 2000 StMasgTyp15LFVirtCtlAval "ENM";
BA_ "SignalLongName" SG_ 2000 StMasgTyp15LFVirtCtlAval "Seat Left Front Virtual Control Available Information : Seat Massage Type 15 Left Front Virtual Control Available";
BA_ "SignalType" SG_ 2000 StMasgTyp14LFVirtCtlAval "ENM";
BA_ "SignalLongName" SG_ 2000 StMasgTyp14LFVirtCtlAval "Seat Left Front Virtual Control Available Information : Seat Massage Type 14 Left Front Virtual Control Available";
BA_ "SignalType" SG_ 2000 StMasgTyp13LFVirtCtlAval "ENM";
BA_ "SignalLongName" SG_ 2000 StMasgTyp13LFVirtCtlAval "Seat Left Front Virtual Control Available Information : Seat Massage Type 13 Left Front Virtual Control Available";
BA_ "SignalType" SG_ 2000 StMasgTyp12LFVirtCtlAval "ENM";
BA_ "SignalLongName" SG_ 2000 StMasgTyp12LFVirtCtlAval "Seat Left Front Virtual Control Available Information : Seat Massage Type 12 Left Front Virtual Control Available";
BA_ "SignalType" SG_ 2000 StMasgTyp11LFVirtCtlAval "ENM";
BA_ "SignalLongName" SG_ 2000 StMasgTyp11LFVirtCtlAval "Seat Left Front Virtual Control Available Information : Seat Massage Type 11 Left Front Virtual Control Available";
BA_ "SignalType" SG_ 2000 StMasgTyp10LFVirtCtlAval "ENM";
BA_ "SignalLongName" SG_ 2000 StMasgTyp10LFVirtCtlAval "Seat Left Front Virtual Control Available Information : Seat Massage Type 10 Left Front Virtual Control Available";
BA_ "SignalType" SG_ 2000 StUpprShldrHrztlLFVirtCtlAval "ENM";
BA_ "SignalLongName" SG_ 2000 StUpprShldrHrztlLFVirtCtlAval "Seat Left Front Virtual Control Available Information : Seat Upper Shoulder Horizontal Left Front Virtual Control Available";
BA_ "SignalType" SG_ 2000 StMasgTyp9LFVirtCtlAval "ENM";
BA_ "SignalLongName" SG_ 2000 StMasgTyp9LFVirtCtlAval "Seat Left Front Virtual Control Available Information : Seat Massage Type 9 Left Front Virtual Control Available";
BA_ "SignalType" SG_ 2000 StMasgTyp8LFVirtCtlAval "ENM";
BA_ "SignalLongName" SG_ 2000 StMasgTyp8LFVirtCtlAval "Seat Left Front Virtual Control Available Information : Seat Massage Type 8 Left Front Virtual Control Available";
BA_ "SignalType" SG_ 2000 StMasgTyp7LFVirtCtlAval "ENM";
BA_ "SignalLongName" SG_ 2000 StMasgTyp7LFVirtCtlAval "Seat Left Front Virtual Control Available Information : Seat Massage Type 7 Left Front Virtual Control Available";
BA_ "SignalType" SG_ 2000 StMasgTyp6LFVirtCtlAval "ENM";
BA_ "SignalLongName" SG_ 2000 StMasgTyp6LFVirtCtlAval "Seat Left Front Virtual Control Available Information : Seat Massage Type 6 Left Front Virtual Control Available";
BA_ "SignalType" SG_ 2000 StMasgTyp5LFVirtCtlAval "ENM";
BA_ "SignalLongName" SG_ 2000 StMasgTyp5LFVirtCtlAval "Seat Left Front Virtual Control Available Information : Seat Massage Type 5 Left Front Virtual Control Available";
BA_ "SignalType" SG_ 2000 StMasgTyp4LFVirtCtlAval "ENM";
BA_ "SignalLongName" SG_ 2000 StMasgTyp4LFVirtCtlAval "Seat Left Front Virtual Control Available Information : Seat Massage Type 4 Left Front Virtual Control Available";
BA_ "SignalType" SG_ 2000 StMasgTyp3LFVirtCtlAval "ENM";
BA_ "SignalLongName" SG_ 2000 StMasgTyp3LFVirtCtlAval "Seat Left Front Virtual Control Available Information : Seat Massage Type 3 Left Front Virtual Control Available";
BA_ "SignalType" SG_ 2000 StMemLFVirtCtlNumofMemPstnsAval "ENM";
BA_ "SignalLongName" SG_ 2000 StMemLFVirtCtlNumofMemPstnsAval "Seat Memory Left Front Virtual Control Number of Memory Positions Available";
BA_ "SignalType" SG_ 2000 StMemLFVirtCtlNumofExtPstnsAval "ENM";
BA_ "SignalLongName" SG_ 2000 StMemLFVirtCtlNumofExtPstnsAval "Seat Memory Left Front Virtual Control Number of Exit Positions Available";
BA_ "SignalType" SG_ 2000 StBkHrztlLFCtlFrmFrtVirtCtlAlwd "ENM";
BA_ "SignalLongName" SG_ 2000 StBkHrztlLFCtlFrmFrtVirtCtlAlwd "Seat Left Front Virtual Control Allowed Information : Seat Back Horizontal Left Front Control From Front Virtual Control Allowed";
BA_ "SignalType" SG_ 2000 StMasgIntstyLFLstKnwnSet "ENM";
BA_ "SignalLongName" SG_ 2000 StMasgIntstyLFLstKnwnSet "Seat Left Front Massage Setting Information : Seat Massage Intensity Left Front Last Known Setting";
BA_ "SignalType" SG_ 2000 StMasgTypLFLstKnwnSet "ENM";
BA_ "SignalLongName" SG_ 2000 StMasgTypLFLstKnwnSet "Seat Left Front Massage Setting Information : Seat Massage Type Left Front Last Known Setting";
BA_ "SignalType" SG_ 2000 StCushLgthHrztlLFVirtCtlAllwd "ENM";
BA_ "SignalLongName" SG_ 2000 StCushLgthHrztlLFVirtCtlAllwd "Seat Left Front Virtual Control Allowed Information : Seat Cushion Length Horizontal Left Front Virtual Control Allowed";
BA_ "SignalType" SG_ 2000 StCushHrztlLFCtlFrmRrVirCtlAlwd "ENM";
BA_ "SignalLongName" SG_ 2000 StCushHrztlLFCtlFrmRrVirCtlAlwd "Seat Left Front Virtual Control Allowed Information : Seat Cushion Horizontal Left Front Control From Rear Virtual Control Allowed";
BA_ "SignalType" SG_ 2000 StCushHrztlLFCtlFrmFrVirCtlAlwd "ENM";
BA_ "SignalLongName" SG_ 2000 StCushHrztlLFCtlFrmFrVirCtlAlwd "Seat Left Front Virtual Control Allowed Information : Seat Cushion Horizontal Left Front Control From Front Virtual Control Allowed";
BA_ "SignalType" SG_ 2000 StCushFrtVertLFVirtCtlAllwd "ENM";
BA_ "SignalLongName" SG_ 2000 StCushFrtVertLFVirtCtlAllwd "Seat Left Front Virtual Control Allowed Information : Seat Cushion Front Vertical Left Front Virtual Control Allowed";
BA_ "SignalType" SG_ 2000 StBkSdBolsLFVirtCtlAllwd "ENM";
BA_ "SignalLongName" SG_ 2000 StBkSdBolsLFVirtCtlAllwd "Seat Left Front Virtual Control Allowed Information : Seat Back Side Bolster Left Front Virtual Control Allowed";
BA_ "SignalType" SG_ 2000 StBkLumbVertLFVirtCtlAllwd "ENM";
BA_ "SignalLongName" SG_ 2000 StBkLumbVertLFVirtCtlAllwd "Seat Left Front Virtual Control Allowed Information : Seat Back Lumbar Vertical Left Front Virtual Control Allowed";
BA_ "SignalType" SG_ 2000 StBkLumbHrztlLFVirtCtlAllwd "ENM";
BA_ "SignalLongName" SG_ 2000 StBkLumbHrztlLFVirtCtlAllwd "Seat Left Front Virtual Control Allowed Information : Seat Back Lumbar Horizontal Left Front Virtual Control Allowed";
BA_ "SignalType" SG_ 2000 StBkHrztlLFCtlFrmRrVirtCtlAllwd "ENM";
BA_ "SignalLongName" SG_ 2000 StBkHrztlLFCtlFrmRrVirtCtlAllwd "Seat Left Front Virtual Control Allowed Information : Seat Back Horizontal Left Front Control From Rear Virtual Control Allowed";
BA_ "SignalType" SG_ 2000 StMemLFVirtCtlStorAllwd "ENM";
BA_ "SignalLongName" SG_ 2000 StMemLFVirtCtlStorAllwd "Seat Memory Left Front Virtual Control Store Allowed";
BA_ "SignalType" SG_ 2000 StMemLFVirtCtlRclAllwd "ENM";
BA_ "SignalLongName" SG_ 2000 StMemLFVirtCtlRclAllwd "Seat Memory Left Front Virtual Control Recall Allowed";
BA_ "SignalType" SG_ 2000 StUpprShldrHrztlLFVirtCtlAllwd "ENM";
BA_ "SignalLongName" SG_ 2000 StUpprShldrHrztlLFVirtCtlAllwd "Seat Left Front Virtual Control Allowed Information : Seat Upper Shoulder Horizontal Left Front Virtual Control Allowed";
BA_ "SignalType" SG_ 2000 StMasgLFVirtCtlAllwd "ENM";
BA_ "SignalLongName" SG_ 2000 StMasgLFVirtCtlAllwd "Seat Left Front Virtual Control Allowed Information : Seat Massage Left Front Virtual Control Allowed";
BA_ "SignalType" SG_ 2000 StHdrstVertLFVirtCtlAllwd "ENM";
BA_ "SignalLongName" SG_ 2000 StHdrstVertLFVirtCtlAllwd "Seat Left Front Virtual Control Allowed Information : Seat Headrest Vertical Left Front Virtual Control Allowed";
BA_ "SignalType" SG_ 2000 StHdrstHrztlLFVirtCtlAllwd "ENM";
BA_ "SignalLongName" SG_ 2000 StHdrstHrztlLFVirtCtlAllwd "Seat Left Front Virtual Control Allowed Information : Seat Headrest Horizontal Left Front Virtual Control Allowed";
BA_ "SignalType" SG_ 2000 StCushSdBolsLFVirtCtlAllwd "ENM";
BA_ "SignalLongName" SG_ 2000 StCushSdBolsLFVirtCtlAllwd "Seat Left Front Virtual Control Allowed Information : Seat Cushion Side Bolster Left Front Virtual Control Allowed";
BA_ "SignalType" SG_ 2000 StCushRrVertLFVirtCtlAllwd "ENM";
BA_ "SignalLongName" SG_ 2000 StCushRrVertLFVirtCtlAllwd "Seat Left Front Virtual Control Allowed Information : Seat Cushion Rear Vertical Left Front Virtual Control Allowed";
BA_ "SignalType" SG_ 1985 DMBlkhdDrAutoClsTmCstSetAval "ENM";
BA_ "SignalLongName" SG_ 1985 DMBlkhdDrAutoClsTmCstSetAval "Delivery Mode Bulkhead Door Auto Close Time Customization Setting Available";
BA_ "SignalType" SG_ 1985 DMBlkhdDrAutoClsTmCstAvlFlg7 "ENM";
BA_ "SignalLongName" SG_ 1985 DMBlkhdDrAutoClsTmCstAvlFlg7 "Delivery Mode Bulkhead Door Auto Close Time Customization Availability Flag 7";
BA_ "SignalType" SG_ 1985 DMBlkhdDrAutoClsTmCstAvlFlg6 "ENM";
BA_ "SignalLongName" SG_ 1985 DMBlkhdDrAutoClsTmCstAvlFlg6 "Delivery Mode Bulkhead Door Auto Close Time Customization Availability Flag 6";
BA_ "SignalType" SG_ 1985 DMBlkhdDrAutoClsTmCstAvlFlg5 "ENM";
BA_ "SignalLongName" SG_ 1985 DMBlkhdDrAutoClsTmCstAvlFlg5 "Delivery Mode Bulkhead Door Auto Close Time Customization Availability Flag 5";
BA_ "SignalType" SG_ 1985 DMBlkhdDrAutoClsTmCstAvlFlg4 "ENM";
BA_ "SignalLongName" SG_ 1985 DMBlkhdDrAutoClsTmCstAvlFlg4 "Delivery Mode Bulkhead Door Auto Close Time Customization Availability Flag 4";
BA_ "SignalType" SG_ 1985 DMBlkhdDrAutoClsTmCstAvlFlg3 "ENM";
BA_ "SignalLongName" SG_ 1985 DMBlkhdDrAutoClsTmCstAvlFlg3 "Delivery Mode Bulkhead Door Auto Close Time Customization Availability Flag 3";
BA_ "SignalType" SG_ 1985 DMBlkhdDrAutoClsTmCstAvlFlg2 "ENM";
BA_ "SignalLongName" SG_ 1985 DMBlkhdDrAutoClsTmCstAvlFlg2 "Delivery Mode Bulkhead Door Auto Close Time Customization Availability Flag 2";
BA_ "SignalType" SG_ 1985 DMBlkhdDrAutoClsTmCstAvlFlg1 "ENM";
BA_ "SignalLongName" SG_ 1985 DMBlkhdDrAutoClsTmCstAvlFlg1 "Delivery Mode Bulkhead Door Auto Close Time Customization Availability Flag 1";
BA_ "SignalType" SG_ 1985 DMBlkhdDrOpnVehOffCstSetAval "ENM";
BA_ "SignalLongName" SG_ 1985 DMBlkhdDrOpnVehOffCstSetAval "Delivery Mode Bulkhead Door Open on Vehicle Off Customization Setting Available";
BA_ "SignalType" SG_ 1985 DMBlkhdDrOpnVehOffCstAvlFlg7 "ENM";
BA_ "SignalLongName" SG_ 1985 DMBlkhdDrOpnVehOffCstAvlFlg7 "Delivery Mode Bulkhead Door Open on Vehicle Off Customization Availability Flag 7";
BA_ "SignalType" SG_ 1985 DMBlkhdDrOpnVehOffCstAvlFlg6 "ENM";
BA_ "SignalLongName" SG_ 1985 DMBlkhdDrOpnVehOffCstAvlFlg6 "Delivery Mode Bulkhead Door Open on Vehicle Off Customization Availability Flag 6";
BA_ "SignalType" SG_ 1985 DMBlkhdDrOpnVehOffCstAvlFlg5 "ENM";
BA_ "SignalLongName" SG_ 1985 DMBlkhdDrOpnVehOffCstAvlFlg5 "Delivery Mode Bulkhead Door Open on Vehicle Off Customization Availability Flag 5";
BA_ "SignalType" SG_ 1985 DMBlkhdDrOpnVehOffCstAvlFlg4 "ENM";
BA_ "SignalLongName" SG_ 1985 DMBlkhdDrOpnVehOffCstAvlFlg4 "Delivery Mode Bulkhead Door Open on Vehicle Off Customization Availability Flag 4";
BA_ "SignalType" SG_ 1985 DMBlkhdDrOpnVehOffCstAvlFlg3 "ENM";
BA_ "SignalLongName" SG_ 1985 DMBlkhdDrOpnVehOffCstAvlFlg3 "Delivery Mode Bulkhead Door Open on Vehicle Off Customization Availability Flag 3";
BA_ "SignalType" SG_ 1985 DMBlkhdDrOpnVehOffCstAvlFlg2 "ENM";
BA_ "SignalLongName" SG_ 1985 DMBlkhdDrOpnVehOffCstAvlFlg2 "Delivery Mode Bulkhead Door Open on Vehicle Off Customization Availability Flag 2";
BA_ "SignalType" SG_ 1985 DMBlkhdDrOpnVehOffCstAvlFlg1 "ENM";
BA_ "SignalLongName" SG_ 1985 DMBlkhdDrOpnVehOffCstAvlFlg1 "Delivery Mode Bulkhead Door Open on Vehicle Off Customization Availability Flag 1";
BA_ "SignalType" SG_ 1985 BlkhdDrRmtActvnChmEvntStat "ENM";
BA_ "SignalLongName" SG_ 1985 BlkhdDrRmtActvnChmEvntStat "Bulkhead Door Remote Activation Chime Event State";
BA_ "SignalType" SG_ 1985 BlkhdDrLoclActvnChmEvntStat "ENM";
BA_ "SignalLongName" SG_ 1985 BlkhdDrLoclActvnChmEvntStat "Bulkhead Door Local Activation Chime Event State";
BA_ "SignalType" SG_ 1985 BlkhdDrObstclChmEvntStat "ENM";
BA_ "SignalLongName" SG_ 1985 BlkhdDrObstclChmEvntStat "Bulkhead Door Obstacle Chime Event State";
BA_ "SignalType" SG_ 1985 DMBlkhdDrAutoClsTmCstCurrSetVal "ENM";
BA_ "SignalLongName" SG_ 1985 DMBlkhdDrAutoClsTmCstCurrSetVal "Delivery Mode Bulkhead Door Auto Close Time Customization Current Setting Value";
BA_ "SignalType" SG_ 1985 BlkhdDrServIndOn "ENM";
BA_ "SignalLongName" SG_ 1985 BlkhdDrServIndOn "Bulkhead Door Service Indication On";
BA_ "SignalType" SG_ 1927 DMPDAutoClsTmRFCstSetAval "ENM";
BA_ "SignalLongName" SG_ 1927 DMPDAutoClsTmRFCstSetAval "Delivery Mode Power Door Auto Close Time Right Front Customization Setting Available";
BA_ "SignalType" SG_ 1927 DMPDAutoClsTmRFCstAvlFlg7 "ENM";
BA_ "SignalLongName" SG_ 1927 DMPDAutoClsTmRFCstAvlFlg7 "Delivery Mode Power Door Auto Close Time Right Front Customization Availability Flag 7";
BA_ "SignalType" SG_ 1927 DMPDAutoClsTmRFCstAvlFlg6 "ENM";
BA_ "SignalLongName" SG_ 1927 DMPDAutoClsTmRFCstAvlFlg6 "Delivery Mode Power Door Auto Close Time Right Front Customization Availability Flag 6";
BA_ "SignalType" SG_ 1927 DMPDAutoClsTmRFCstAvlFlg5 "ENM";
BA_ "SignalLongName" SG_ 1927 DMPDAutoClsTmRFCstAvlFlg5 "Delivery Mode Power Door Auto Close Time Right Front Customization Availability Flag 5";
BA_ "SignalType" SG_ 1927 DMPDAutoClsTmRFCstAvlFlg4 "ENM";
BA_ "SignalLongName" SG_ 1927 DMPDAutoClsTmRFCstAvlFlg4 "Delivery Mode Power Door Auto Close Time Right Front Customization Availability Flag 4";
BA_ "SignalType" SG_ 1927 DMPDAutoClsTmRFCstAvlFlg3 "ENM";
BA_ "SignalLongName" SG_ 1927 DMPDAutoClsTmRFCstAvlFlg3 "Delivery Mode Power Door Auto Close Time Right Front Customization Availability Flag 3";
BA_ "SignalType" SG_ 1927 DMPDAutoClsTmRFCstAvlFlg2 "ENM";
BA_ "SignalLongName" SG_ 1927 DMPDAutoClsTmRFCstAvlFlg2 "Delivery Mode Power Door Auto Close Time Right Front Customization Availability Flag 2";
BA_ "SignalType" SG_ 1927 DMPDAutoClsTmRFCstAvlFlg1 "ENM";
BA_ "SignalLongName" SG_ 1927 DMPDAutoClsTmRFCstAvlFlg1 "Delivery Mode Power Door Auto Close Time Right Front Customization Availability Flag 1";
BA_ "SignalType" SG_ 1927 DMPDClsOutofPrkRFCstSetAval "ENM";
BA_ "SignalLongName" SG_ 1927 DMPDClsOutofPrkRFCstSetAval "Delivery Mode Power Door Close Out of Park Right Front Customization Setting Available";
BA_ "SignalType" SG_ 1927 DMPDClsOutofPrkRFCstAvlFlg7 "ENM";
BA_ "SignalLongName" SG_ 1927 DMPDClsOutofPrkRFCstAvlFlg7 "Delivery Mode Power Door Close Out of Park Right Front Customization Availability Flag 7";
BA_ "SignalType" SG_ 1927 DMPDClsOutofPrkRFCstAvlFlg6 "ENM";
BA_ "SignalLongName" SG_ 1927 DMPDClsOutofPrkRFCstAvlFlg6 "Delivery Mode Power Door Close Out of Park Right Front Customization Availability Flag 6";
BA_ "SignalType" SG_ 1927 DMPDClsOutofPrkRFCstAvlFlg5 "ENM";
BA_ "SignalLongName" SG_ 1927 DMPDClsOutofPrkRFCstAvlFlg5 "Delivery Mode Power Door Close Out of Park Right Front Customization Availability Flag 5";
BA_ "SignalType" SG_ 1927 DMPDClsOutofPrkRFCstAvlFlg4 "ENM";
BA_ "SignalLongName" SG_ 1927 DMPDClsOutofPrkRFCstAvlFlg4 "Delivery Mode Power Door Close Out of Park Right Front Customization Availability Flag 4";
BA_ "SignalType" SG_ 1927 DMPDClsOutofPrkRFCstAvlFlg3 "ENM";
BA_ "SignalLongName" SG_ 1927 DMPDClsOutofPrkRFCstAvlFlg3 "Delivery Mode Power Door Close Out of Park Right Front Customization Availability Flag 3";
BA_ "SignalType" SG_ 1927 DMPDClsOutofPrkRFCstAvlFlg2 "ENM";
BA_ "SignalLongName" SG_ 1927 DMPDClsOutofPrkRFCstAvlFlg2 "Delivery Mode Power Door Close Out of Park Right Front Customization Availability Flag 2";
BA_ "SignalType" SG_ 1927 DMPDClsOutofPrkRFCstAvlFlg1 "ENM";
BA_ "SignalLongName" SG_ 1927 DMPDClsOutofPrkRFCstAvlFlg1 "Delivery Mode Power Door Close Out of Park Right Front Customization Availability Flag 1";
BA_ "SignalType" SG_ 1927 DMPDDOBlkhdDrOpnRFCstSetAval "ENM";
BA_ "SignalLongName" SG_ 1927 DMPDDOBlkhdDrOpnRFCstSetAval "Delivery Mode Power Door Delayed Open after Bulkhead Door Open Right Front Customization Setting Available";
BA_ "SignalType" SG_ 1927 DMPDDOBlkhdDrOpnRFCstAvlFlg7 "ENM";
BA_ "SignalLongName" SG_ 1927 DMPDDOBlkhdDrOpnRFCstAvlFlg7 "Delivery Mode Power Door Delayed Open after Bulkhead Door Open Right Front Customization Availability Flag 7";
BA_ "SignalType" SG_ 1927 DMPDDOBlkhdDrOpnRFCstAvlFlg6 "ENM";
BA_ "SignalLongName" SG_ 1927 DMPDDOBlkhdDrOpnRFCstAvlFlg6 "Delivery Mode Power Door Delayed Open after Bulkhead Door Open Right Front Customization Availability Flag 6";
BA_ "SignalType" SG_ 1927 DMPDDOBlkhdDrOpnRFCstAvlFlg5 "ENM";
BA_ "SignalLongName" SG_ 1927 DMPDDOBlkhdDrOpnRFCstAvlFlg5 "Delivery Mode Power Door Delayed Open after Bulkhead Door Open Right Front Customization Availability Flag 5";
BA_ "SignalType" SG_ 1927 DMPDDOBlkhdDrOpnRFCstAvlFlg4 "ENM";
BA_ "SignalLongName" SG_ 1927 DMPDDOBlkhdDrOpnRFCstAvlFlg4 "Delivery Mode Power Door Delayed Open after Bulkhead Door Open Right Front Customization Availability Flag 4";
BA_ "SignalType" SG_ 1927 DMPDDOBlkhdDrOpnRFCstAvlFlg3 "ENM";
BA_ "SignalLongName" SG_ 1927 DMPDDOBlkhdDrOpnRFCstAvlFlg3 "Delivery Mode Power Door Delayed Open after Bulkhead Door Open Right Front Customization Availability Flag 3";
BA_ "SignalType" SG_ 1927 DMPDDOBlkhdDrOpnRFCstAvlFlg2 "ENM";
BA_ "SignalLongName" SG_ 1927 DMPDDOBlkhdDrOpnRFCstAvlFlg2 "Delivery Mode Power Door Delayed Open after Bulkhead Door Open Right Front Customization Availability Flag 2";
BA_ "SignalType" SG_ 1927 DMPDDOBlkhdDrOpnRFCstAvlFlg1 "ENM";
BA_ "SignalLongName" SG_ 1927 DMPDDOBlkhdDrOpnRFCstAvlFlg1 "Delivery Mode Power Door Delayed Open after Bulkhead Door Open Right Front Customization Availability Flag 1";
BA_ "SignalType" SG_ 1927 SCAOOAByKeyFobRFCstSetAval "ENM";
BA_ "SignalLongName" SG_ 1927 SCAOOAByKeyFobRFCstSetAval "Side Closure Access Open On Approach By Key Fob Right Front Customization Setting Available";
BA_ "SignalType" SG_ 1927 SCAOOAByKeyFobRFCstAvlFlg7 "ENM";
BA_ "SignalLongName" SG_ 1927 SCAOOAByKeyFobRFCstAvlFlg7 "Side Closure Access Open On Approach By Key Fob Right Front Customization Availability Flag 7";
BA_ "SignalType" SG_ 1927 SCAOOAByKeyFobRFCstAvlFlg6 "ENM";
BA_ "SignalLongName" SG_ 1927 SCAOOAByKeyFobRFCstAvlFlg6 "Side Closure Access Open On Approach By Key Fob Right Front Customization Availability Flag 6";
BA_ "SignalType" SG_ 1927 SCAOOAByKeyFobRFCstAvlFlg5 "ENM";
BA_ "SignalLongName" SG_ 1927 SCAOOAByKeyFobRFCstAvlFlg5 "Side Closure Access Open On Approach By Key Fob Right Front Customization Availability Flag 5";
BA_ "SignalType" SG_ 1927 SCAOOAByKeyFobRFCstAvlFlg4 "ENM";
BA_ "SignalLongName" SG_ 1927 SCAOOAByKeyFobRFCstAvlFlg4 "Side Closure Access Open On Approach By Key Fob Right Front Customization Availability Flag 4";
BA_ "SignalType" SG_ 1927 SCAOOAByKeyFobRFCstAvlFlg3 "ENM";
BA_ "SignalLongName" SG_ 1927 SCAOOAByKeyFobRFCstAvlFlg3 "Side Closure Access Open On Approach By Key Fob Right Front Customization Availability Flag 3";
BA_ "SignalType" SG_ 1927 SCAOOAByKeyFobRFCstAvlFlg2 "ENM";
BA_ "SignalLongName" SG_ 1927 SCAOOAByKeyFobRFCstAvlFlg2 "Side Closure Access Open On Approach By Key Fob Right Front Customization Availability Flag 2";
BA_ "SignalType" SG_ 1927 SCAOOAByKeyFobRFCstAvlFlg1 "ENM";
BA_ "SignalLongName" SG_ 1927 SCAOOAByKeyFobRFCstAvlFlg1 "Side Closure Access Open On Approach By Key Fob Right Front Customization Availability Flag 1";
BA_ "SignalType" SG_ 1927 SCAOOAByVirtKeyRFCstSetAval "ENM";
BA_ "SignalLongName" SG_ 1927 SCAOOAByVirtKeyRFCstSetAval "Side Closure Access Open On Approach By Virtual Key Right Front Customization Setting Available";
BA_ "SignalType" SG_ 1927 SCAOOAByVirtKeyRFCstAvlFlg7 "ENM";
BA_ "SignalLongName" SG_ 1927 SCAOOAByVirtKeyRFCstAvlFlg7 "Side Closure Access Open On Approach By Virtual Key Right Front Customization Availability Flag 7";
BA_ "SignalType" SG_ 1927 SCAOOAByVirtKeyRFCstAvlFlg6 "ENM";
BA_ "SignalLongName" SG_ 1927 SCAOOAByVirtKeyRFCstAvlFlg6 "Side Closure Access Open On Approach By Virtual Key Right Front Customization Availability Flag 6";
BA_ "SignalType" SG_ 1927 SCAOOAByVirtKeyRFCstAvlFlg5 "ENM";
BA_ "SignalLongName" SG_ 1927 SCAOOAByVirtKeyRFCstAvlFlg5 "Side Closure Access Open On Approach By Virtual Key Right Front Customization Availability Flag 5";
BA_ "SignalType" SG_ 1927 SCAOOAByVirtKeyRFCstAvlFlg4 "ENM";
BA_ "SignalLongName" SG_ 1927 SCAOOAByVirtKeyRFCstAvlFlg4 "Side Closure Access Open On Approach By Virtual Key Right Front Customization Availability Flag 4";
BA_ "SignalType" SG_ 1927 SCAOOAByVirtKeyRFCstAvlFlg3 "ENM";
BA_ "SignalLongName" SG_ 1927 SCAOOAByVirtKeyRFCstAvlFlg3 "Side Closure Access Open On Approach By Virtual Key Right Front Customization Availability Flag 3";
BA_ "SignalType" SG_ 1927 SCAOOAByVirtKeyRFCstAvlFlg2 "ENM";
BA_ "SignalLongName" SG_ 1927 SCAOOAByVirtKeyRFCstAvlFlg2 "Side Closure Access Open On Approach By Virtual Key Right Front Customization Availability Flag 2";
BA_ "SignalType" SG_ 1927 SCAOOAByVirtKeyRFCstAvlFlg1 "ENM";
BA_ "SignalLongName" SG_ 1927 SCAOOAByVirtKeyRFCstAvlFlg1 "Side Closure Access Open On Approach By Virtual Key Right Front Customization Availability Flag 1";
BA_ "SignalType" SG_ 1927 SCAPDBrktoClsRFCstSetAval "ENM";
BA_ "SignalLongName" SG_ 1927 SCAPDBrktoClsRFCstSetAval "Side Closure Access Power Door Brake to Close Right Front Customization Setting Available";
BA_ "SignalType" SG_ 1927 SCAPDBrktoClsRFCstAvlFlg7 "ENM";
BA_ "SignalLongName" SG_ 1927 SCAPDBrktoClsRFCstAvlFlg7 "Side Closure Access Power Door Brake to Close Right Front Customization Availability Flag 7";
BA_ "SignalType" SG_ 1927 SCAPDBrktoClsRFCstAvlFlg6 "ENM";
BA_ "SignalLongName" SG_ 1927 SCAPDBrktoClsRFCstAvlFlg6 "Side Closure Access Power Door Brake to Close Right Front Customization Availability Flag 6";
BA_ "SignalType" SG_ 1927 SCAPDBrktoClsRFCstAvlFlg5 "ENM";
BA_ "SignalLongName" SG_ 1927 SCAPDBrktoClsRFCstAvlFlg5 "Side Closure Access Power Door Brake to Close Right Front Customization Availability Flag 5";
BA_ "SignalType" SG_ 1927 SCAPDBrktoClsRFCstAvlFlg4 "ENM";
BA_ "SignalLongName" SG_ 1927 SCAPDBrktoClsRFCstAvlFlg4 "Side Closure Access Power Door Brake to Close Right Front Customization Availability Flag 4";
BA_ "SignalType" SG_ 1927 SCAPDBrktoClsRFCstAvlFlg3 "ENM";
BA_ "SignalLongName" SG_ 1927 SCAPDBrktoClsRFCstAvlFlg3 "Side Closure Access Power Door Brake to Close Right Front Customization Availability Flag 3";
BA_ "SignalType" SG_ 1927 SCAPDBrktoClsRFCstAvlFlg2 "ENM";
BA_ "SignalLongName" SG_ 1927 SCAPDBrktoClsRFCstAvlFlg2 "Side Closure Access Power Door Brake to Close Right Front Customization Availability Flag 2";
BA_ "SignalType" SG_ 1927 SCAPDBrktoClsRFCstAvlFlg1 "ENM";
BA_ "SignalLongName" SG_ 1927 SCAPDBrktoClsRFCstAvlFlg1 "Side Closure Access Power Door Brake to Close Right Front Customization Availability Flag 1";
BA_ "SignalType" SG_ 1927 SCAPDBrktoClsRFCstCurrSetVal "ENM";
BA_ "SignalLongName" SG_ 1927 SCAPDBrktoClsRFCstCurrSetVal "Side Closure Access Power Door Brake to Close Right Front Customization Current Setting Value";
BA_ "SignalType" SG_ 1927 DMPDClsOutofPrkRFCstCurrSetVal "ENM";
BA_ "SignalLongName" SG_ 1927 DMPDClsOutofPrkRFCstCurrSetVal "Delivery Mode Power Door Close Out of Park Right Front Customization Current Setting Value";
BA_ "SignalType" SG_ 1927 DMPDAutoClsTmRFCstCurrSetVal "ENM";
BA_ "SignalLongName" SG_ 1927 DMPDAutoClsTmRFCstCurrSetVal "Delivery Mode Power Door Auto Close Time Right Front Customization Current Setting Value";
BA_ "SignalType" SG_ 1927 SCAPwrDrMtnRFVirtCtlAval "ENM";
BA_ "SignalLongName" SG_ 1927 SCAPwrDrMtnRFVirtCtlAval "Side Closure Access Power Door Motion Right Front Virtual Control Available";
BA_ "SignalType" SG_ 1927 PwrSdClsrRFServIndOn "ENM";
BA_ "SignalLongName" SG_ 1927 PwrSdClsrRFServIndOn "Power Side Closure Right Front Service Indication On";
BA_ "SignalType" SG_ 1927 PwrSdClsrRFBlckdIndOn "ENM";
BA_ "SignalLongName" SG_ 1927 PwrSdClsrRFBlckdIndOn "Power Side Closure Right Front Blocked Indication On";
BA_ "SignalType" SG_ 1927 SCAPwrDrMtnRFVirtCtlAllwd "ENM";
BA_ "SignalLongName" SG_ 1927 SCAPwrDrMtnRFVirtCtlAllwd "Side Closure Access Power Door Motion Right Front Virtual Control Allowed";
BA_ "SignalType" SG_ 1930 StMasgTyp11RFVirtCtlAval "ENM";
BA_ "SignalLongName" SG_ 1930 StMasgTyp11RFVirtCtlAval "Seat Right Front Virtual Control Available Information : Seat Massage Type 11 Right Front Virtual Control Available";
BA_ "SignalType" SG_ 1930 StMasgTyp10RFVirtCtlAval "ENM";
BA_ "SignalLongName" SG_ 1930 StMasgTyp10RFVirtCtlAval "Seat Right Front Virtual Control Available Information : Seat Massage Type 10 Right Front Virtual Control Available";
BA_ "SignalType" SG_ 1930 StHdrstVertRFVirtCtlAval "ENM";
BA_ "SignalLongName" SG_ 1930 StHdrstVertRFVirtCtlAval "Seat Right Front Virtual Control Available Information : Seat Headrest Vertical Right Front Virtual Control Available";
BA_ "SignalType" SG_ 1930 StHdrstHrztlRFVirtCtlAval "ENM";
BA_ "SignalLongName" SG_ 1930 StHdrstHrztlRFVirtCtlAval "Seat Right Front Virtual Control Available Information : Seat Headrest Horizontal Right Front Virtual Control Available";
BA_ "SignalType" SG_ 1930 StCushSdBolsRFVirtCtlAval "ENM";
BA_ "SignalLongName" SG_ 1930 StCushSdBolsRFVirtCtlAval "Seat Right Front Virtual Control Available Information : Seat Cushion Side Bolster Right Front Virtual Control Available";
BA_ "SignalType" SG_ 1930 StCushRrVertRFVirtCtlAval "ENM";
BA_ "SignalLongName" SG_ 1930 StCushRrVertRFVirtCtlAval "Seat Right Front Virtual Control Available Information : Seat Cushion Rear Vertical Right Front Virtual Control Available";
BA_ "SignalType" SG_ 1930 StCushLgthHrztlRFVirtCtlAval "ENM";
BA_ "SignalLongName" SG_ 1930 StCushLgthHrztlRFVirtCtlAval "Seat Right Front Virtual Control Available Information : Seat Cushion Length Horizontal Right Front Virtual Control Available";
BA_ "SignalType" SG_ 1930 StCushHrztlRFCtlFrmRrVirtCtlAvl "ENM";
BA_ "SignalLongName" SG_ 1930 StCushHrztlRFCtlFrmRrVirtCtlAvl "Seat Right Front Virtual Control Available Information : Seat Cushion Horizontal Right Front Control From Rear Virtual Control Available";
BA_ "SignalType" SG_ 1930 StMasgTyp4RFVirtCtlAval "ENM";
BA_ "SignalLongName" SG_ 1930 StMasgTyp4RFVirtCtlAval "Seat Right Front Virtual Control Available Information : Seat Massage Type 4 Right Front Virtual Control Available";
BA_ "SignalType" SG_ 1930 StMasgTyp3RFVirtCtlAval "ENM";
BA_ "SignalLongName" SG_ 1930 StMasgTyp3RFVirtCtlAval "Seat Right Front Virtual Control Available Information : Seat Massage Type 3 Right Front Virtual Control Available";
BA_ "SignalType" SG_ 1930 StMasgTyp2RFVirtCtlAval "ENM";
BA_ "SignalLongName" SG_ 1930 StMasgTyp2RFVirtCtlAval "Seat Right Front Virtual Control Available Information : Seat Massage Type 2 Right Front Virtual Control Available";
BA_ "SignalType" SG_ 1930 StMasgTyp1RFVirtCtlAval "ENM";
BA_ "SignalLongName" SG_ 1930 StMasgTyp1RFVirtCtlAval "Seat Right Front Virtual Control Available Information : Seat Massage Type 1 Right Front Virtual Control Available";
BA_ "SignalType" SG_ 1930 StMasgTyp15RFVirtCtlAval "ENM";
BA_ "SignalLongName" SG_ 1930 StMasgTyp15RFVirtCtlAval "Seat Right Front Virtual Control Available Information : Seat Massage Type 15 Right Front Virtual Control Available";
BA_ "SignalType" SG_ 1930 StMasgTyp14RFVirtCtlAval "ENM";
BA_ "SignalLongName" SG_ 1930 StMasgTyp14RFVirtCtlAval "Seat Right Front Virtual Control Available Information : Seat Massage Type 14 Right Front Virtual Control Available";
BA_ "SignalType" SG_ 1930 StMasgTyp13RFVirtCtlAval "ENM";
BA_ "SignalLongName" SG_ 1930 StMasgTyp13RFVirtCtlAval "Seat Right Front Virtual Control Available Information : Seat Massage Type 13 Right Front Virtual Control Available";
BA_ "SignalType" SG_ 1930 StMasgTyp12RFVirtCtlAval "ENM";
BA_ "SignalLongName" SG_ 1930 StMasgTyp12RFVirtCtlAval "Seat Right Front Virtual Control Available Information : Seat Massage Type 12 Right Front Virtual Control Available";
BA_ "SignalType" SG_ 1930 StCushLgthHrztlRFVirtCtlAllwd "ENM";
BA_ "SignalLongName" SG_ 1930 StCushLgthHrztlRFVirtCtlAllwd "Seat Right Front Virtual Control Allowed Information : Seat Cushion Length Horizontal Right Front Virtual Control Allowed";
BA_ "SignalType" SG_ 1930 StCushHrztlRFCtlFrmRrVirCtlAlwd "ENM";
BA_ "SignalLongName" SG_ 1930 StCushHrztlRFCtlFrmRrVirCtlAlwd "Seat Right Front Virtual Control Allowed Information : Seat Cushion Horizontal Right Front Control From Rear Virtual Control Allowed";
BA_ "SignalType" SG_ 1930 StCushHrztlRFCtlFrmFrVirCtlAlwd "ENM";
BA_ "SignalLongName" SG_ 1930 StCushHrztlRFCtlFrmFrVirCtlAlwd "Seat Right Front Virtual Control Allowed Information : Seat Cushion Horizontal Right Front Control From Front Virtual Control Allowed";
BA_ "SignalType" SG_ 1930 StCushFrtVertRFVirtCtlAllwd "ENM";
BA_ "SignalLongName" SG_ 1930 StCushFrtVertRFVirtCtlAllwd "Seat Right Front Virtual Control Allowed Information : Seat Cushion Front Vertical Right Front Virtual Control Allowed";
BA_ "SignalType" SG_ 1930 StBkSdBolsRFVirtCtlAllwd "ENM";
BA_ "SignalLongName" SG_ 1930 StBkSdBolsRFVirtCtlAllwd "Seat Right Front Virtual Control Allowed Information : Seat Back Side Bolster Right Front Virtual Control Allowed";
BA_ "SignalType" SG_ 1930 StBkLumbVertRFVirtCtlAllwd "ENM";
BA_ "SignalLongName" SG_ 1930 StBkLumbVertRFVirtCtlAllwd "Seat Right Front Virtual Control Allowed Information : Seat Back Lumbar Vertical Right Front Virtual Control Allowed";
BA_ "SignalType" SG_ 1930 StBkLumbHrztlRFVirtCtlAllwd "ENM";
BA_ "SignalLongName" SG_ 1930 StBkLumbHrztlRFVirtCtlAllwd "Seat Right Front Virtual Control Allowed Information : Seat Back Lumbar Horizontal Right Front Virtual Control Allowed";
BA_ "SignalType" SG_ 1930 StBkHrztlRFCtlFrmRrVirtCtlAllwd "ENM";
BA_ "SignalLongName" SG_ 1930 StBkHrztlRFCtlFrmRrVirtCtlAllwd "Seat Right Front Virtual Control Allowed Information : Seat Back Horizontal Right Front Control From Rear Virtual Control Allowed";
BA_ "SignalType" SG_ 1930 StMasgTypRFLstKnwnSet "ENM";
BA_ "SignalLongName" SG_ 1930 StMasgTypRFLstKnwnSet "Seat Right Front Massage Setting Information : Seat Massage Type Right Front Last Known Setting";
BA_ "SignalType" SG_ 1930 StBkHrztlRFCtlFrmFrtVirtCtlAlwd "ENM";
BA_ "SignalLongName" SG_ 1930 StBkHrztlRFCtlFrmFrtVirtCtlAlwd "Seat Right Front Virtual Control Allowed Information : Seat Back Horizontal Right Front Control From Front Virtual Control Allowed";
BA_ "SignalType" SG_ 1930 StUpprShldrHrztlRFVirtCtlAllwd "ENM";
BA_ "SignalLongName" SG_ 1930 StUpprShldrHrztlRFVirtCtlAllwd "Seat Right Front Virtual Control Allowed Information : Seat Upper Shoulder Horizontal Right Front Virtual Control Allowed";
BA_ "SignalType" SG_ 1930 StMasgRFVirtCtlAllwd "ENM";
BA_ "SignalLongName" SG_ 1930 StMasgRFVirtCtlAllwd "Seat Right Front Virtual Control Allowed Information : Seat Massage Right Front Virtual Control Allowed";
BA_ "SignalType" SG_ 1930 StHdrstVertRFVirtCtlAllwd "ENM";
BA_ "SignalLongName" SG_ 1930 StHdrstVertRFVirtCtlAllwd "Seat Right Front Virtual Control Allowed Information : Seat Headrest Vertical Right Front Virtual Control Allowed";
BA_ "SignalType" SG_ 1930 StHdrstHrztlRFVirtCtlAllwd "ENM";
BA_ "SignalLongName" SG_ 1930 StHdrstHrztlRFVirtCtlAllwd "Seat Right Front Virtual Control Allowed Information : Seat Headrest Horizontal Right Front Virtual Control Allowed";
BA_ "SignalType" SG_ 1930 StCushSdBolsRFVirtCtlAllwd "ENM";
BA_ "SignalLongName" SG_ 1930 StCushSdBolsRFVirtCtlAllwd "Seat Right Front Virtual Control Allowed Information : Seat Cushion Side Bolster Right Front Virtual Control Allowed";
BA_ "SignalType" SG_ 1930 StCushRrVertRFVirtCtlAllwd "ENM";
BA_ "SignalLongName" SG_ 1930 StCushRrVertRFVirtCtlAllwd "Seat Right Front Virtual Control Allowed Information : Seat Cushion Rear Vertical Right Front Virtual Control Allowed";
BA_ "SignalType" SG_ 1930 StMemRFVirtCtlNumofExtPstnsAval "ENM";
BA_ "SignalLongName" SG_ 1930 StMemRFVirtCtlNumofExtPstnsAval "Seat Memory Right Front Virtual Control Number of Exit Positions Available";
BA_ "SignalType" SG_ 1930 StMasgIntstyRFLstKnwnSet "ENM";
BA_ "SignalLongName" SG_ 1930 StMasgIntstyRFLstKnwnSet "Seat Right Front Massage Setting Information : Seat Massage Intensity Right Front Last Known Setting";
BA_ "SignalLongName" SG_ 1930 StMasgIntstyRFVirtCtlMaxLvl "Seat Right Front Virtual Control Available Information : Seat Massage Intensity Right Front Virtual Control Maximum Level";
BA_ "SignalType" SG_ 1930 StMemRFVirtCtlNumofMemPstnsAval "ENM";
BA_ "SignalLongName" SG_ 1930 StMemRFVirtCtlNumofMemPstnsAval "Seat Memory Right Front Virtual Control Number of Memory Positions Available";
BA_ "SignalType" SG_ 1930 StCushHrztlRFCtlFrmFrtVirCtlAvl "ENM";
BA_ "SignalLongName" SG_ 1930 StCushHrztlRFCtlFrmFrtVirCtlAvl "Seat Right Front Virtual Control Available Information : Seat Cushion Horizontal Right Front Control From Front Virtual Control Available";
BA_ "SignalType" SG_ 1930 StCushFrtVertRFVirtCtlAval "ENM";
BA_ "SignalLongName" SG_ 1930 StCushFrtVertRFVirtCtlAval "Seat Right Front Virtual Control Available Information : Seat Cushion Front Vertical Right Front Virtual Control Available";
BA_ "SignalType" SG_ 1930 StBkSdBolsRFVirtCtlAval "ENM";
BA_ "SignalLongName" SG_ 1930 StBkSdBolsRFVirtCtlAval "Seat Right Front Virtual Control Available Information : Seat Back Side Bolster Right Front Virtual Control Available";
BA_ "SignalType" SG_ 1930 StBkLumbVertRFVirtCtlAval "ENM";
BA_ "SignalLongName" SG_ 1930 StBkLumbVertRFVirtCtlAval "Seat Right Front Virtual Control Available Information : Seat Back Lumbar Vertical Right Front Virtual Control Available";
BA_ "SignalType" SG_ 1930 StBkLumbHrztlRFVirtCtlAval "ENM";
BA_ "SignalLongName" SG_ 1930 StBkLumbHrztlRFVirtCtlAval "Seat Right Front Virtual Control Available Information : Seat Back Lumbar Horizontal Right Front Virtual Control Available";
BA_ "SignalType" SG_ 1930 StBkHrztlRFCtlFrmRrVirtCtlAval "ENM";
BA_ "SignalLongName" SG_ 1930 StBkHrztlRFCtlFrmRrVirtCtlAval "Seat Right Front Virtual Control Available Information : Seat Back Horizontal Right Front Control From Rear Virtual Control Available";
BA_ "SignalType" SG_ 1930 StBkHrztlRFCtlFrmFrtVirtCtlAval "ENM";
BA_ "SignalLongName" SG_ 1930 StBkHrztlRFCtlFrmFrtVirtCtlAval "Seat Right Front Virtual Control Available Information : Seat Back Horizontal Right Front Control From Front Virtual Control Available";
BA_ "SignalType" SG_ 1930 StMemRFVirtCtlStorAllwd "ENM";
BA_ "SignalLongName" SG_ 1930 StMemRFVirtCtlStorAllwd "Seat Memory Right Front Virtual Control Store Allowed";
BA_ "SignalType" SG_ 1930 StMemRFVirtCtlRclAllwd "ENM";
BA_ "SignalLongName" SG_ 1930 StMemRFVirtCtlRclAllwd "Seat Memory Right Front Virtual Control Recall Allowed";
BA_ "SignalType" SG_ 1930 StUpprShldrHrztlRFVirtCtlAval "ENM";
BA_ "SignalLongName" SG_ 1930 StUpprShldrHrztlRFVirtCtlAval "Seat Right Front Virtual Control Available Information : Seat Upper Shoulder Horizontal Right Front Virtual Control Available";
BA_ "SignalType" SG_ 1930 StMasgTyp9RFVirtCtlAval "ENM";
BA_ "SignalLongName" SG_ 1930 StMasgTyp9RFVirtCtlAval "Seat Right Front Virtual Control Available Information : Seat Massage Type 9 Right Front Virtual Control Available";
BA_ "SignalType" SG_ 1930 StMasgTyp8RFVirtCtlAval "ENM";
BA_ "SignalLongName" SG_ 1930 StMasgTyp8RFVirtCtlAval "Seat Right Front Virtual Control Available Information : Seat Massage Type 8 Right Front Virtual Control Available";
BA_ "SignalType" SG_ 1930 StMasgTyp7RFVirtCtlAval "ENM";
BA_ "SignalLongName" SG_ 1930 StMasgTyp7RFVirtCtlAval "Seat Right Front Virtual Control Available Information : Seat Massage Type 7 Right Front Virtual Control Available";
BA_ "SignalType" SG_ 1930 StMasgTyp6RFVirtCtlAval "ENM";
BA_ "SignalLongName" SG_ 1930 StMasgTyp6RFVirtCtlAval "Seat Right Front Virtual Control Available Information : Seat Massage Type 6 Right Front Virtual Control Available";
BA_ "SignalType" SG_ 1930 StMasgTyp5RFVirtCtlAval "ENM";
BA_ "SignalLongName" SG_ 1930 StMasgTyp5RFVirtCtlAval "Seat Right Front Virtual Control Available Information : Seat Massage Type 5 Right Front Virtual Control Available";
VAL_ 1415 ACCAutoStSpStat 0 "No_Set_Speed_Change" 1 "Proposed_Speed_Limit_Change" 2 "Accepted_Speed_Limit_Change" 3 "Declined_Speed_Limit_Change" ;
VAL_ 1415 ACCSpdLimSgnUnt 0 "km/h" 1 "mph" ;
VAL_ 1415 ACCDrSlctdSpdIndOn 0 "FALSE" 1 "TRUE" ;
VAL_ 1415 FrwdImpMtgnOpSlctCstCrStVal 0 "SETTING_UNKNOWN" 1 "OFF" 2 "ALERT" 3 "ALERT_BRAKE" 4 "ALERT_BRAKE_STEER" 5 "RESERVED_5" 6 "RESERVED_6" 7 "RESERVED_7" ;
VAL_ 1415 FrntPCMRspTypCstCrStVal 0 "SETTING_UNKNOWN" 1 "OFF" 2 "ALERT" 3 "ALERT_AND_BRAKE" 4 "ALERT_AND_BRAKE_AND_STEER" 5 "RESERVED_5" 6 "RESERVED_6" 7 "RESERVED_7" ;
VAL_ 1415 ACCSysSlctdMd 0 "Cruise Control Mode Switching Not Supported" 1 "Adaptive Cruise Control" 2 "Enhanced Cruise Control" ;
VAL_ 1415 FrntPCMRspTypCstAvlFlg1 0 "FALSE" 1 "TRUE" ;
VAL_ 1415 AutoEmrgBrkgDsbldIndOn 0 "FALSE" 1 "TRUE" ;
VAL_ 1415 ACCGoNtfrChmEvntSt 0 "NO_ACTION" 1 "ACTIVE" ;
VAL_ 1415 AnmlWrnIndReq 0 "Off" 1 "Animal Advisory" 2 "Animal Alert" ;
VAL_ 1415 FrwdVehAhdIndReq 0 "OFF" 1 "ON" 2 "0.5_Hz" 3 "1_Hz" 4 "2_Hz" 5 "4_Hz" ;
VAL_ 1415 FrtPedtrnClsnMtgnAudAttnReqd 0 "FALSE" 1 "TRUE" ;
VAL_ 1415 FrntPCMRspTypCstStAvl 0 "FALSE" 1 "TRUE" ;
VAL_ 1415 FrntPCMRspTypCstAvlFlg7 0 "FALSE" 1 "TRUE" ;
VAL_ 1415 FrntPCMRspTypCstAvlFlg6 0 "FALSE" 1 "TRUE" ;
VAL_ 1415 FrntPCMRspTypCstAvlFlg5 0 "FALSE" 1 "TRUE" ;
VAL_ 1415 FrntPCMRspTypCstAvlFlg4 0 "FALSE" 1 "TRUE" ;
VAL_ 1415 FrntPCMRspTypCstAvlFlg3 0 "FALSE" 1 "TRUE" ;
VAL_ 1415 FrntPCMRspTypCstAvlFlg2 0 "FALSE" 1 "TRUE" ;
VAL_ 1415 FrwdImpMtgnOpSlctCstAvlFlg7 0 "FALSE" 1 "TRUE" ;
VAL_ 1415 FrwdImpMtgnOpSlctCstAvlFlg6 0 "FALSE" 1 "TRUE" ;
VAL_ 1415 FrwdImpMtgnOpSlctCstAvlFlg5 0 "FALSE" 1 "TRUE" ;
VAL_ 1415 FrwdImpMtgnOpSlctCstAvlFlg4 0 "FALSE" 1 "TRUE" ;
VAL_ 1415 FrwdImpMtgnOpSlctCstAvlFlg3 0 "FALSE" 1 "TRUE" ;
VAL_ 1415 FrwdImpMtgnOpSlctCstAvlFlg2 0 "FALSE" 1 "TRUE" ;
VAL_ 1415 FrwdImpMtgnOpSlctCstAvlFlg1 0 "FALSE" 1 "TRUE" ;
VAL_ 1415 FrwdClsnAlrtImntAlrtAudAttnReqd 0 "FALSE" 1 "TRUE" ;
VAL_ 1415 GoNotfrCstAvlFlg7 0 "FALSE" 1 "TRUE" ;
VAL_ 1415 GoNotfrCstAvlFlg6 0 "FALSE" 1 "TRUE" ;
VAL_ 1415 GoNotfrCstAvlFlg5 0 "FALSE" 1 "TRUE" ;
VAL_ 1415 GoNotfrCstAvlFlg4 0 "FALSE" 1 "TRUE" ;
VAL_ 1415 GoNotfrCstAvlFlg3 0 "FALSE" 1 "TRUE" ;
VAL_ 1415 GoNotfrCstAvlFlg2 0 "FALSE" 1 "TRUE" ;
VAL_ 1415 GoNotfrCstAvlFlg1 0 "FALSE" 1 "TRUE" ;
VAL_ 1415 FrwdImpMtgnOpSlctCstStAvl 0 "FALSE" 1 "TRUE" ;
VAL_ 73 PrplSysSndEnhtAdjdEngTrqEst_Inv 0 "FALSE" 1 "TRUE" ;
VAL_ 1147 HVBCC_DyOfWk 0 "Unknown" 1 "Sunday" 2 "Monday" 3 "Tuesday" 4 "Wednesday" 5 "Thursday" 6 "Friday" 7 "Saturday" ;
VAL_ 1147 HVBCC_TmDispFormat 0 "No Action" 1 "Display Complete Time" 2 "Display Minutes to Complete" ;
VAL_ 1147 HVBCC_MinRmn_DuD 0 "FALSE" 1 "TRUE" ;
VAL_ 1147 HVBCC_TmDispPwrLvl 0 "Unknown" 1 "Level 1" 2 "Level 2" 3 "DC" 4 "Wireless" ;
VAL_ 1349 ACCAutoSetSpdCstCurrSetVal 0 "Setting Unknown" 1 "Off" 2 "On" ;
VAL_ 1349 ACCAutoSetSpdCstAvlFlg7 0 "FALSE" 1 "TRUE" ;
VAL_ 1349 ACCAutoSetSpdCstAvlFlg6 0 "FALSE" 1 "TRUE" ;
VAL_ 1349 ACCAutoSetSpdCstAvlFlg5 0 "FALSE" 1 "TRUE" ;
VAL_ 1349 ACCAutoSetSpdCstAvlFlg4 0 "FALSE" 1 "TRUE" ;
VAL_ 1349 ACCAutoSetSpdCstAvlFlg3 0 "FALSE" 1 "TRUE" ;
VAL_ 1349 ACCAutoSetSpdCstAvlFlg2 0 "FALSE" 1 "TRUE" ;
VAL_ 1349 ACCAutoSetSpdCstAvlFlg1 0 "FALSE" 1 "TRUE" ;
VAL_ 1349 LnKpAsstVirtCtlAval 0 "Not Available" 1 "Available" ;
VAL_ 1349 ACCAutoSetSpdUnvIndOn 0 "FALSE" 1 "TRUE" ;
VAL_ 1349 ACCAutoSetSpdCstSetAval 0 "FALSE" 1 "TRUE" ;
VAL_ 1349 FCASensCstAvlFlg1 0 "FALSE" 1 "TRUE" ;
VAL_ 1349 FCASensCstCurrSetVal 0 "SettingUnknown" 1 "Off" 2 "Low" 3 "Medium" 4 "High" ;
VAL_ 1349 FCASensCstSetAval 0 "FALSE" 1 "TRUE" ;
VAL_ 1349 BlndZnStrgAsstVirtCtlAval 0 "Not Available" 1 "Available" ;
VAL_ 1349 BlndZnStrgAsstVirtUserCtlAllwd 0 "Not Allowed" 1 "Allowed" ;
VAL_ 1349 FCASensCstAvlFlg7 0 "FALSE" 1 "TRUE" ;
VAL_ 1349 FCASensCstAvlFlg6 0 "FALSE" 1 "TRUE" ;
VAL_ 1349 FCASensCstAvlFlg5 0 "FALSE" 1 "TRUE" ;
VAL_ 1349 FCASensCstAvlFlg4 0 "FALSE" 1 "TRUE" ;
VAL_ 1349 FCASensCstAvlFlg3 0 "FALSE" 1 "TRUE" ;
VAL_ 1349 FCASensCstAvlFlg2 0 "FALSE" 1 "TRUE" ;
VAL_ 1349 TrfcJamAsstVirtCtlAllwd 0 "Not Allowed" 1 "Allowed" ;
VAL_ 1349 LnDtnWrnSpprssnVrtCtlCurrSltnVl 0 "Unknown" 1 "Off" 2 "On" ;
VAL_ 1349 LnDtnWrnSpprssnVirtCtlAval 0 "Not Available" 1 "Available" ;
VAL_ 1349 LnDtnWrnSpprssnVirtUserCtlAllwd 0 "Not Allowed" 1 "Allowed" ;
VAL_ 1349 BlndZnStrgAsstVrtCtlCurrSltnVl 0 "Unknown" 1 "Off" 2 "On" ;
VAL_ 2010 RrStrgModeVirtCtlAval 0 "Not Available" 1 "Available" ;
VAL_ 2010 RrStrgModeSmrtCtlIcnReqd 0 "FALSE" 1 "TRUE" ;
VAL_ 1275 EPBStpOnBrkToRelPrkBrkIndReq 0 "OFF" 1 "ON" 2 "0.5_Hz" 3 "1_Hz" 4 "2_Hz" 5 "4_Hz" 6 "RESERVED_1" 7 "RESERVED_2" ;
VAL_ 1275 VehStbEnhcmntCustAv 0 "FALSE" 1 "TRUE" ;
VAL_ 1275 VehStbEnhcmntCurStat 0 "On" 1 "Off" ;
VAL_ 1275 VehStbCompMdCustAv 0 "FALSE" 1 "TRUE" ;
VAL_ 1275 VehStbCompMdCurStat 0 "On" 1 "Off" ;
VAL_ 1275 TrcCntrlSysTmpDisReqIO 0 "FALSE" 1 "TRUE" ;
VAL_ 1275 TCSCustAv 0 "FALSE" 1 "TRUE" ;
VAL_ 1275 TCSCurStat 0 "On" 1 "Off" ;
VAL_ 1275 OffRdMdActvAerodynsVisDispVal 0 "Setting_Unknown" 1 "Custom_Mode_1" 2 "Custom_Mode_2" 3 "Custom_Mode_3" 4 "Custom_Mode_4" 5 "Custom_Mode_5" 6 "Custom_Mode_6" 7 "Custom_Mode_7" ;
VAL_ 1275 ElecPrkBrkSysDisIndReq 0 "OFF" 1 "ALERT_1" 2 "ALERT_2" 3 "ALERT_3" 4 "ALERT_4" 5 "ALERT_5" 6 "ALERT_6" 7 "ALERT_7" ;
VAL_ 1275 OffRdMdESCVisDispVal 0 "Setting_Unknown" 1 "Custom_Mode_1" 2 "Custom_Mode_2" 3 "Custom_Mode_3" 4 "Custom_Mode_4" 5 "Custom_Mode_5" 6 "Custom_Mode_6" 7 "Custom_Mode_7" ;
VAL_ 1275 OffRdMdDrvlnVisDispVal 0 "Setting_Unknown" 1 "Custom_Mode_1" 2 "Custom_Mode_2" 3 "Custom_Mode_3" 4 "Custom_Mode_4" 5 "Custom_Mode_5" 6 "Custom_Mode_6" 7 "Custom_Mode_7" ;
VAL_ 1275 OffRdMdBrkPedVisDispVal 0 "Setting_Unknown" 1 "Custom_Mode_1" 2 "Custom_Mode_2" 3 "Custom_Mode_3" 4 "Custom_Mode_4" 5 "Custom_Mode_5" 6 "Custom_Mode_6" 7 "Custom_Mode_7" ;
VAL_ 1275 OffRdMdSndVisDispVal 0 "Setting_Unknown" 1 "Custom_Mode_1" 2 "Custom_Mode_2" 3 "Custom_Mode_3" 4 "Custom_Mode_4" 5 "Custom_Mode_5" 6 "Custom_Mode_6" 7 "Custom_Mode_7" ;
VAL_ 1275 OffRdMdRideHghtVisDispVal 0 "Setting_Unknown" 1 "Custom_Mode_1" 2 "Custom_Mode_2" 3 "Custom_Mode_3" 4 "Custom_Mode_4" 5 "Custom_Mode_5" 6 "Custom_Mode_6" 7 "Custom_Mode_7" ;
VAL_ 1275 OffRdMdPwrtrnVisDispVal 0 "Setting_Unknown" 1 "Custom_Mode_1" 2 "Custom_Mode_2" 3 "Custom_Mode_3" 4 "Custom_Mode_4" 5 "Custom_Mode_5" 6 "Custom_Mode_6" 7 "Custom_Mode_7" ;
VAL_ 1275 OffRdMdStrgVisDispVal 0 "Setting_Unknown" 1 "Custom_Mode_1" 2 "Custom_Mode_2" 3 "Custom_Mode_3" 4 "Custom_Mode_4" 5 "Custom_Mode_5" 6 "Custom_Mode_6" 7 "Custom_Mode_7" ;
VAL_ 1275 OffRdMdSpnsnVisDispVal 0 "Setting_Unknown" 1 "Custom_Mode_1" 2 "Custom_Mode_2" 3 "Custom_Mode_3" 4 "Custom_Mode_4" 5 "Custom_Mode_5" 6 "Custom_Mode_6" 7 "Custom_Mode_7" ;
VAL_ 1275 ESCInitIO 0 "FALSE" 1 "TRUE" ;
VAL_ 1275 ESCCmptMdIO 0 "FALSE" 1 "TRUE" ;
VAL_ 1275 TrlrBrkgSysProfSts 0 "Default Profile" 1 "Profile 1" 2 "Profile 2" 3 "Profile 3" 4 "Profile 4" 5 "Profile 5" ;
VAL_ 1275 PerfMdMainMenuTy 0 "No_Action" 1 "Main Menu Type 1" 2 "Main Menu Type 2" 3 "Main Menu Type 3" 4 "Main Menu Type 4" 5 "Main Menu Type 5" 6 "Main Menu Type 6" 7 "Main Menu Type 7" ;
VAL_ 1275 TrlrBrkCnctdIndOn 0 "FALSE" 1 "TRUE" ;
VAL_ 1275 SrvESCMdIO 0 "FALSE" 1 "TRUE" ;
VAL_ 1275 ServTracCtlIndOn 0 "FALSE" 1 "TRUE" ;
VAL_ 1275 RdcBrkgToAvoidOvrhtgIndOn 0 "FALSE" 1 "TRUE" ;
VAL_ 1275 HillStrtAstActIO 0 "FALSE" 1 "TRUE" ;
VAL_ 1275 HillRollCntrlActIO 0 "FALSE" 1 "TRUE" ;
VAL_ 1275 ESCPrfMdIO 0 "FALSE" 1 "TRUE" ;
VAL_ 1275 ESCOffIO 0 "FALSE" 1 "TRUE" ;
VAL_ 1275 BrkSysDrftModeUnvWrnIndReq 0 "None" 1 "In Terrain Mode" 2 "Generic" ;
VAL_ 1275 BrkSysDrftModeDispSts 0 "None" 1 "Pending" 2 "On" 3 "Off" ;
VAL_ 1275 BrkSysDrftModeSeltnIndOn 0 "FALSE" 1 "TRUE" ;
VAL_ 1274 BrkPadLifeFrt_Inv 0 "FALSE" 1 "TRUE" ;
VAL_ 1274 BrkPadLifeRr_Inv 0 "FALSE" 1 "TRUE" ;
VAL_ 1274 TowHaulMdBrkPedVisDispVal 0 "Setting_Unknown" 1 "Custom_Mode_1" 2 "Custom_Mode_2" 3 "Custom_Mode_3" 4 "Custom_Mode_4" 5 "Custom_Mode_5" 6 "Custom_Mode_6" 7 "Custom_Mode_7" ;
VAL_ 1274 TowHaulMdActvAerodynsVisDispVal 0 "Setting_Unknown" 1 "Custom_Mode_1" 2 "Custom_Mode_2" 3 "Custom_Mode_3" 4 "Custom_Mode_4" 5 "Custom_Mode_5" 6 "Custom_Mode_6" 7 "Custom_Mode_7" ;
VAL_ 1274 BrkTempStsIndReq 0 "No Action" 1 "Normal" 2 "Warm" 3 "Hot" 4 "Overheated" ;
VAL_ 1274 TowHaulMdPwrtrnVisDispVal 0 "Setting_Unknown" 1 "Custom_Mode_1" 2 "Custom_Mode_2" 3 "Custom_Mode_3" 4 "Custom_Mode_4" 5 "Custom_Mode_5" 6 "Custom_Mode_6" 7 "Custom_Mode_7" ;
VAL_ 1274 TowHaulMdESCVisDispVal 0 "Setting_Unknown" 1 "Custom_Mode_1" 2 "Custom_Mode_2" 3 "Custom_Mode_3" 4 "Custom_Mode_4" 5 "Custom_Mode_5" 6 "Custom_Mode_6" 7 "Custom_Mode_7" ;
VAL_ 1274 TowHaulMdDrvlnVisDispVal 0 "Setting_Unknown" 1 "Custom_Mode_1" 2 "Custom_Mode_2" 3 "Custom_Mode_3" 4 "Custom_Mode_4" 5 "Custom_Mode_5" 6 "Custom_Mode_6" 7 "Custom_Mode_7" ;
VAL_ 1274 TowHaulMdSndVisDispVal 0 "Setting_Unknown" 1 "Custom_Mode_1" 2 "Custom_Mode_2" 3 "Custom_Mode_3" 4 "Custom_Mode_4" 5 "Custom_Mode_5" 6 "Custom_Mode_6" 7 "Custom_Mode_7" ;
VAL_ 1274 TowHaulMdRideHghtVisDispVal 0 "Setting_Unknown" 1 "Custom_Mode_1" 2 "Custom_Mode_2" 3 "Custom_Mode_3" 4 "Custom_Mode_4" 5 "Custom_Mode_5" 6 "Custom_Mode_6" 7 "Custom_Mode_7" ;
VAL_ 1274 AutoHldActv 0 "FALSE" 1 "TRUE" ;
VAL_ 1274 ABSActvIndOn 0 "FALSE" 1 "TRUE" ;
VAL_ 1274 TowHaulMdStrgVisDispVal 0 "Setting_Unknown" 1 "Custom_Mode_1" 2 "Custom_Mode_2" 3 "Custom_Mode_3" 4 "Custom_Mode_4" 5 "Custom_Mode_5" 6 "Custom_Mode_6" 7 "Custom_Mode_7" ;
VAL_ 1274 TowHaulMdSpnsnVisDispVal 0 "Setting_Unknown" 1 "Custom_Mode_1" 2 "Custom_Mode_2" 3 "Custom_Mode_3" 4 "Custom_Mode_4" 5 "Custom_Mode_5" 6 "Custom_Mode_6" 7 "Custom_Mode_7" ;
VAL_ 1274 BrkPadLifeRrRstAval 0 "FALSE" 1 "TRUE" ;
VAL_ 1274 BrkPadLifeFrtRstAval 0 "FALSE" 1 "TRUE" ;
VAL_ 1274 AutoHldServIndOn 0 "FALSE" 1 "TRUE" ;
VAL_ 1274 AutoHldDsbldStBltIndOn 0 "FALSE" 1 "TRUE" ;
VAL_ 1274 AutoHldDsbldDrOpnIndOn 0 "FALSE" 1 "TRUE" ;
VAL_ 1274 AutoHldAppBrkPedIndOn 0 "FALSE" 1 "TRUE" ;
VAL_ 1491 CustMdDrvlCstmCurSetVal 0 "SETTING_UNKNOWN" 1 "CUSTOM_MODE_1" 2 "CUSTOM_MODE_2" 3 "CUSTOM_MODE_3" 4 "CUSTOM_MODE_4" 5 "CUSTOM_MODE_5" 6 "CUSTOM_MODE_6" 7 "CUSTOM_MODE_7" ;
VAL_ 1491 CustMdBrkPdlCstmCurSetVal 0 "SETTING_UNKNOWN" 1 "CUSTOM_MODE_1" 2 "CUSTOM_MODE_2" 3 "CUSTOM_MODE_3" 4 "CUSTOM_MODE_4" 5 "CUSTOM_MODE_5" 6 "CUSTOM_MODE_6" 7 "CUSTOM_MODE_7" ;
VAL_ 1491 CustMdActAeroCstmCurSetVal 0 "SETTING_UNKNOWN" 1 "CUSTOM_MODE_1" 2 "CUSTOM_MODE_2" 3 "CUSTOM_MODE_3" 4 "CUSTOM_MODE_4" 5 "CUSTOM_MODE_5" 6 "CUSTOM_MODE_6" 7 "CUSTOM_MODE_7" ;
VAL_ 1491 CustMdRideHghtCstmCurSetVal 0 "SETTING_UNKNOWN" 1 "CUSTOM_MODE_1" 2 "CUSTOM_MODE_2" 3 "CUSTOM_MODE_3" 4 "CUSTOM_MODE_4" 5 "CUSTOM_MODE_5" 6 "CUSTOM_MODE_6" 7 "CUSTOM_MODE_7" ;
VAL_ 1491 CustMdPTCstmPndSetVal 0 "SETTING_UNKNOWN" 1 "CUSTOM_MODE_1" 2 "CUSTOM_MODE_2" 3 "CUSTOM_MODE_3" 4 "CUSTOM_MODE_4" 5 "CUSTOM_MODE_5" 6 "CUSTOM_MODE_6" 7 "CUSTOM_MODE_7" ;
VAL_ 1491 CustMdPTCstmCurSetVal 0 "SETTING_UNKNOWN" 1 "CUSTOM_MODE_1" 2 "CUSTOM_MODE_2" 3 "CUSTOM_MODE_3" 4 "CUSTOM_MODE_4" 5 "CUSTOM_MODE_5" 6 "CUSTOM_MODE_6" 7 "CUSTOM_MODE_7" ;
VAL_ 1491 CustMdSpnCstmCurSetVal 0 "SETTING_UNKNOWN" 1 "CUSTOM_MODE_1" 2 "CUSTOM_MODE_2" 3 "CUSTOM_MODE_3" 4 "CUSTOM_MODE_4" 5 "CUSTOM_MODE_5" 6 "CUSTOM_MODE_6" 7 "CUSTOM_MODE_7" ;
VAL_ 1491 CustMdSndCstmCurSetVal 0 "SETTING_UNKNOWN" 1 "CUSTOM_MODE_1" 2 "CUSTOM_MODE_2" 3 "CUSTOM_MODE_3" 4 "CUSTOM_MODE_4" 5 "CUSTOM_MODE_5" 6 "CUSTOM_MODE_6" 7 "CUSTOM_MODE_7" ;
VAL_ 1491 DisPrfMdRq 0 "No Action" 1 "Normal" 2 "Tour" 3 "Sport" 4 "Track" 5 "Performance Mode 5" 6 "Performance Mode 6" 7 "Performance Mode 7" ;
VAL_ 1491 CustMdTrcStbCstmCurSetVal 0 "SETTING_UNKNOWN" 1 "CUSTOM_MODE_1" 2 "CUSTOM_MODE_2" 3 "CUSTOM_MODE_3" 4 "CUSTOM_MODE_4" 5 "CUSTOM_MODE_5" 6 "CUSTOM_MODE_6" 7 "CUSTOM_MODE_7" ;
VAL_ 1491 CustMdStrCstmCurSetVal 0 "SETTING_UNKNOWN" 1 "CUSTOM_MODE_1" 2 "CUSTOM_MODE_2" 3 "CUSTOM_MODE_3" 4 "CUSTOM_MODE_4" 5 "CUSTOM_MODE_5" 6 "CUSTOM_MODE_6" 7 "CUSTOM_MODE_7" ;
VAL_ 1491 PrsnlMdBrkPdlCstmCurSetVal 0 "SETTING_UNKNOWN" 1 "PERSONAL_MODE_1" 2 "PERSONAL_MODE_2" 3 "PERSONAL_MODE_3" 4 "PERSONAL_MODE_4" 5 "PERSONAL_MODE_5" 6 "PERSONAL_MODE_6" 7 "PERSONAL_MODE_7" ;
VAL_ 1491 PrsnlMdActAeroCstmCurSetVal 0 "SETTING_UNKNOWN" 1 "PERSONAL_MODE_1" 2 "PERSONAL_MODE_2" 3 "PERSONAL_MODE_3" 4 "PERSONAL_MODE_4" 5 "PERSONAL_MODE_5" 6 "PERSONAL_MODE_6" 7 "PERSONAL_MODE_7" ;
VAL_ 1491 ExtdHillStrtAstCustCurSetVal 0 "SETTING_UNKNOWN" 1 "EXTENDED_HOLD" 2 "STANDARD_HOLD" 3 "RESERVED_3" 4 "RESERVED_4" 5 "RESERVED_5" 6 "RESERVED_6" 7 "RESERVED_7" ;
VAL_ 1491 PrsnlMdRideHghtCstmCurSetVal 0 "SETTING_UNKNOWN" 1 "PERSONAL_MODE_1" 2 "PERSONAL_MODE_2" 3 "PERSONAL_MODE_3" 4 "PERSONAL_MODE_4" 5 "PERSONAL_MODE_5" 6 "PERSONAL_MODE_6" 7 "PERSONAL_MODE_7" ;
VAL_ 1491 PrsnlMdDrvlCstmCurSetVal 0 "SETTING_UNKNOWN" 1 "PERSONAL_MODE_1" 2 "PERSONAL_MODE_2" 3 "PERSONAL_MODE_3" 4 "PERSONAL_MODE_4" 5 "PERSONAL_MODE_5" 6 "PERSONAL_MODE_6" 7 "PERSONAL_MODE_7" ;
VAL_ 1491 CustMdStrCstmSetAv 0 "FALSE" 1 "TRUE" ;
VAL_ 1491 CustMdSpnCstmSetAv 0 "FALSE" 1 "TRUE" ;
VAL_ 1491 CustMdSndCstmSetAv 0 "FALSE" 1 "TRUE" ;
VAL_ 1491 CustMdRideHghtCstmSetAv 0 "FALSE" 1 "TRUE" ;
VAL_ 1491 CustMdPTCstmSetAv 0 "FALSE" 1 "TRUE" ;
VAL_ 1491 CustMdDrvlCstmSetAv 0 "FALSE" 1 "TRUE" ;
VAL_ 1491 CustMdBrkPdlCstmSetAv 0 "FALSE" 1 "TRUE" ;
VAL_ 1491 CustMdActAeroCstmSetAv 0 "FALSE" 1 "TRUE" ;
VAL_ 1491 PrsnlMdSpnCstmSetAv 0 "FALSE" 1 "TRUE" ;
VAL_ 1491 PrsnlMdSndCstmSetAv 0 "FALSE" 1 "TRUE" ;
VAL_ 1491 PrsnlMdRideHghtCstmSetAv 0 "FALSE" 1 "TRUE" ;
VAL_ 1491 PrsnlMdDrvlCstmSetAv 0 "FALSE" 1 "TRUE" ;
VAL_ 1491 PrsnlMdBrkPdlCstmSetAv 0 "FALSE" 1 "TRUE" ;
VAL_ 1491 PrsnlMdActAeroCstmSetAv 0 "FALSE" 1 "TRUE" ;
VAL_ 1491 ExtdHillStrtAstCustSetAvl 0 "FALSE" 1 "TRUE" ;
VAL_ 1491 CustMdTrcStbCstmSetAv 0 "FALSE" 1 "TRUE" ;
VAL_ 1882 CustMdBrkPdlCstmAvFlg1 0 "FALSE" 1 "TRUE" ;
VAL_ 1882 CustMdActAeroCstmAvFlg7 0 "FALSE" 1 "TRUE" ;
VAL_ 1882 CustMdActAeroCstmAvFlg6 0 "FALSE" 1 "TRUE" ;
VAL_ 1882 CustMdActAeroCstmAvFlg5 0 "FALSE" 1 "TRUE" ;
VAL_ 1882 CustMdActAeroCstmAvFlg4 0 "FALSE" 1 "TRUE" ;
VAL_ 1882 CustMdActAeroCstmAvFlg3 0 "FALSE" 1 "TRUE" ;
VAL_ 1882 CustMdActAeroCstmAvFlg2 0 "FALSE" 1 "TRUE" ;
VAL_ 1882 CustMdActAeroCstmAvFlg1 0 "FALSE" 1 "TRUE" ;
VAL_ 1882 CustMdDrvlCstmAvFlg2 0 "FALSE" 1 "TRUE" ;
VAL_ 1882 CustMdDrvlCstmAvFlg1 0 "FALSE" 1 "TRUE" ;
VAL_ 1882 CustMdBrkPdlCstmAvFlg7 0 "FALSE" 1 "TRUE" ;
VAL_ 1882 CustMdBrkPdlCstmAvFlg6 0 "FALSE" 1 "TRUE" ;
VAL_ 1882 CustMdBrkPdlCstmAvFlg5 0 "FALSE" 1 "TRUE" ;
VAL_ 1882 CustMdBrkPdlCstmAvFlg4 0 "FALSE" 1 "TRUE" ;
VAL_ 1882 CustMdBrkPdlCstmAvFlg3 0 "FALSE" 1 "TRUE" ;
VAL_ 1882 CustMdBrkPdlCstmAvFlg2 0 "FALSE" 1 "TRUE" ;
VAL_ 1882 CustMdPTCstmAvFlg3 0 "FALSE" 1 "TRUE" ;
VAL_ 1882 CustMdPTCstmAvFlg2 0 "FALSE" 1 "TRUE" ;
VAL_ 1882 CustMdPTCstmAvFlg1 0 "FALSE" 1 "TRUE" ;
VAL_ 1882 CustMdDrvlCstmAvFlg7 0 "FALSE" 1 "TRUE" ;
VAL_ 1882 CustMdDrvlCstmAvFlg6 0 "FALSE" 1 "TRUE" ;
VAL_ 1882 CustMdDrvlCstmAvFlg5 0 "FALSE" 1 "TRUE" ;
VAL_ 1882 CustMdDrvlCstmAvFlg4 0 "FALSE" 1 "TRUE" ;
VAL_ 1882 CustMdDrvlCstmAvFlg3 0 "FALSE" 1 "TRUE" ;
VAL_ 1882 CustMdRideHghtCstmAvFlg4 0 "FALSE" 1 "TRUE" ;
VAL_ 1882 CustMdRideHghtCstmAvFlg3 0 "FALSE" 1 "TRUE" ;
VAL_ 1882 CustMdRideHghtCstmAvFlg2 0 "FALSE" 1 "TRUE" ;
VAL_ 1882 CustMdRideHghtCstmAvFlg1 0 "FALSE" 1 "TRUE" ;
VAL_ 1882 CustMdPTCstmAvFlg7 0 "FALSE" 1 "TRUE" ;
VAL_ 1882 CustMdPTCstmAvFlg6 0 "FALSE" 1 "TRUE" ;
VAL_ 1882 CustMdPTCstmAvFlg5 0 "FALSE" 1 "TRUE" ;
VAL_ 1882 CustMdPTCstmAvFlg4 0 "FALSE" 1 "TRUE" ;
VAL_ 1882 CustMdSndCstmAvFlg5 0 "FALSE" 1 "TRUE" ;
VAL_ 1882 CustMdSndCstmAvFlg4 0 "FALSE" 1 "TRUE" ;
VAL_ 1882 CustMdSndCstmAvFlg3 0 "FALSE" 1 "TRUE" ;
VAL_ 1882 CustMdSndCstmAvFlg2 0 "FALSE" 1 "TRUE" ;
VAL_ 1882 CustMdSndCstmAvFlg1 0 "FALSE" 1 "TRUE" ;
VAL_ 1882 CustMdRideHghtCstmAvFlg7 0 "FALSE" 1 "TRUE" ;
VAL_ 1882 CustMdRideHghtCstmAvFlg6 0 "FALSE" 1 "TRUE" ;
VAL_ 1882 CustMdRideHghtCstmAvFlg5 0 "FALSE" 1 "TRUE" ;
VAL_ 1882 CustMdSpnCstmAvFlg6 0 "FALSE" 1 "TRUE" ;
VAL_ 1882 CustMdSpnCstmAvFlg5 0 "FALSE" 1 "TRUE" ;
VAL_ 1882 CustMdSpnCstmAvFlg4 0 "FALSE" 1 "TRUE" ;
VAL_ 1882 CustMdSpnCstmAvFlg3 0 "FALSE" 1 "TRUE" ;
VAL_ 1882 CustMdSpnCstmAvFlg2 0 "FALSE" 1 "TRUE" ;
VAL_ 1882 CustMdSpnCstmAvFlg1 0 "FALSE" 1 "TRUE" ;
VAL_ 1882 CustMdSndCstmAvFlg7 0 "FALSE" 1 "TRUE" ;
VAL_ 1882 CustMdSndCstmAvFlg6 0 "FALSE" 1 "TRUE" ;
VAL_ 1882 CustMdStrCstmAvFlg7 0 "FALSE" 1 "TRUE" ;
VAL_ 1882 CustMdStrCstmAvFlg6 0 "FALSE" 1 "TRUE" ;
VAL_ 1882 CustMdStrCstmAvFlg5 0 "FALSE" 1 "TRUE" ;
VAL_ 1882 CustMdStrCstmAvFlg4 0 "FALSE" 1 "TRUE" ;
VAL_ 1882 CustMdStrCstmAvFlg3 0 "FALSE" 1 "TRUE" ;
VAL_ 1882 CustMdStrCstmAvFlg2 0 "FALSE" 1 "TRUE" ;
VAL_ 1882 CustMdStrCstmAvFlg1 0 "FALSE" 1 "TRUE" ;
VAL_ 1882 CustMdSpnCstmAvFlg7 0 "FALSE" 1 "TRUE" ;
VAL_ 1882 EBDFld 0 "FALSE" 1 "TRUE" ;
VAL_ 1882 CustMdTrcStbCstmAvFlg7 0 "FALSE" 1 "TRUE" ;
VAL_ 1882 CustMdTrcStbCstmAvFlg6 0 "FALSE" 1 "TRUE" ;
VAL_ 1882 CustMdTrcStbCstmAvFlg5 0 "FALSE" 1 "TRUE" ;
VAL_ 1882 CustMdTrcStbCstmAvFlg4 0 "FALSE" 1 "TRUE" ;
VAL_ 1882 CustMdTrcStbCstmAvFlg3 0 "FALSE" 1 "TRUE" ;
VAL_ 1882 CustMdTrcStbCstmAvFlg2 0 "FALSE" 1 "TRUE" ;
VAL_ 1882 CustMdTrcStbCstmAvFlg1 0 "FALSE" 1 "TRUE" ;
VAL_ 1183 PrsnlMdActAeroCstmAvFlg1 0 "FALSE" 1 "TRUE" ;
VAL_ 1183 ExtdHillStrtAstCustAvlFlg7 0 "FALSE" 1 "TRUE" ;
VAL_ 1183 ExtdHillStrtAstCustAvlFlg6 0 "FALSE" 1 "TRUE" ;
VAL_ 1183 ExtdHillStrtAstCustAvlFlg5 0 "FALSE" 1 "TRUE" ;
VAL_ 1183 ExtdHillStrtAstCustAvlFlg4 0 "FALSE" 1 "TRUE" ;
VAL_ 1183 ExtdHillStrtAstCustAvlFlg3 0 "FALSE" 1 "TRUE" ;
VAL_ 1183 ExtdHillStrtAstCustAvlFlg2 0 "FALSE" 1 "TRUE" ;
VAL_ 1183 ExtdHillStrtAstCustAvlFlg1 0 "FALSE" 1 "TRUE" ;
VAL_ 1183 PrsnlMdBrkPdlCstmAvFlg2 0 "FALSE" 1 "TRUE" ;
VAL_ 1183 PrsnlMdBrkPdlCstmAvFlg1 0 "FALSE" 1 "TRUE" ;
VAL_ 1183 PrsnlMdActAeroCstmAvFlg7 0 "FALSE" 1 "TRUE" ;
VAL_ 1183 PrsnlMdActAeroCstmAvFlg6 0 "FALSE" 1 "TRUE" ;
VAL_ 1183 PrsnlMdActAeroCstmAvFlg5 0 "FALSE" 1 "TRUE" ;
VAL_ 1183 PrsnlMdActAeroCstmAvFlg4 0 "FALSE" 1 "TRUE" ;
VAL_ 1183 PrsnlMdActAeroCstmAvFlg3 0 "FALSE" 1 "TRUE" ;
VAL_ 1183 PrsnlMdActAeroCstmAvFlg2 0 "FALSE" 1 "TRUE" ;
VAL_ 1183 PrsnlMdDrvlCstmAvFlg3 0 "FALSE" 1 "TRUE" ;
VAL_ 1183 PrsnlMdDrvlCstmAvFlg2 0 "FALSE" 1 "TRUE" ;
VAL_ 1183 PrsnlMdDrvlCstmAvFlg1 0 "FALSE" 1 "TRUE" ;
VAL_ 1183 PrsnlMdBrkPdlCstmAvFlg7 0 "FALSE" 1 "TRUE" ;
VAL_ 1183 PrsnlMdBrkPdlCstmAvFlg6 0 "FALSE" 1 "TRUE" ;
VAL_ 1183 PrsnlMdBrkPdlCstmAvFlg5 0 "FALSE" 1 "TRUE" ;
VAL_ 1183 PrsnlMdBrkPdlCstmAvFlg4 0 "FALSE" 1 "TRUE" ;
VAL_ 1183 PrsnlMdBrkPdlCstmAvFlg3 0 "FALSE" 1 "TRUE" ;
VAL_ 1183 PrsnlMdRideHghtCstmAvFlg4 0 "FALSE" 1 "TRUE" ;
VAL_ 1183 PrsnlMdRideHghtCstmAvFlg3 0 "FALSE" 1 "TRUE" ;
VAL_ 1183 PrsnlMdRideHghtCstmAvFlg2 0 "FALSE" 1 "TRUE" ;
VAL_ 1183 PrsnlMdRideHghtCstmAvFlg1 0 "FALSE" 1 "TRUE" ;
VAL_ 1183 PrsnlMdDrvlCstmAvFlg7 0 "FALSE" 1 "TRUE" ;
VAL_ 1183 PrsnlMdDrvlCstmAvFlg6 0 "FALSE" 1 "TRUE" ;
VAL_ 1183 PrsnlMdDrvlCstmAvFlg5 0 "FALSE" 1 "TRUE" ;
VAL_ 1183 PrsnlMdDrvlCstmAvFlg4 0 "FALSE" 1 "TRUE" ;
VAL_ 1183 PrsnlMdSndCstmAvFlg5 0 "FALSE" 1 "TRUE" ;
VAL_ 1183 PrsnlMdSndCstmAvFlg4 0 "FALSE" 1 "TRUE" ;
VAL_ 1183 PrsnlMdSndCstmAvFlg3 0 "FALSE" 1 "TRUE" ;
VAL_ 1183 PrsnlMdSndCstmAvFlg2 0 "FALSE" 1 "TRUE" ;
VAL_ 1183 PrsnlMdSndCstmAvFlg1 0 "FALSE" 1 "TRUE" ;
VAL_ 1183 PrsnlMdRideHghtCstmAvFlg7 0 "FALSE" 1 "TRUE" ;
VAL_ 1183 PrsnlMdRideHghtCstmAvFlg6 0 "FALSE" 1 "TRUE" ;
VAL_ 1183 PrsnlMdRideHghtCstmAvFlg5 0 "FALSE" 1 "TRUE" ;
VAL_ 1183 PrsnlMdSpnCstmAvFlg6 0 "FALSE" 1 "TRUE" ;
VAL_ 1183 PrsnlMdSpnCstmAvFlg5 0 "FALSE" 1 "TRUE" ;
VAL_ 1183 PrsnlMdSpnCstmAvFlg4 0 "FALSE" 1 "TRUE" ;
VAL_ 1183 PrsnlMdSpnCstmAvFlg3 0 "FALSE" 1 "TRUE" ;
VAL_ 1183 PrsnlMdSpnCstmAvFlg2 0 "FALSE" 1 "TRUE" ;
VAL_ 1183 PrsnlMdSpnCstmAvFlg1 0 "FALSE" 1 "TRUE" ;
VAL_ 1183 PrsnlMdSndCstmAvFlg7 0 "FALSE" 1 "TRUE" ;
VAL_ 1183 PrsnlMdSndCstmAvFlg6 0 "FALSE" 1 "TRUE" ;
VAL_ 1183 PrsnlMdStrCstmAvFlg7 0 "FALSE" 1 "TRUE" ;
VAL_ 1183 PrsnlMdStrCstmAvFlg6 0 "FALSE" 1 "TRUE" ;
VAL_ 1183 PrsnlMdStrCstmAvFlg5 0 "FALSE" 1 "TRUE" ;
VAL_ 1183 PrsnlMdStrCstmAvFlg4 0 "FALSE" 1 "TRUE" ;
VAL_ 1183 PrsnlMdStrCstmAvFlg3 0 "FALSE" 1 "TRUE" ;
VAL_ 1183 PrsnlMdStrCstmAvFlg2 0 "FALSE" 1 "TRUE" ;
VAL_ 1183 PrsnlMdStrCstmAvFlg1 0 "FALSE" 1 "TRUE" ;
VAL_ 1183 PrsnlMdSpnCstmAvFlg7 0 "FALSE" 1 "TRUE" ;
VAL_ 1932 RdHgtWrn3IndReq 0 "No Indication" 1 "Car Show Unavailable" 2 "Car Show Requested" 3 "Car Show Cancelled" 4 "Cargo Height Active" ;
VAL_ 1793 SGI_ServStSysIndOn 0 "FALSE" 1 "TRUE" ;
VAL_ 1809 StLckoutRRCtlCurrSet 0 "Unknown" 1 "Locked Out" 2 "Not Locked Out" ;
VAL_ 1809 StLckoutRRVirtCtlAval 0 "Not Available" 1 "Available" ;
VAL_ 1809 StMemRRVirtCtlStorAllwd 0 "Not Allowed" 1 "Allowed" ;
VAL_ 1809 StMemRRVirtCtlRclAllwd 0 "Not Allowed" 1 "Allowed" ;
VAL_ 1256 StLckoutLRCtlCurrSet 0 "Unknown" 1 "Locked Out" 2 "Not Locked Out" ;
VAL_ 1256 StLckoutLRVirtCtlAval 0 "Not Available" 1 "Available" ;
VAL_ 1256 StMemLRVirtCtlStorAllwd 0 "Not Allowed" 1 "Allowed" ;
VAL_ 1256 StMemLRVirtCtlRclAllwd 0 "Not Allowed" 1 "Allowed" ;
VAL_ 1513 RrClsrAjrStat 0 "FALSE" 1 "TRUE" ;
VAL_ 1513 RrClsrAjrStat_Inv 0 "FALSE" 1 "TRUE" ;
VAL_ 2000 StBkSdBolsLFVirtCtlAval 0 "Not Available" 1 "Available" ;
VAL_ 2000 StBkLumbVertLFVirtCtlAval 0 "Not Available" 1 "Available" ;
VAL_ 2000 StBkLumbHrztlLFVirtCtlAval 0 "Not Available" 1 "Available" ;
VAL_ 2000 StBkHrztlLFCtlFrmRrVirtCtlAval 0 "Not Available" 1 "Available" ;
VAL_ 2000 StBkHrztlLFCtlFrmFrtVirtCtlAval 0 "Not Available" 1 "Available" ;
VAL_ 2000 StHdrstVertLFVirtCtlAval 0 "Not Available" 1 "Available" ;
VAL_ 2000 StHdrstHrztlLFVirtCtlAval 0 "Not Available" 1 "Available" ;
VAL_ 2000 StCushSdBolsLFVirtCtlAval 0 "Not Available" 1 "Available" ;
VAL_ 2000 StCushRrVertLFVirtCtlAval 0 "Not Available" 1 "Available" ;
VAL_ 2000 StCushLgthHrztlLFVirtCtlAval 0 "Not Available" 1 "Available" ;
VAL_ 2000 StCushHrztlLFCtlFrmRrVirtCtlAvl 0 "Not Available" 1 "Available" ;
VAL_ 2000 StCushHrztlLFCtlFrmFrVirtCtlAvl 0 "Not Available" 1 "Available" ;
VAL_ 2000 StCushFrtVertLFVirtCtlAval 0 "Not Available" 1 "Available" ;
VAL_ 2000 StMasgTyp2LFVirtCtlAval 0 "Not Available" 1 "Available" ;
VAL_ 2000 StMasgTyp1LFVirtCtlAval 0 "Not Available" 1 "Available" ;
VAL_ 2000 StMasgTyp15LFVirtCtlAval 0 "Not Available" 1 "Available" ;
VAL_ 2000 StMasgTyp14LFVirtCtlAval 0 "Not Available" 1 "Available" ;
VAL_ 2000 StMasgTyp13LFVirtCtlAval 0 "Not Available" 1 "Available" ;
VAL_ 2000 StMasgTyp12LFVirtCtlAval 0 "Not Available" 1 "Available" ;
VAL_ 2000 StMasgTyp11LFVirtCtlAval 0 "Not Available" 1 "Available" ;
VAL_ 2000 StMasgTyp10LFVirtCtlAval 0 "Not Available" 1 "Available" ;
VAL_ 2000 StUpprShldrHrztlLFVirtCtlAval 0 "Not Available" 1 "Available" ;
VAL_ 2000 StMasgTyp9LFVirtCtlAval 0 "Not Available" 1 "Available" ;
VAL_ 2000 StMasgTyp8LFVirtCtlAval 0 "Not Available" 1 "Available" ;
VAL_ 2000 StMasgTyp7LFVirtCtlAval 0 "Not Available" 1 "Available" ;
VAL_ 2000 StMasgTyp6LFVirtCtlAval 0 "Not Available" 1 "Available" ;
VAL_ 2000 StMasgTyp5LFVirtCtlAval 0 "Not Available" 1 "Available" ;
VAL_ 2000 StMasgTyp4LFVirtCtlAval 0 "Not Available" 1 "Available" ;
VAL_ 2000 StMasgTyp3LFVirtCtlAval 0 "Not Available" 1 "Available" ;
VAL_ 2000 StMemLFVirtCtlNumofMemPstnsAval 0 "Not Available" 1 "One Positions" 2 "Two Positions" 3 "Three Positions" 4 "Four Positions" 5 "Five Positions" 6 "Six Positions" 7 "Seven Positions" 8 "Eight Positions" ;
VAL_ 2000 StMemLFVirtCtlNumofExtPstnsAval 0 "Not Available" 1 "One Positions" 2 "Two Positions" 3 "Three Positions" 4 "Four Positions" 5 "Five Positions" 6 "Six Positions" 7 "Seven Positions" 8 "Eight Positions" ;
VAL_ 2000 StBkHrztlLFCtlFrmFrtVirtCtlAlwd 0 "Not Allowed" 1 "Allowed" ;
VAL_ 2000 StMasgIntstyLFLstKnwnSet 0 "Massage Off" 1 "Intensity 1" 2 "Intensity 2" 3 "Intensity 3" 4 "Intensity 4" 5 "Intensity 5" 6 "Intensity 6" 7 "Intensity 7" ;
VAL_ 2000 StMasgTypLFLstKnwnSet 0 "Massage Off" 1 "Type 1" 2 "Type 2" 3 "Type 3" 4 "Type 4" 5 "Type 5" 6 "Type 6" 7 "Type 7" 8 "Type 8" 9 "Type 9" 10 "Type 10" 11 "Type 11" 12 "Type 12" 13 "Type 13" 14 "Type 14" 15 "Type 15" ;
VAL_ 2000 StCushLgthHrztlLFVirtCtlAllwd 0 "Not Allowed" 1 "Allowed" ;
VAL_ 2000 StCushHrztlLFCtlFrmRrVirCtlAlwd 0 "Not Allowed" 1 "Allowed" ;
VAL_ 2000 StCushHrztlLFCtlFrmFrVirCtlAlwd 0 "Not Allowed" 1 "Allowed" ;
VAL_ 2000 StCushFrtVertLFVirtCtlAllwd 0 "Not Allowed" 1 "Allowed" ;
VAL_ 2000 StBkSdBolsLFVirtCtlAllwd 0 "Not Allowed" 1 "Allowed" ;
VAL_ 2000 StBkLumbVertLFVirtCtlAllwd 0 "Not Allowed" 1 "Allowed" ;
VAL_ 2000 StBkLumbHrztlLFVirtCtlAllwd 0 "Not Allowed" 1 "Allowed" ;
VAL_ 2000 StBkHrztlLFCtlFrmRrVirtCtlAllwd 0 "Not Allowed" 1 "Allowed" ;
VAL_ 2000 StMemLFVirtCtlStorAllwd 0 "Not Allowed" 1 "Allowed" ;
VAL_ 2000 StMemLFVirtCtlRclAllwd 0 "Not Allowed" 1 "Allowed" ;
VAL_ 2000 StUpprShldrHrztlLFVirtCtlAllwd 0 "Not Allowed" 1 "Allowed" ;
VAL_ 2000 StMasgLFVirtCtlAllwd 0 "Not Allowed" 1 "Allowed" ;
VAL_ 2000 StHdrstVertLFVirtCtlAllwd 0 "Not Allowed" 1 "Allowed" ;
VAL_ 2000 StHdrstHrztlLFVirtCtlAllwd 0 "Not Allowed" 1 "Allowed" ;
VAL_ 2000 StCushSdBolsLFVirtCtlAllwd 0 "Not Allowed" 1 "Allowed" ;
VAL_ 2000 StCushRrVertLFVirtCtlAllwd 0 "Not Allowed" 1 "Allowed" ;
VAL_ 1985 DMBlkhdDrAutoClsTmCstSetAval 0 "FALSE" 1 "TRUE" ;
VAL_ 1985 DMBlkhdDrAutoClsTmCstAvlFlg7 0 "FALSE" 1 "TRUE" ;
VAL_ 1985 DMBlkhdDrAutoClsTmCstAvlFlg6 0 "FALSE" 1 "TRUE" ;
VAL_ 1985 DMBlkhdDrAutoClsTmCstAvlFlg5 0 "FALSE" 1 "TRUE" ;
VAL_ 1985 DMBlkhdDrAutoClsTmCstAvlFlg4 0 "FALSE" 1 "TRUE" ;
VAL_ 1985 DMBlkhdDrAutoClsTmCstAvlFlg3 0 "FALSE" 1 "TRUE" ;
VAL_ 1985 DMBlkhdDrAutoClsTmCstAvlFlg2 0 "FALSE" 1 "TRUE" ;
VAL_ 1985 DMBlkhdDrAutoClsTmCstAvlFlg1 0 "FALSE" 1 "TRUE" ;
VAL_ 1985 DMBlkhdDrOpnVehOffCstSetAval 0 "FALSE" 1 "TRUE" ;
VAL_ 1985 DMBlkhdDrOpnVehOffCstAvlFlg7 0 "FALSE" 1 "TRUE" ;
VAL_ 1985 DMBlkhdDrOpnVehOffCstAvlFlg6 0 "FALSE" 1 "TRUE" ;
VAL_ 1985 DMBlkhdDrOpnVehOffCstAvlFlg5 0 "FALSE" 1 "TRUE" ;
VAL_ 1985 DMBlkhdDrOpnVehOffCstAvlFlg4 0 "FALSE" 1 "TRUE" ;
VAL_ 1985 DMBlkhdDrOpnVehOffCstAvlFlg3 0 "FALSE" 1 "TRUE" ;
VAL_ 1985 DMBlkhdDrOpnVehOffCstAvlFlg2 0 "FALSE" 1 "TRUE" ;
VAL_ 1985 DMBlkhdDrOpnVehOffCstAvlFlg1 0 "FALSE" 1 "TRUE" ;
VAL_ 1985 BlkhdDrRmtActvnChmEvntStat 0 "No Action" 1 "Active" 2 "Cancel Chime" ;
VAL_ 1985 BlkhdDrLoclActvnChmEvntStat 0 "No Action" 1 "Active" 2 "Cancel Chime" ;
VAL_ 1985 BlkhdDrObstclChmEvntStat 0 "No Action" 1 "Active" 2 "Cancel Chime" ;
VAL_ 1985 DMBlkhdDrAutoClsTmCstCurrSetVal 0 "Setting Unknown" 1 "Standard" 2 "Extended" 3 "Keep Open" ;
VAL_ 1985 BlkhdDrServIndOn 0 "FALSE" 1 "TRUE" ;
VAL_ 1927 DMPDAutoClsTmRFCstSetAval 0 "FALSE" 1 "TRUE" ;
VAL_ 1927 DMPDAutoClsTmRFCstAvlFlg7 0 "FALSE" 1 "TRUE" ;
VAL_ 1927 DMPDAutoClsTmRFCstAvlFlg6 0 "FALSE" 1 "TRUE" ;
VAL_ 1927 DMPDAutoClsTmRFCstAvlFlg5 0 "FALSE" 1 "TRUE" ;
VAL_ 1927 DMPDAutoClsTmRFCstAvlFlg4 0 "FALSE" 1 "TRUE" ;
VAL_ 1927 DMPDAutoClsTmRFCstAvlFlg3 0 "FALSE" 1 "TRUE" ;
VAL_ 1927 DMPDAutoClsTmRFCstAvlFlg2 0 "FALSE" 1 "TRUE" ;
VAL_ 1927 DMPDAutoClsTmRFCstAvlFlg1 0 "FALSE" 1 "TRUE" ;
VAL_ 1927 DMPDClsOutofPrkRFCstSetAval 0 "FALSE" 1 "TRUE" ;
VAL_ 1927 DMPDClsOutofPrkRFCstAvlFlg7 0 "FALSE" 1 "TRUE" ;
VAL_ 1927 DMPDClsOutofPrkRFCstAvlFlg6 0 "FALSE" 1 "TRUE" ;
VAL_ 1927 DMPDClsOutofPrkRFCstAvlFlg5 0 "FALSE" 1 "TRUE" ;
VAL_ 1927 DMPDClsOutofPrkRFCstAvlFlg4 0 "FALSE" 1 "TRUE" ;
VAL_ 1927 DMPDClsOutofPrkRFCstAvlFlg3 0 "FALSE" 1 "TRUE" ;
VAL_ 1927 DMPDClsOutofPrkRFCstAvlFlg2 0 "FALSE" 1 "TRUE" ;
VAL_ 1927 DMPDClsOutofPrkRFCstAvlFlg1 0 "FALSE" 1 "TRUE" ;
VAL_ 1927 DMPDDOBlkhdDrOpnRFCstSetAval 0 "FALSE" 1 "TRUE" ;
VAL_ 1927 DMPDDOBlkhdDrOpnRFCstAvlFlg7 0 "FALSE" 1 "TRUE" ;
VAL_ 1927 DMPDDOBlkhdDrOpnRFCstAvlFlg6 0 "FALSE" 1 "TRUE" ;
VAL_ 1927 DMPDDOBlkhdDrOpnRFCstAvlFlg5 0 "FALSE" 1 "TRUE" ;
VAL_ 1927 DMPDDOBlkhdDrOpnRFCstAvlFlg4 0 "FALSE" 1 "TRUE" ;
VAL_ 1927 DMPDDOBlkhdDrOpnRFCstAvlFlg3 0 "FALSE" 1 "TRUE" ;
VAL_ 1927 DMPDDOBlkhdDrOpnRFCstAvlFlg2 0 "FALSE" 1 "TRUE" ;
VAL_ 1927 DMPDDOBlkhdDrOpnRFCstAvlFlg1 0 "FALSE" 1 "TRUE" ;
VAL_ 1927 SCAOOAByKeyFobRFCstSetAval 0 "FALSE" 1 "TRUE" ;
VAL_ 1927 SCAOOAByKeyFobRFCstAvlFlg7 0 "FALSE" 1 "TRUE" ;
VAL_ 1927 SCAOOAByKeyFobRFCstAvlFlg6 0 "FALSE" 1 "TRUE" ;
VAL_ 1927 SCAOOAByKeyFobRFCstAvlFlg5 0 "FALSE" 1 "TRUE" ;
VAL_ 1927 SCAOOAByKeyFobRFCstAvlFlg4 0 "FALSE" 1 "TRUE" ;
VAL_ 1927 SCAOOAByKeyFobRFCstAvlFlg3 0 "FALSE" 1 "TRUE" ;
VAL_ 1927 SCAOOAByKeyFobRFCstAvlFlg2 0 "FALSE" 1 "TRUE" ;
VAL_ 1927 SCAOOAByKeyFobRFCstAvlFlg1 0 "FALSE" 1 "TRUE" ;
VAL_ 1927 SCAOOAByVirtKeyRFCstSetAval 0 "FALSE" 1 "TRUE" ;
VAL_ 1927 SCAOOAByVirtKeyRFCstAvlFlg7 0 "FALSE" 1 "TRUE" ;
VAL_ 1927 SCAOOAByVirtKeyRFCstAvlFlg6 0 "FALSE" 1 "TRUE" ;
VAL_ 1927 SCAOOAByVirtKeyRFCstAvlFlg5 0 "FALSE" 1 "TRUE" ;
VAL_ 1927 SCAOOAByVirtKeyRFCstAvlFlg4 0 "FALSE" 1 "TRUE" ;
VAL_ 1927 SCAOOAByVirtKeyRFCstAvlFlg3 0 "FALSE" 1 "TRUE" ;
VAL_ 1927 SCAOOAByVirtKeyRFCstAvlFlg2 0 "FALSE" 1 "TRUE" ;
VAL_ 1927 SCAOOAByVirtKeyRFCstAvlFlg1 0 "FALSE" 1 "TRUE" ;
VAL_ 1927 SCAPDBrktoClsRFCstSetAval 0 "FALSE" 1 "TRUE" ;
VAL_ 1927 SCAPDBrktoClsRFCstAvlFlg7 0 "FALSE" 1 "TRUE" ;
VAL_ 1927 SCAPDBrktoClsRFCstAvlFlg6 0 "FALSE" 1 "TRUE" ;
VAL_ 1927 SCAPDBrktoClsRFCstAvlFlg5 0 "FALSE" 1 "TRUE" ;
VAL_ 1927 SCAPDBrktoClsRFCstAvlFlg4 0 "FALSE" 1 "TRUE" ;
VAL_ 1927 SCAPDBrktoClsRFCstAvlFlg3 0 "FALSE" 1 "TRUE" ;
VAL_ 1927 SCAPDBrktoClsRFCstAvlFlg2 0 "FALSE" 1 "TRUE" ;
VAL_ 1927 SCAPDBrktoClsRFCstAvlFlg1 0 "FALSE" 1 "TRUE" ;
VAL_ 1927 SCAPDBrktoClsRFCstCurrSetVal 0 "Setting Unknown" 1 "Off" 2 "On" ;
VAL_ 1927 DMPDClsOutofPrkRFCstCurrSetVal 0 "Setting Unknown" 1 "Off" 2 "On" ;
VAL_ 1927 DMPDAutoClsTmRFCstCurrSetVal 0 "Setting Unknown" 1 "Standard" 2 "Extended" 3 "Keep Open" ;
VAL_ 1927 SCAPwrDrMtnRFVirtCtlAval 0 "Not Available" 1 "Available" ;
VAL_ 1927 PwrSdClsrRFServIndOn 0 "FALSE" 1 "TRUE" ;
VAL_ 1927 PwrSdClsrRFBlckdIndOn 0 "FALSE" 1 "TRUE" ;
VAL_ 1927 SCAPwrDrMtnRFVirtCtlAllwd 0 "Not Allowed" 1 "Allowed" ;
VAL_ 1930 StMasgTyp11RFVirtCtlAval 0 "Not Available" 1 "Available" ;
VAL_ 1930 StMasgTyp10RFVirtCtlAval 0 "Not Available" 1 "Available" ;
VAL_ 1930 StHdrstVertRFVirtCtlAval 0 "Not Available" 1 "Available" ;
VAL_ 1930 StHdrstHrztlRFVirtCtlAval 0 "Not Available" 1 "Available" ;
VAL_ 1930 StCushSdBolsRFVirtCtlAval 0 "Not Available" 1 "Available" ;
VAL_ 1930 StCushRrVertRFVirtCtlAval 0 "Not Available" 1 "Available" ;
VAL_ 1930 StCushLgthHrztlRFVirtCtlAval 0 "Not Available" 1 "Available" ;
VAL_ 1930 StCushHrztlRFCtlFrmRrVirtCtlAvl 0 "Not Available" 1 "Available" ;
VAL_ 1930 StMasgTyp4RFVirtCtlAval 0 "Not Available" 1 "Available" ;
VAL_ 1930 StMasgTyp3RFVirtCtlAval 0 "Not Available" 1 "Available" ;
VAL_ 1930 StMasgTyp2RFVirtCtlAval 0 "Not Available" 1 "Available" ;
VAL_ 1930 StMasgTyp1RFVirtCtlAval 0 "Not Available" 1 "Available" ;
VAL_ 1930 StMasgTyp15RFVirtCtlAval 0 "Not Available" 1 "Available" ;
VAL_ 1930 StMasgTyp14RFVirtCtlAval 0 "Not Available" 1 "Available" ;
VAL_ 1930 StMasgTyp13RFVirtCtlAval 0 "Not Available" 1 "Available" ;
VAL_ 1930 StMasgTyp12RFVirtCtlAval 0 "Not Available" 1 "Available" ;
VAL_ 1930 StCushLgthHrztlRFVirtCtlAllwd 0 "Not Allowed" 1 "Allowed" ;
VAL_ 1930 StCushHrztlRFCtlFrmRrVirCtlAlwd 0 "Not Allowed" 1 "Allowed" ;
VAL_ 1930 StCushHrztlRFCtlFrmFrVirCtlAlwd 0 "Not Allowed" 1 "Allowed" ;
VAL_ 1930 StCushFrtVertRFVirtCtlAllwd 0 "Not Allowed" 1 "Allowed" ;
VAL_ 1930 StBkSdBolsRFVirtCtlAllwd 0 "Not Allowed" 1 "Allowed" ;
VAL_ 1930 StBkLumbVertRFVirtCtlAllwd 0 "Not Allowed" 1 "Allowed" ;
VAL_ 1930 StBkLumbHrztlRFVirtCtlAllwd 0 "Not Allowed" 1 "Allowed" ;
VAL_ 1930 StBkHrztlRFCtlFrmRrVirtCtlAllwd 0 "Not Allowed" 1 "Allowed" ;
VAL_ 1930 StMasgTypRFLstKnwnSet 0 "Massage Off" 1 "Type 1" 2 "Type 2" 3 "Type 3" 4 "Type 4" 5 "Type 5" 6 "Type 6" 7 "Type 7" 8 "Type 8" 9 "Type 9" 10 "Type 10" 11 "Type 11" 12 "Type 12" 13 "Type 13" 14 "Type 14" 15 "Type 15" ;
VAL_ 1930 StBkHrztlRFCtlFrmFrtVirtCtlAlwd 0 "Not Allowed" 1 "Allowed" ;
VAL_ 1930 StUpprShldrHrztlRFVirtCtlAllwd 0 "Not Allowed" 1 "Allowed" ;
VAL_ 1930 StMasgRFVirtCtlAllwd 0 "Not Allowed" 1 "Allowed" ;
VAL_ 1930 StHdrstVertRFVirtCtlAllwd 0 "Not Allowed" 1 "Allowed" ;
VAL_ 1930 StHdrstHrztlRFVirtCtlAllwd 0 "Not Allowed" 1 "Allowed" ;
VAL_ 1930 StCushSdBolsRFVirtCtlAllwd 0 "Not Allowed" 1 "Allowed" ;
VAL_ 1930 StCushRrVertRFVirtCtlAllwd 0 "Not Allowed" 1 "Allowed" ;
VAL_ 1930 StMemRFVirtCtlNumofExtPstnsAval 0 "Not Available" 1 "One Positions" 2 "Two Positions" 3 "Three Positions" 4 "Four Positions" 5 "Five Positions" 6 "Six Positions" 7 "Seven Positions" 8 "Eight Positions" ;
VAL_ 1930 StMasgIntstyRFLstKnwnSet 0 "Massage Off" 1 "Intensity 1" 2 "Intensity 2" 3 "Intensity 3" 4 "Intensity 4" 5 "Intensity 5" 6 "Intensity 6" 7 "Intensity 7" ;
VAL_ 1930 StMemRFVirtCtlNumofMemPstnsAval 0 "Not Available" 1 "One Positions" 2 "Two Positions" 3 "Three Positions" 4 "Four Positions" 5 "Five Positions" 6 "Six Positions" 7 "Seven Positions" 8 "Eight Positions" ;
VAL_ 1930 StCushHrztlRFCtlFrmFrtVirCtlAvl 0 "Not Available" 1 "Available" ;
VAL_ 1930 StCushFrtVertRFVirtCtlAval 0 "Not Available" 1 "Available" ;
VAL_ 1930 StBkSdBolsRFVirtCtlAval 0 "Not Available" 1 "Available" ;
VAL_ 1930 StBkLumbVertRFVirtCtlAval 0 "Not Available" 1 "Available" ;
VAL_ 1930 StBkLumbHrztlRFVirtCtlAval 0 "Not Available" 1 "Available" ;
VAL_ 1930 StBkHrztlRFCtlFrmRrVirtCtlAval 0 "Not Available" 1 "Available" ;
VAL_ 1930 StBkHrztlRFCtlFrmFrtVirtCtlAval 0 "Not Available" 1 "Available" ;
VAL_ 1930 StMemRFVirtCtlStorAllwd 0 "Not Allowed" 1 "Allowed" ;
VAL_ 1930 StMemRFVirtCtlRclAllwd 0 "Not Allowed" 1 "Allowed" ;
VAL_ 1930 StUpprShldrHrztlRFVirtCtlAval 0 "Not Available" 1 "Available" ;
VAL_ 1930 StMasgTyp9RFVirtCtlAval 0 "Not Available" 1 "Available" ;
VAL_ 1930 StMasgTyp8RFVirtCtlAval 0 "Not Available" 1 "Available" ;
VAL_ 1930 StMasgTyp7RFVirtCtlAval 0 "Not Available" 1 "Available" ;
VAL_ 1930 StMasgTyp6RFVirtCtlAval 0 "Not Available" 1 "Available" ;
VAL_ 1930 StMasgTyp5RFVirtCtlAval 0 "Not Available" 1 "Available" ;
